VERSION ""

NS_ :

BS_:

BU_: SMART_CORE
VAL_TABLE_ FIRST_TOUCH_COORDINATE_Y_IS 0 "Default Value" ;
VAL_TABLE_ FIRST_TOUCH_COORDINATE_X_IS 0 "Default Value" ;

BO_ 3221225472 VECTOR__INDEPENDENT_SIG_MSG: 0 Vector__XXX
 SG_ VCU_DRIVE_MODE : 0|3@1+ (1,0) [0|7] "" Vector__XXX
 SG_ VCU36_MSG_CNT : 0|4@1+ (1,0) [0|15] "" Vector__XXX
 SG_ FR_SEAT_HEAT_VENT_LEVEL_MBFM : 0|2@1+ (1,0) [0|3] "" Vector__XXX
 SG_ FL_SEAT_HEAT_VENT_LEVEL_MBFM : 0|2@1+ (1,0) [0|3] "" Vector__XXX

BO_ 445 ESC16_10: 7 Vector__XXX
 SG_ STS_ITA : 0|2@1+ (1,0) [0|3] ""  SMART_CORE
 SG_ ITA_ACTIVE : 2|1@1+ (1,0) [0|1] ""  SMART_CORE
 SG_ CCO_WARNING : 11|3@1+ (1,0) [0|7] ""  SMART_CORE
 SG_ CCO_SET_SPD : 8|3@1+ (1,0) [0|7] ""  SMART_CORE
 SG_ CCO_ACTIVE : 5|2@1+ (1,0) [0|3] ""  SMART_CORE

BO_ 1007 VCU15_100: 8 Vector__XXX
 SG_ VCU_TorqueCoasting : 32|16@1+ (0.0625,-2048) [-2045|2045] "Nm"  SMART_CORE
 SG_ VCU_SwitchS2 : 50|1@1+ (1,0) [0|1] ""  SMART_CORE
 SG_ VCU_StCreep : 49|1@1+ (1,0) [0|1] ""  SMART_CORE
 SG_ VCU_StCoasting : 48|1@1+ (1,0) [0|1] ""  SMART_CORE
 SG_ VCU_HVAccPowerConsumption : 16|16@1+ (0.001,0) [0|65] "Kw"  SMART_CORE
 SG_ VCU_EConsPerKm : 0|16@1+ (0.001,0) [0|65.535] "Kwh/km"  SMART_CORE

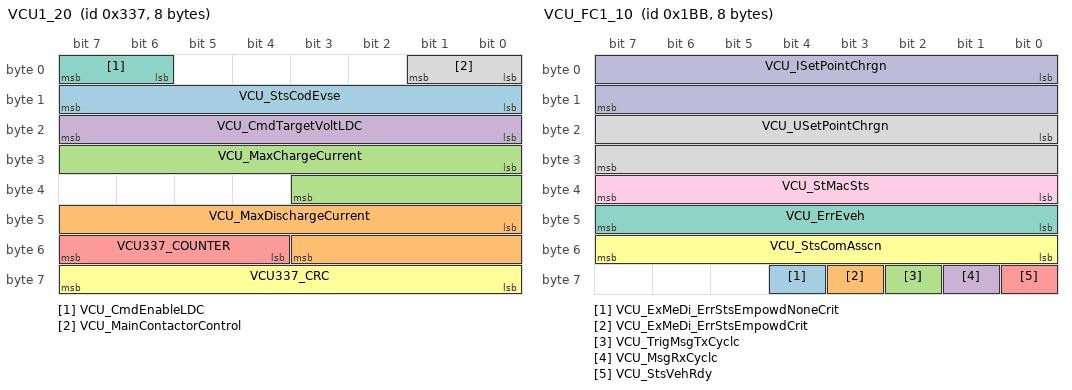
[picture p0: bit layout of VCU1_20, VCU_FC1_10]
BO_ 823 VCU1_20: 8 Vector__XXX
 SG_ VCU_StsCodEvse : 8|8@1+ (1,0) [0|255] ""  SMART_CORE
 SG_ VCU_MaxDischargeCurrent : 40|12@1+ (1,0) [0|4094] "A"  SMART_CORE
 SG_ VCU_MaxChargeCurrent : 24|12@1+ (1,0) [0|4094] "A"  SMART_CORE
 SG_ VCU_CmdTargetVoltLDC : 16|8@1+ (0.1,0) [0|25.5] "V"  SMART_CORE
 SG_ VCU337_COUNTER : 52|4@1+ (1,0) [0|15] "NA"  SMART_CORE
 SG_ VCU337_CRC : 56|8@1+ (1,0) [0|255] "NA"  SMART_CORE
 SG_ VCU_CmdEnableLDC : 6|2@1+ (1,0) [0|3] "NA"  SMART_CORE
 SG_ VCU_MainContactorControl : 0|2@1+ (1,0) [0|3] ""  SMART_CORE

BO_ 443 VCU_FC1_10: 8 Vector__XXX
 SG_ VCU_ExMeDi_ErrStsEmpowdNoneCrit : 60|1@1+ (1,0) [0|1] ""  SMART_CORE
 SG_ VCU_ExMeDi_ErrStsEmpowdCrit : 59|1@1+ (1,0) [0|1] ""  SMART_CORE
 SG_ VCU_TrigMsgTxCyclc : 58|1@1+ (1,0) [0|1] ""  SMART_CORE
 SG_ VCU_MsgRxCyclc : 57|1@1+ (1,0) [0|1] ""  SMART_CORE
 SG_ VCU_StsVehRdy : 56|1@1+ (1,0) [0|1] ""  SMART_CORE
 SG_ VCU_StsComAsscn : 48|8@1+ (1,0) [0|255] ""  SMART_CORE
 SG_ VCU_ErrEveh : 40|8@1+ (1,0) [0|255] ""  SMART_CORE
 SG_ VCU_USetPointChrgn : 16|16@1+ (0.1,0) [0|1500] "V"  SMART_CORE
 SG_ VCU_StMacSts : 32|8@1+ (1,0) [0|255] ""  SMART_CORE
 SG_ VCU_ISetPointChrgn : 0|16@1+ (0.1,0) [0|1000] "A"  SMART_CORE

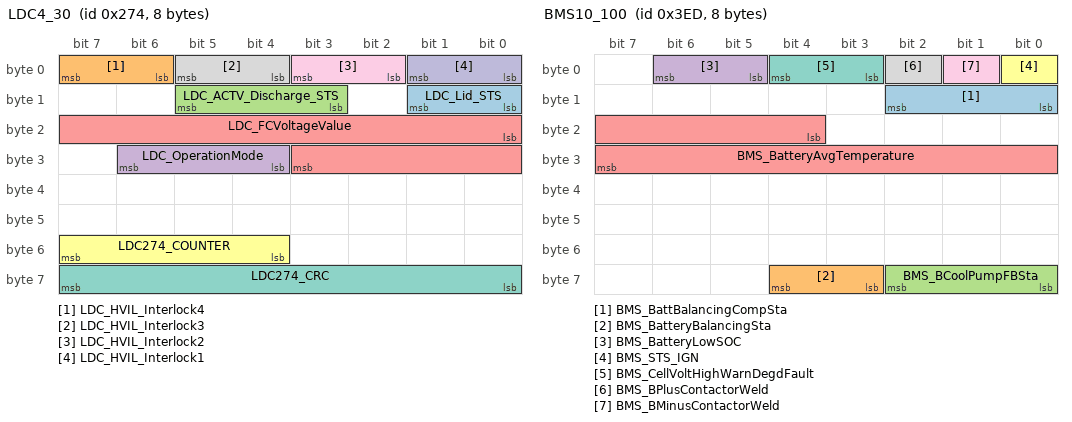
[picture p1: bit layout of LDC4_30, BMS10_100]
BO_ 628 LDC4_30: 8 Vector__XXX
 SG_ LDC_Lid_STS : 8|2@1+ (1,0) [0|3] ""  SMART_CORE
 SG_ LDC_HVIL_Interlock4 : 6|2@1+ (1,0) [0|3] "NA"  SMART_CORE
 SG_ LDC_ACTV_Discharge_STS : 11|3@1+ (1,0) [0|3] ""  SMART_CORE
 SG_ LDC_OperationMode : 28|3@1+ (1,0) [0|7] "NA"  SMART_CORE
 SG_ LDC_FCVoltageValue : 16|12@1+ (0.1,0) [0|500] "V"  SMART_CORE
 SG_ LDC274_COUNTER : 52|4@1+ (1,0) [0|14] "NA"  SMART_CORE
 SG_ LDC274_CRC : 56|8@1+ (1,0) [0|0] "NA"  SMART_CORE
 SG_ LDC_HVIL_Interlock3 : 4|2@1+ (1,0) [0|3] "NA"  SMART_CORE
 SG_ LDC_HVIL_Interlock2 : 2|2@1+ (1,0) [0|3] "NA"  SMART_CORE
 SG_ LDC_HVIL_Interlock1 : 0|2@1+ (1,0) [0|3] "NA"  SMART_CORE

BO_ 991 LDC3_100: 8 Vector__XXX
 SG_ LDC_OPV_Circuit_Error : 22|1@1+ (1,0) [0|1] ""  SMART_CORE
 SG_ LDC_Low_Temp_Shutdown : 23|1@1+ (1,0) [0|1] ""  SMART_CORE
 SG_ LDC_IPV_Circuit_Error : 21|1@1+ (1,0) [0|1] ""  SMART_CORE
 SG_ LDC_INTERNAL_FAIL : 20|1@1+ (1,0) [0|1] ""  SMART_CORE
 SG_ LDC_Input_Over_Current : 19|1@1+ (1,0) [0|1] ""  SMART_CORE
 SG_ LDC_Heat_Sink_Over_Temp_Shutdown : 2|1@1+ (1,0) [0|1] ""  SMART_CORE
 SG_ LDC_HVDC_Side_Relay_Sts : 52|1@1+ (1,0) [0|1] ""  SMART_CORE
 SG_ LDC_CC_CV_STS : 51|1@1+ (1,0) [0|1] ""  SMART_CORE
 SG_ LDC_Burst_Mode_Sts : 50|1@1+ (1,0) [0|1] ""  SMART_CORE
 SG_ LDC_HW_Enable : 49|1@1+ (1,0) [0|1] ""  SMART_CORE
 SG_ LDC_Stage : 46|3@1+ (1,0) [0|7] ""  SMART_CORE
 SG_ LDC_Debounce_Count : 41|3@1+ (1,0) [0|7] ""  SMART_CORE
 SG_ LDC_Vprog_Out_of_Range : 40|1@1+ (1,0) [0|1] ""  SMART_CORE
 SG_ LDC_Watchdog_Failure : 18|1@1+ (1,0) [0|1] ""  SMART_CORE
 SG_ LDC_VCU_Node_Absent : 17|1@1+ (1,0) [0|1] ""  SMART_CORE
 SG_ LDC_Temp_Sensing_Failure : 16|1@1+ (1,0) [0|1] ""  SMART_CORE
 SG_ LDC_IPC_COMM_ERR_OBC : 15|1@1+ (1,0) [0|1] ""  SMART_CORE
 SG_ LDC_EEPROM_Failure : 14|1@1+ (1,0) [0|1] ""  SMART_CORE
 SG_ LDC_Short_Circuit : 13|1@1+ (1,0) [0|1] ""  SMART_CORE
 SG_ LDC_Output_Under_Voltage : 12|1@1+ (1,0) [0|1] ""  SMART_CORE
 SG_ LDC_Output_Over_Voltage : 11|1@1+ (1,0) [0|1] ""  SMART_CORE
 SG_ LDC_Output_Over_Current : 10|1@1+ (1,0) [0|1] ""  SMART_CORE
 SG_ LDC_LPS_Under_Voltage : 9|1@1+ (1,0) [0|1] ""  SMART_CORE
 SG_ LDC_LPS_Over_Voltage : 8|1@1+ (1,0) [0|1] ""  SMART_CORE
 SG_ LDC_Input_Under_Voltage : 7|1@1+ (1,0) [0|1] ""  SMART_CORE
 SG_ LDC_Input_Over_Voltage : 6|1@1+ (1,0) [0|1] ""  SMART_CORE
 SG_ LDC_Heat_Sink_Over_Temp_Wng_2 : 5|1@1+ (1,0) [0|1] ""  SMART_CORE
 SG_ LDC_Heat_Sink_Over_Temp_Wng_1 : 4|1@1+ (1,0) [0|1] ""  SMART_CORE
 SG_ LDC_Heat_Sink_Over_Temp_Wng_0 : 3|1@1+ (1,0) [0|1] ""  SMART_CORE
 SG_ LDC_Amb_Over_Temp_Wng : 1|1@1+ (1,0) [0|1] ""  SMART_CORE
 SG_ LDC_Amb_Over_Temp_Shutdown : 0|1@1+ (1,0) [0|1] ""  SMART_CORE

BO_ 580 LDC2_30: 8 Vector__XXX
 SG_ LDC_OutputVoltageValue : 40|12@1+ (0.01,0) [0|25] "V"  SMART_CORE
 SG_ LDC_OutputCurrent : 16|14@1+ (0.1,0) [0|1000] "A"  SMART_CORE
 SG_ LDC_InputVoltageValue : 0|14@1+ (0.1,0) [0|1000] "V"  SMART_CORE
 SG_ LDC_InputCurrentValue : 32|8@1+ (0.1,0) [0|25] "A"  SMART_CORE

BO_ 989 LDC1_100: 8 Vector__XXX
 SG_ LDC_Primary_Temperature : 32|12@1+ (0.1,-55) [-55|150] "deg C"  SMART_CORE
 SG_ LDC_CoolingRequest : 0|8@1+ (0.5,0) [0|100] "%"  SMART_CORE
 SG_ LDC_MOSFET_Temperature : 48|12@1+ (0.1,-55) [-55|150] "deg C"  SMART_CORE
 SG_ LDC_Secondary_Temperature : 8|12@1+ (0.1,-55) [-55|150] "deg C"  SMART_CORE
 SG_ LDC_ProtectionMode : 28|3@1+ (1,0) [0|7] "NA"  SMART_CORE

BO_ 825 BMS6_100: 8 Vector__XXX
 SG_ BMS_BatteryMinTemperature : 32|12@1+ (0.1,-40) [-40|125] "deg C"  SMART_CORE
 SG_ BMS_BatteryMaxTemperature : 16|12@1+ (0.1,-40) [-40|125] "deg C"  SMART_CORE
 SG_ BMS_Actual_Batt_Heater_Pwr : 8|8@1+ (50,0) [0|8000] "Watts"  SMART_CORE
 SG_ BMS_Req_Batt_Heater_Pwr : 0|8@1+ (50,0) [0|8000] "watts"  SMART_CORE
 SG_ BMS_ChargingStop : 45|1@1+ (1,0) [0|1] ""  SMART_CORE
 SG_ BMS_BCoolingRequest : 30|2@1+ (1,0) [0|3] ""  SMART_CORE

BO_ 352 BMS_IVT_MSG_RESULT_U3: 6 Vector__XXX
 SG_ BMS_IVT_Result_U3 : 0|32@1+ (1,0) [0|45000] "mV"  SMART_CORE

BO_ 345 BMS_IVT_MSG_RESULT_U2: 6 Vector__XXX
 SG_ BMS_IVT_Result_U2 : 0|32@1+ (1,0) [0|45000] "mV"  SMART_CORE

BO_ 344 BMS_IVT_MSG_RESULT_U1: 6 Vector__XXX
 SG_ BMS_IVT_Result_U1 : 0|32@1+ (1,0) [0|45000] "mV"  SMART_CORE

BO_ 979 BMS9_10: 8 Vector__XXX
 SG_ BMS_Discharge_Cycle : 48|16@1+ (1,0) [0|65534] ""  SMART_CORE
 SG_ BMS_Charge_Cycle : 32|16@1+ (1,0) [0|65534] ""  SMART_CORE
 SG_ BMS_ChargePowerAvailable_2 : 16|16@1+ (0.01,0) [0|200] "Kw"  SMART_CORE
 SG_ BMS_ChargePowerAvailable_10 : 0|16@1+ (0.01,0) [0|200] "Kw"  SMART_CORE

BO_ 1005 BMS10_100: 8 Vector__XXX
 SG_ BMS_BattBalancingCompSta : 8|3@1+ (1,0) [0|4] ""  SMART_CORE
 SG_ BMS_BatteryBalancingSta : 59|2@1+ (1,0) [0|1] ""  SMART_CORE
 SG_ BMS_BCoolPumpFBSta : 56|3@1+ (1,0) [0|7] ""  SMART_CORE
 SG_ BMS_BatteryLowSOC : 5|2@1+ (1,0) [0|3] ""  SMART_CORE
 SG_ BMS_BatteryAvgTemperature : 20|12@1+ (0.1,-40) [-40|125] "deg C"  SMART_CORE
 SG_ BMS_STS_IGN : 0|1@1+ (1,0) [0|1] ""  SMART_CORE
 SG_ BMS_CellVoltHighWarnDegdFault : 3|2@1+ (1,0) [0|3] ""  SMART_CORE
 SG_ BMS_BPlusContactorWeld : 2|1@1+ (1,0) [0|1] ""  SMART_CORE
 SG_ BMS_BMinusContactorWeld : 1|1@1+ (1,0) [0|1] ""  SMART_CORE

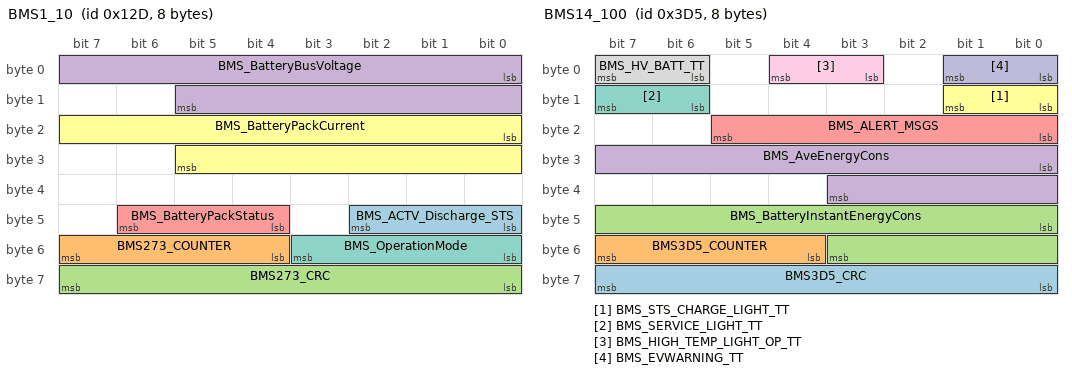
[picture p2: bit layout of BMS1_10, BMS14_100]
BO_ 301 BMS1_10: 8 Vector__XXX
 SG_ BMS_ACTV_Discharge_STS : 40|3@1+ (1,0) [0|4] ""  SMART_CORE
 SG_ BMS273_COUNTER : 52|4@1+ (1,0) [0|14] "NA"  SMART_CORE
 SG_ BMS273_CRC : 56|8@1+ (1,0) [0|0] "NA"  SMART_CORE
 SG_ BMS_BatteryBusVoltage : 0|14@1+ (0.1,0) [0|460] "V"  SMART_CORE
 SG_ BMS_BatteryPackStatus : 44|3@1+ (1,0) [0|7] ""  SMART_CORE
 SG_ BMS_BatteryPackCurrent : 16|14@1+ (0.1,-600) [-600|600] "A"  SMART_CORE
 SG_ BMS_OperationMode : 48|4@1+ (1,0) [0|15] ""  SMART_CORE

BO_ 1003 BMS19_100: 8 Vector__XXX
 SG_ BMS_CellTemp9 m2 : 48|16@1+ (0.1,-50) [-40|125] "degC"  SMART_CORE
 SG_ BMS_CellTemp8 m2 : 32|16@1+ (0.1,-50) [-40|125] "degC"  SMART_CORE
 SG_ BMS_CellTemp7 m2 : 16|16@1+ (0.1,-50) [-40|125] "degC"  SMART_CORE
 SG_ BMS_CellTemp6 m1 : 48|16@1+ (0.1,-50) [-40|125] "degC"  SMART_CORE
 SG_ BMS_CellTemp5 m1 : 32|16@1+ (0.1,-50) [-40|125] "degC"  SMART_CORE
 SG_ BMS_CellTemp4 m1 : 16|16@1+ (0.1,-50) [-40|125] "degC"  SMART_CORE
 SG_ BMS_CellTemp32 m10 : 32|16@1+ (0.1,-50) [-40|125] "degC"  SMART_CORE
 SG_ BMS_CellTemp31 m10 : 16|16@1+ (0.1,-50) [-40|125] "degC"  SMART_CORE
 SG_ BMS_CellTemp30 m9 : 48|16@1+ (0.1,-50) [-40|125] "degC"  SMART_CORE
 SG_ BMS_CellTemp29 m9 : 32|16@1+ (0.1,-50) [-40|125] "degC"  SMART_CORE
 SG_ BMS_CellTemp28 m9 : 16|16@1+ (0.1,-50) [-40|125] "degC"  SMART_CORE
 SG_ BMS_CellTemp27 m8 : 48|16@1+ (0.1,-50) [-40|125] "degC"  SMART_CORE
 SG_ BMS_CellTemp26 m8 : 32|16@1+ (0.1,-50) [-40|125] "degC"  SMART_CORE
 SG_ BMS_CellTemp25 m8 : 16|16@1+ (0.1,-50) [-40|125] "degC"  SMART_CORE
 SG_ BMS_CellTemp24 m7 : 48|16@1+ (0.1,-50) [-40|125] "degC"  SMART_CORE
 SG_ BMS_CellTemp23 m7 : 32|16@1+ (0.1,-50) [-40|125] "degC"  SMART_CORE
 SG_ BMS_CellTemp22 m7 : 16|16@1+ (0.1,-50) [-40|125] "degC"  SMART_CORE
 SG_ BMS_CellTemp21 m6 : 48|16@1+ (0.1,-50) [-40|125] "degC"  SMART_CORE
 SG_ BMS_CellTemp20 m6 : 32|16@1+ (0.1,-50) [-40|125] "degC"  SMART_CORE
 SG_ BMS_CellTemp19 m6 : 16|16@1+ (0.1,-50) [-40|125] "degC"  SMART_CORE
 SG_ BMS_CellTemp18 m5 : 48|16@1+ (0.1,-50) [-40|125] "degC"  SMART_CORE
 SG_ BMS_CellTemp17 m5 : 32|16@1+ (0.1,-50) [-40|125] "degC"  SMART_CORE
 SG_ BMS_CellTemp16 m5 : 16|16@1+ (0.1,-50) [-40|125] "degC"  SMART_CORE
 SG_ BMS_CellTemp15 m4 : 48|16@1+ (0.1,-50) [-40|125] "degC"  SMART_CORE
 SG_ BMS_CellTemp14 m4 : 32|16@1+ (0.1,-50) [-40|125] "degC"  SMART_CORE
 SG_ BMS_CellTemp13 m4 : 16|16@1+ (0.1,-50) [-40|125] "degC"  SMART_CORE
 SG_ BMS_CellTemp12 m3 : 48|16@1+ (0.1,-50) [-40|125] "degC"  SMART_CORE
 SG_ BMS_CellTemp11 m3 : 32|16@1+ (0.1,-50) [-40|125] "degC"  SMART_CORE
 SG_ BMS_CellTemp10 m3 : 16|16@1+ (0.1,-50) [-40|125] "degC"  SMART_CORE
 SG_ BMS_CellTemp3 m0 : 48|16@1+ (0.1,-50) [-40|125] "degC"  SMART_CORE
 SG_ BMS_CellTemp2 m0 : 32|16@1+ (0.1,-50) [-40|125] "degC"  SMART_CORE
 SG_ BMS_CellTemp1 m0 : 16|16@1+ (0.1,-50) [-40|125] "degC"  SMART_CORE
 SG_ BMS_CellTemp_Index M : 0|8@1+ (1,0) [0|255] ""  SMART_CORE

BO_ 981 BMS14_100: 8 Vector__XXX
 SG_ BMS3D5_CRC : 56|8@1+ (1,0) [0|0] "NA"  SMART_CORE
 SG_ BMS3D5_COUNTER : 52|4@1+ (1,0) [0|14] "NA"  SMART_CORE
 SG_ BMS_BatteryInstantEnergyCons : 40|12@1+ (0.1,0) [0|45] "Kwh"  SMART_CORE
 SG_ BMS_AveEnergyCons : 24|12@1+ (0.1,0) [0|45] "Kwh"  SMART_CORE
 SG_ BMS_ALERT_MSGS : 16|6@1+ (1,0) [0|63] ""  SMART_CORE
 SG_ BMS_STS_CHARGE_LIGHT_TT : 8|2@1+ (1,0) [0|3] ""  SMART_CORE
 SG_ BMS_SERVICE_LIGHT_TT : 14|2@1+ (1,0) [0|3] ""  SMART_CORE
 SG_ BMS_HV_BATT_TT : 6|2@1+ (1,0) [0|3] ""  SMART_CORE
 SG_ BMS_HIGH_TEMP_LIGHT_OP_TT : 3|2@1+ (1,0) [0|3] ""  SMART_CORE
 SG_ BMS_EVWARNING_TT : 0|2@1+ (1,0) [0|3] ""  SMART_CORE

BO_ 1949 SBRM_DIAG_RES: 8 Vector__XXX
 SG_ DIAG_SBRM_RES_DATA : 0|64@1+ (1,0) [0|1.8446744074] ""  SMART_CORE

BO_ 1941 SBRM_DIAG_REQ: 8 SMART_CORE
 SG_ DIAG_SBRM_REQ_DATA : 0|64@1+ (1,0) [0|1.8446744074E+019] "" Vector__XXX

BO_ 779 FRM3_TEST_100: 8 Vector__XXX
 SG_ TIME_GAP_FRM : 40|8@1+ (0.1,0) [0|25.5] "sec"  SMART_CORE

BO_ 1852 FDHM_DIAG_RES: 8 Vector__XXX
 SG_ DIAG_FDHM_RES_DATA : 0|64@1+ (1,0) [0|1.8446744074E+019] ""  SMART_CORE

BO_ 1866 APA_DIAG_RES: 8 Vector__XXX
 SG_ DIAG_APA_RES_DATA : 0|64@1+ (1,0) [0|1.8446744074E+019] ""  SMART_CORE

BO_ 1585 ICC1_1000: 8 Vector__XXX
 SG_ TRANSFER_MODE_ICC : 4|2@1+ (1,0) [0|3] ""  SMART_CORE
 SG_ ICC_ALERT_MSG : 8|3@1+ (1,0) [0|7] ""  SMART_CORE

BO_ 1170 MBFM17_200: 8 Vector__XXX
 SG_ IBS_BATT_TEMP_MBFM : 32|16@1+ (0.5,-40) [-40|125] "DegC"  SMART_CORE
 SG_ IBS_BATT_VOLT_MBFM : 16|16@1+ (0.001,0) [4|24] "V"  SMART_CORE
 SG_ IBS_CURRENT_MBFM : 0|16@1+ (1,-1250) [-1250|1250] "Amps"  SMART_CORE

BO_ 1994 ICC_DIAG_RES: 8 Vector__XXX
 SG_ DIAG_ICC_RES_DATA : 0|64@1+ (1,0) [0|1.8446744074E+019] ""  SMART_CORE

BO_ 1169 MBFM16_200: 8 Vector__XXX
 SG_ BATT_RESET_FLG_MBFM : 32|1@1- (1,0) [0|1] ""  SMART_CORE
 SG_ STS_ESS_DEACTIVATION_MBFM : 29|3@1+ (1,0) [0|7] ""  SMART_CORE
 SG_ BATT_CHARGE_LAMP_INDC_MBFM : 27|2@1+ (1,0) [0|3] ""  SMART_CORE
 SG_ ALTERNATOR_MODE_MBFM : 24|3@1+ (1,0) [0|7] ""  SMART_CORE
 SG_ IBS_SOF_MBFM : 16|8@1+ (1,0) [0|100] "%"  SMART_CORE
 SG_ IBS_SOH_MBFM : 8|8@1+ (1,0) [0|100] "%"  SMART_CORE
 SG_ IBS_SOC_MBFM : 0|8@1+ (1,0) [0|100] "%"  SMART_CORE

BO_ 1988 HLCU1_DIAG_REQ: 8 SMART_CORE
 SG_ DIAG_HLCU_REQ_DATA : 0|64@1+ (1,0) [0|1.8446744074E+019] "" Vector__XXX

BO_ 2006 HLCU2_DIAG_REQ: 8 SMART_CORE
 SG_ DIAG_HLCU_REQ_DATA : 0|64@1+ (1,0) [0|1.8446744074E+019] "" Vector__XXX

BO_ 2019 TC_DIAG_REQ: 8 SMART_CORE
 SG_ DIAG_TC_REQ_DATA : 0|64@1+ (1,0) [0|1.8446744074E+019] "" Vector__XXX

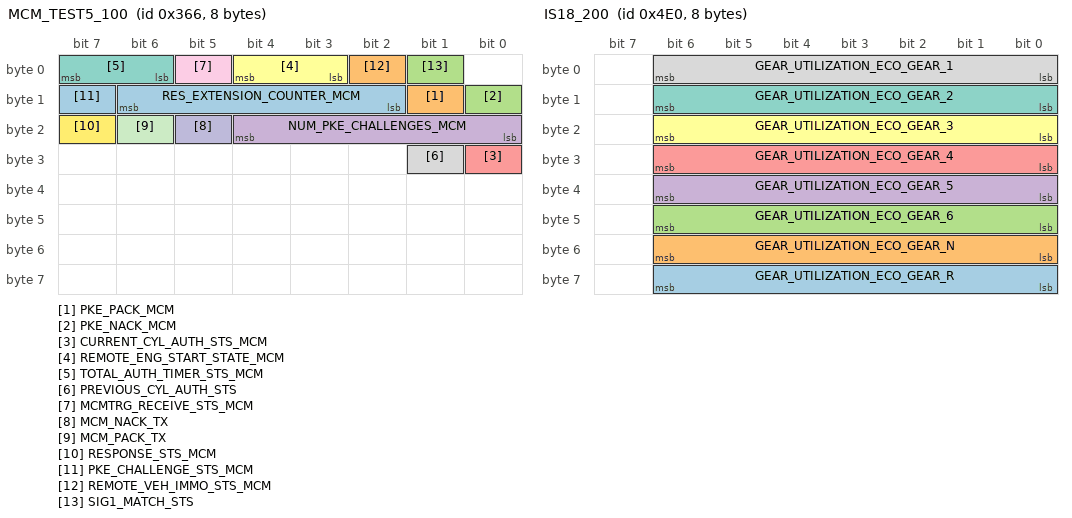
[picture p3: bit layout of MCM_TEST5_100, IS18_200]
BO_ 870 MCM_TEST5_100: 8 SMART_CORE
 SG_ RES_EXTENSION_COUNTER_MCM : 10|5@1+ (1,0) [0|31] "" Vector__XXX
 SG_ PKE_PACK_MCM : 9|1@1+ (1,0) [0|0] "" Vector__XXX
 SG_ PKE_NACK_MCM : 8|1@1+ (1,0) [0|0] "" Vector__XXX
 SG_ NUM_PKE_CHALLENGES_MCM : 16|5@1+ (1,0) [0|31] "" Vector__XXX
 SG_ CURRENT_CYL_AUTH_STS_MCM : 24|1@1+ (1,0) [0|1] "" Vector__XXX
 SG_ REMOTE_ENG_START_STATE_MCM : 3|2@1+ (1,0) [0|3] "" Vector__XXX
 SG_ TOTAL_AUTH_TIMER_STS_MCM : 6|2@1+ (1,0) [0|0] "" Vector__XXX
 SG_ PREVIOUS_CYL_AUTH_STS : 25|1@1+ (1,0) [0|1] "" Vector__XXX
 SG_ MCMTRG_RECEIVE_STS_MCM : 5|1@1+ (1,0) [0|1] "" Vector__XXX
 SG_ MCM_NACK_TX : 21|1@1+ (1,0) [0|1] "" Vector__XXX
 SG_ MCM_PACK_TX : 22|1@1+ (1,0) [0|1] "" Vector__XXX
 SG_ RESPONSE_STS_MCM : 23|1@1+ (1,0) [0|1] "" Vector__XXX
 SG_ PKE_CHALLENGE_STS_MCM : 15|1@1+ (1,0) [0|1] "" Vector__XXX
 SG_ REMOTE_VEH_IMMO_STS_MCM : 2|1@1+ (1,0) [0|1] "" Vector__XXX
 SG_ SIG1_MATCH_STS : 1|1@1+ (1,0) [0|1] "" Vector__XXX

BO_ 1654 MCM4_1000: 8 SMART_CORE
 SG_ UPDATE_REPROG_USER_AUTH : 2|2@1+ (1,0) [0|3] "" Vector__XXX
 SG_ UPDATE_DOWNLOAD_USER_AUTH : 0|2@1+ (1,0) [0|3] "" Vector__XXX
 SG_ MCM4_CRC : 56|8@1+ (1,0) [0|255] "" Vector__XXX
 SG_ MCM4_CNT : 52|4@1+ (1,0) [0|15] "" Vector__XXX

BO_ 1958 SCM_DIAG_REQ: 8 SMART_CORE
 SG_ DIAG_SCM_REQ_DATA : 0|64@1+ (1,0) [0|1.8446744074E+019] "" Vector__XXX

BO_ 1959 FVC_DIAG_REQ: 8 SMART_CORE
 SG_ DIAG_FVC_REQ_DATA : 0|64@1+ (1,0) [0|1.8446744074E+019] "" Vector__XXX

BO_ 1842 FRM_DIAG_REQ: 8 SMART_CORE
 SG_ DIAG_FRM_REQ_DATA : 0|64@1+ (1,0) [0|1.8446744074E+019] "" Vector__XXX

BO_ 1986 ICC_DIAG_REQ: 8 SMART_CORE
 SG_ DIAG_ICC_REQ_DATA : 0|64@1+ (1,0) [0|1.8446744074E+019] "" Vector__XXX

BO_ 1858 APA_DIAG_REQ: 8 SMART_CORE
 SG_ DIAG_APA_REQ_DATA : 0|64@1+ (1,0) [0|1.8446744074E+019] "" Vector__XXX

BO_ 1859 AMP_DIAG_REQ: 8 SMART_CORE
 SG_ DIAG_AMP_REQ_DATA : 0|64@1+ (1,0) [0|1.8446744074E+019] "" Vector__XXX

BO_ 1248 IS18_200: 8 SMART_CORE
 SG_ GEAR_UTILIZATION_ECO_GEAR_R : 56|7@1+ (1,0) [0|100] "perKM" Vector__XXX
 SG_ GEAR_UTILIZATION_ECO_GEAR_N : 48|7@1+ (1,0) [0|100] "perKM" Vector__XXX
 SG_ GEAR_UTILIZATION_ECO_GEAR_6 : 40|7@1+ (1,0) [0|100] "perKM" Vector__XXX
 SG_ GEAR_UTILIZATION_ECO_GEAR_5 : 32|7@1+ (1,0) [0|100] "perKM" Vector__XXX
 SG_ GEAR_UTILIZATION_ECO_GEAR_4 : 24|7@1+ (1,0) [0|100] "perKM" Vector__XXX
 SG_ GEAR_UTILIZATION_ECO_GEAR_3 : 16|7@1+ (1,0) [0|100] "perKM" Vector__XXX
 SG_ GEAR_UTILIZATION_ECO_GEAR_2 : 8|7@1+ (1,0) [0|100] "perKM" Vector__XXX
 SG_ GEAR_UTILIZATION_ECO_GEAR_1 : 0|7@1+ (1,0) [0|100] "perKM" Vector__XXX

BO_ 2017 TCU_DIAG_REQ: 8 SMART_CORE
 SG_ DIAG_TCU_REQ_DATA : 0|64@1+ (1,0) [0|1.8446744074E+019] "" Vector__XXX

BO_ 1955 WLC_DIAG_REQ: 8 SMART_CORE
 SG_ DIAG_WLC_REQ_DATA : 0|64@1+ (1,0) [0|1.84467440737096E+019] "" Vector__XXX

BO_ 1280 IC11_500: 8 SMART_CORE
 SG_ IC11_MSG_CNT : 52|4@1+ (1,0) [0|15] "" Vector__XXX
 SG_ IC11_CRC : 56|8@1+ (1,0) [0|255] "" Vector__XXX
 SG_ IC_DRV_MOD_REQ : 0|3@1+ (1,0) [0|7] "" Vector__XXX
 SG_ MODE_SELECTION_SWT : 19|4@1+ (1,0) [0|15] "" Vector__XXX
 SG_ IC_STEERING_MODE_REQ : 16|3@1+ (1,0) [0|7] "" Vector__XXX

BO_ 154 MCM_WAKEUP: 8 SMART_CORE
 SG_ MCM_WAKEUP_REASON : 0|16@1+ (1,0) [0|65535] "" Vector__XXX

BO_ 955 MCM_SLEEP: 8 SMART_CORE
 SG_ RESERVED_3 : 0|64@1+ (1,0) [0|1.8446744074E+019] "" Vector__XXX

BO_ 957 MCM_ACTIVE: 8 SMART_CORE
 SG_ RESERVED_3 : 0|64@1+ (1,0) [0|1.8446744074E+019] "" Vector__XXX

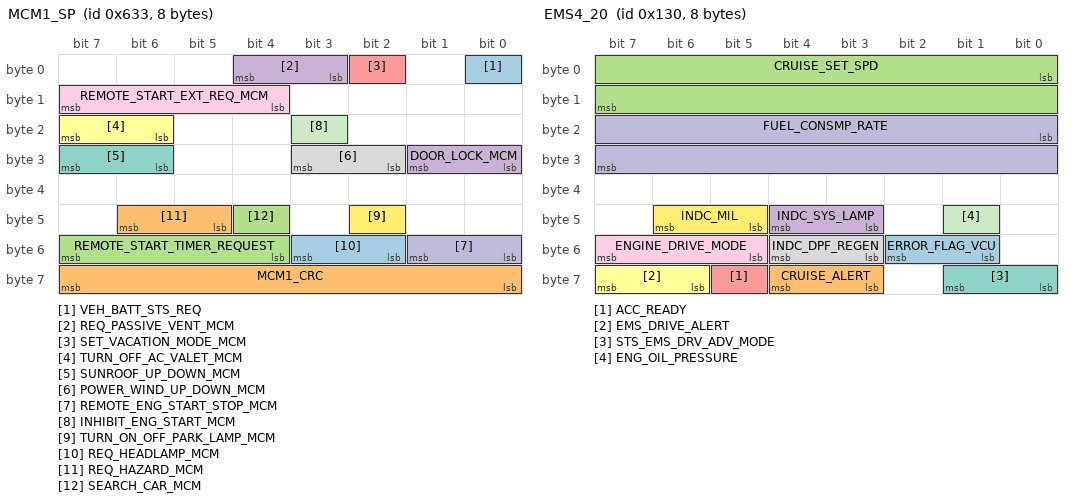
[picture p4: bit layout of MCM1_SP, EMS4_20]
BO_ 1587 MCM1_SP: 8 SMART_CORE
 SG_ VEH_BATT_STS_REQ : 0|1@1+ (1,0) [0|1] "" Vector__XXX
 SG_ MCM1_CRC : 56|8@1+ (1,0) [0|0] "" Vector__XXX
 SG_ REMOTE_START_TIMER_REQUEST : 52|4@1+ (1,0) [0|15] "minutes" Vector__XXX
 SG_ REQ_PASSIVE_VENT_MCM : 3|2@1+ (1,0) [0|3] "" Vector__XXX
 SG_ SET_VACATION_MODE_MCM : 2|1@1+ (1,0) [0|1] "" Vector__XXX
 SG_ TURN_OFF_AC_VALET_MCM : 22|2@1+ (1,0) [0|3] "" Vector__XXX
 SG_ SUNROOF_UP_DOWN_MCM : 30|2@1+ (1,0) [0|3] "" Vector__XXX
 SG_ POWER_WIND_UP_DOWN_MCM : 26|2@1+ (1,0) [0|3] "" Vector__XXX
 SG_ REMOTE_START_EXT_REQ_MCM : 12|4@1+ (1,0) [0|15] "" Vector__XXX
 SG_ REMOTE_ENG_START_STOP_MCM : 48|2@1+ (1,0) [0|3] "" Vector__XXX
 SG_ INHIBIT_ENG_START_MCM : 19|1@1+ (1,0) [0|1] "" Vector__XXX
 SG_ TURN_ON_OFF_PARK_LAMP_MCM : 42|1@1+ (1,0) [0|1] "" Vector__XXX
 SG_ REQ_HEADLAMP_MCM : 50|2@1+ (1,0) [0|3] "" Vector__XXX
 SG_ REQ_HAZARD_MCM : 45|2@1+ (1,0) [0|3] "" Vector__XXX
 SG_ SEARCH_CAR_MCM : 44|1@1+ (1,0) [0|1] "" Vector__XXX
 SG_ DOOR_LOCK_MCM : 24|2@1+ (1,0) [0|3] "" Vector__XXX

BO_ 1856 FATC_DIAG_REQ: 8 SMART_CORE
 SG_ DIAG_FATC_REQ_DATA : 0|64@1+ (1,0) [0|1.8446744074E+019] "" Vector__XXX

BO_ 1144 SBRM1_100: 8 Vector__XXX
 SG_ PSGR_REAR_SEAT_BELT_SBRM : 2|6@1+ (1,0) [0|63] ""  SMART_CORE

BO_ 1963 WLC_DIAG_RES: 8 Vector__XXX
 SG_ DIAG_WLC_RES_DATA : 0|64@1+ (1,0) [0|1.84467440737096E+019] ""  SMART_CORE

BO_ 956 WLC_ACTIVE: 8 Vector__XXX
 SG_ RESERVED_2 : 0|64@1+ (1,0) [0|1.84467440737096E+019] ""  SMART_CORE

BO_ 786 EMS13_200: 8 Vector__XXX
 SG_ IBS_CURRENT : 0|16@1+ (1,-1250) [-1250|1250] "Amps"  SMART_CORE
 SG_ IBS_BATT_TEMP : 32|16@1+ (0.5,-40) [-40|125] "DegC"  SMART_CORE
 SG_ IBS_BATT_VOLT : 16|16@1+ (0.001,0) [4|24] "V"  SMART_CORE

BO_ 784 EMS12_200: 8 Vector__XXX
 SG_ BATT_RESET_FLG : 32|1@1- (1,0) [0|1] ""  SMART_CORE
 SG_ STS_ESS_DEACTIVATION : 29|3@1+ (1,0) [0|7] ""  SMART_CORE
 SG_ IBS_SOC : 0|8@1+ (1,0) [0|100] "%"  SMART_CORE
 SG_ ALTERNATOR_MODE : 24|3@1+ (1,0) [0|7] ""  SMART_CORE
 SG_ IBS_SOF : 16|8@1+ (1,0) [0|100] "%"  SMART_CORE
 SG_ IBS_SOH : 8|8@1+ (1,0) [0|100] "%"  SMART_CORE
 SG_ BATT_CHARGE_LAMP_INDC : 27|2@1+ (1,0) [0|3] ""  SMART_CORE

BO_ 563 EMS29_100: 8 Vector__XXX
 SG_ UREA_LEVEL_PERCENTAGE : 40|8@1+ (1,0) [0|100] "%"  SMART_CORE
 SG_ INCORRECT_DEF : 27|3@1+ (1,0) [0|4] ""  SMART_CORE
 SG_ DIST_DEF_EMPTY : 8|16@1+ (1,0) [0|2400] "km"  SMART_CORE
 SG_ DEF_LEVEL : 32|3@1+ (1,0) [0|4] ""  SMART_CORE
 SG_ DEF_DOSING_MALFUNC : 24|3@1+ (1,0) [0|4] ""  SMART_CORE
 SG_ INDC_REGEN : 30|2@1+ (1,0) [0|3] ""  SMART_CORE
 SG_ STS_DEF : 0|8@1+ (1,0) [0|255] ""  SMART_CORE

BO_ 295 EMS21_10: 8 Vector__XXX
 SG_ ACC_PED_ACTUAL : 32|8@1+ (0.4,0) [0|100] "%"  SMART_CORE
 SG_ ENG_LOSSES : 40|11@1+ (1,-1024) [-1024|1021] "NM"  SMART_CORE
 SG_ EMS21_MSG_CNT : 52|4@1+ (1,0) [0|15] ""  SMART_CORE
 SG_ EMS21_CRC : 56|8@1+ (1,0) [0|255] ""  SMART_CORE
 SG_ BRK_PEDAL1 : 27|2@1+ (1,0) [0|3] ""  SMART_CORE

BO_ 375 AMT6_20: 8 Vector__XXX
 SG_ TGS_LEVER_AMT : 16|4@1+ (1,0) [0|15] ""  SMART_CORE
 SG_ AMT_BUZZER : 34|1@1+ (1,0) [0|1] ""  SMART_CORE
 SG_ AMT_MIL : 22|2@1+ (1,0) [0|3] ""  SMART_CORE
 SG_ ALERT_AMT : 29|3@1+ (1,0) [0|7] ""  SMART_CORE

BO_ 294 EMS8_10: 8 Vector__XXX
 SG_ HYBRID_LAMP_INDC : 11|2@1+ (1,0) [0|2] ""  SMART_CORE
 SG_ MAX_ALL_TRQ : 0|11@1+ (1,-1024) [-1024|1022] "Nm"  SMART_CORE
 SG_ GEAR_UP_FLG : 13|1@1+ (1,0) [0|1] ""  SMART_CORE
 SG_ GEAR_DOWN_FLG : 14|1@1+ (1,0) [0|1] ""  SMART_CORE
 SG_ MIN_ALL_TRQ : 16|11@1+ (1,-1024) [-1024|1022] "Nm"  SMART_CORE
 SG_ TARGET_GEAR_GSI : 27|4@1+ (1,0) [0|15] ""  SMART_CORE

BO_ 304 EMS4_20: 8 Vector__XXX
 SG_ ERROR_FLAG_VCU : 49|2@1+ (1,0) [0|3] ""  SMART_CORE
 SG_ CRUISE_ALERT : 59|2@1+ (1,0) [0|3] ""  SMART_CORE
 SG_ CRUISE_SET_SPD : 0|16@1+ (0.015625,0) [0|300] "kmph"  SMART_CORE
 SG_ INDC_SYS_LAMP : 43|2@1+ (1,0) [0|3] ""  SMART_CORE
 SG_ ACC_READY : 61|1@1+ (1,0) [0|1] ""  SMART_CORE
 SG_ EMS_DRIVE_ALERT : 62|2@1+ (1,0) [0|3] ""  SMART_CORE
 SG_ STS_EMS_DRV_ADV_MODE : 56|2@1+ (1,0) [0|3] ""  SMART_CORE
 SG_ INDC_DPF_REGEN : 51|2@1+ (1,0) [0|3] ""  SMART_CORE
 SG_ ENGINE_DRIVE_MODE : 53|3@1+ (1,0) [0|7] ""  SMART_CORE
 SG_ FUEL_CONSMP_RATE : 16|16@1+ (1,0) [0|65534] "ul/20ms"  SMART_CORE
 SG_ ENG_OIL_PRESSURE : 41|1@1+ (1,0) [0|1] ""  SMART_CORE
 SG_ INDC_MIL : 45|2@1+ (1,0) [0|3] ""  SMART_CORE

BO_ 1638 IS16_1000: 8 SMART_CORE
 SG_ ASD_TORQUE : 40|7@1+ (1,0) [0|100] "%" Vector__XXX
 SG_ ASD_POWER : 32|7@1+ (1,0) [0|100] "%" Vector__XXX
 SG_ INDC_ROLL_IS : 24|7@1+ (1,-62) [-62|65] "Deg" Vector__XXX
 SG_ INDC_PITCH_IS : 17|7@1+ (1,-62) [-62|65] "Deg" Vector__XXX
 SG_ ALTIMETER : 0|13@1+ (1,0) [0|8192] "m" Vector__XXX
 SG_ COMPASS_DIRECTION : 13|4@1+ (1,0) [0|15] "" Vector__XXX

BO_ 1079 IS13_500: 8 SMART_CORE
 SG_ ESS_DURATION : 8|12@1+ (0.1,0) [0|409.5] "MIN" Vector__XXX
 SG_ IDLING_DURATION : 0|8@1+ (1,0) [0|254] "min" Vector__XXX

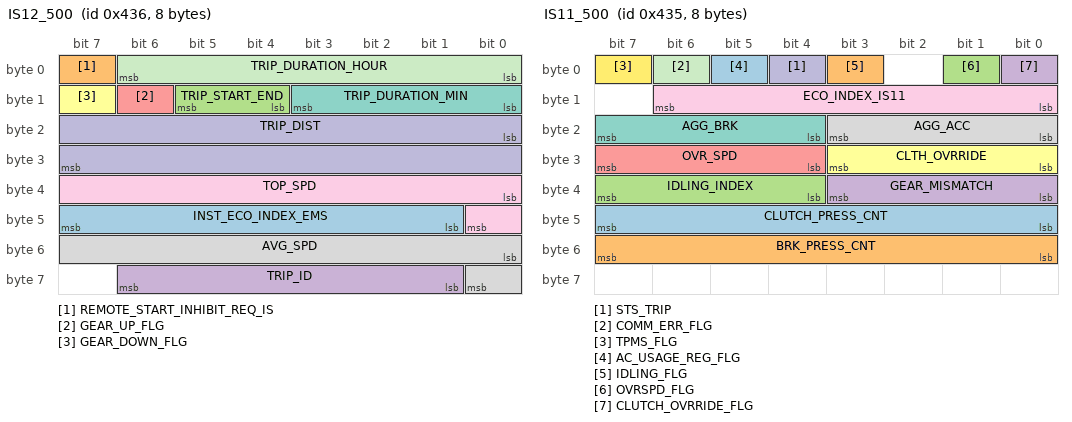
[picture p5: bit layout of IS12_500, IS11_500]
BO_ 1078 IS12_500: 8 SMART_CORE
 SG_ INST_ECO_INDEX_EMS : 41|7@1+ (1,0) [0|100] "" Vector__XXX
 SG_ REMOTE_START_INHIBIT_REQ_IS : 7|1@1+ (1,0) [0|1] "" Vector__XXX
 SG_ TRIP_START_END : 12|2@1+ (1,0) [0|3] "" Vector__XXX
 SG_ TRIP_ID : 57|6@1+ (1,0) [0|63] "" Vector__XXX
 SG_ GEAR_UP_FLG : 14|1@1+ (1,0) [0|1] "" Vector__XXX
 SG_ GEAR_DOWN_FLG : 15|1@1+ (1,0) [0|1] "" Vector__XXX
 SG_ TRIP_DURATION_MIN : 8|4@1+ (1,0) [0|14] "min" Vector__XXX
 SG_ AVG_SPD : 48|9@1+ (1,0) [0|300] "KMPH" Vector__XXX
 SG_ TOP_SPD : 32|9@1+ (1,0) [0|300] "kmph" Vector__XXX
 SG_ TRIP_DIST : 16|16@1+ (0.1,0) [0|6553.4] "km" Vector__XXX
 SG_ TRIP_DURATION_HOUR : 0|7@1+ (1,0) [0|126] "Hours" Vector__XXX

BO_ 1406 IS14_200: 8 SMART_CORE
 SG_ FUEL_ECONOMY_ECO : 26|5@1+ (1,0) [0|0] "" Vector__XXX
 SG_ TRIP_TAGGING_ECO : 56|3@1+ (1,0) [0|0] "" Vector__XXX
 SG_ AGG_BRK_COUNT_ECO : 48|7@1+ (1,0) [0|100] "perKM" Vector__XXX
 SG_ AGG_ACC_COUNT_ECO : 32|7@1+ (1,0) [0|100] "perKM" Vector__XXX
 SG_ GEAR_UTILIZATION_ECO : 40|7@1+ (1,0) [0|100] "perKM" Vector__XXX
 SG_ AUDIO_SOURCE : 19|4@1+ (1,0) [0|15] "" Vector__XXX

BO_ 1077 IS11_500: 8 SMART_CORE
 SG_ CLUTCH_PRESS_CNT : 40|8@1+ (1,0) [0|253] "" Vector__XXX
 SG_ BRK_PRESS_CNT : 48|8@1+ (1,0) [0|253] "" Vector__XXX
 SG_ IDLING_INDEX : 36|4@1+ (1,0) [0|15] "" Vector__XXX
 SG_ GEAR_MISMATCH : 32|4@1+ (1,0) [0|15] "" Vector__XXX
 SG_ OVR_SPD : 28|4@1+ (1,0) [0|15] "" Vector__XXX
 SG_ CLTH_OVRRIDE : 24|4@1+ (1,0) [0|15] "" Vector__XXX
 SG_ AGG_BRK : 20|4@1+ (1,0) [0|15] "" Vector__XXX
 SG_ AGG_ACC : 16|4@1+ (1,0) [0|15] "" Vector__XXX
 SG_ ECO_INDEX_IS11 : 8|7@1+ (1,0) [0|127] "" Vector__XXX
 SG_ STS_TRIP : 4|1@1+ (1,0) [0|1] "" Vector__XXX
 SG_ COMM_ERR_FLG : 6|1@1+ (1,0) [0|1] "" Vector__XXX
 SG_ TPMS_FLG : 7|1@1+ (1,0) [0|1] "" Vector__XXX
 SG_ AC_USAGE_REG_FLG : 5|1@1+ (1,0) [0|1] "" Vector__XXX
 SG_ IDLING_FLG : 3|1@1+ (1,0) [0|1] "" Vector__XXX
 SG_ OVRSPD_FLG : 1|1@1+ (1,0) [0|1] "" Vector__XXX
 SG_ CLUTCH_OVRRIDE_FLG : 0|1@1+ (1,0) [0|1] "" Vector__XXX

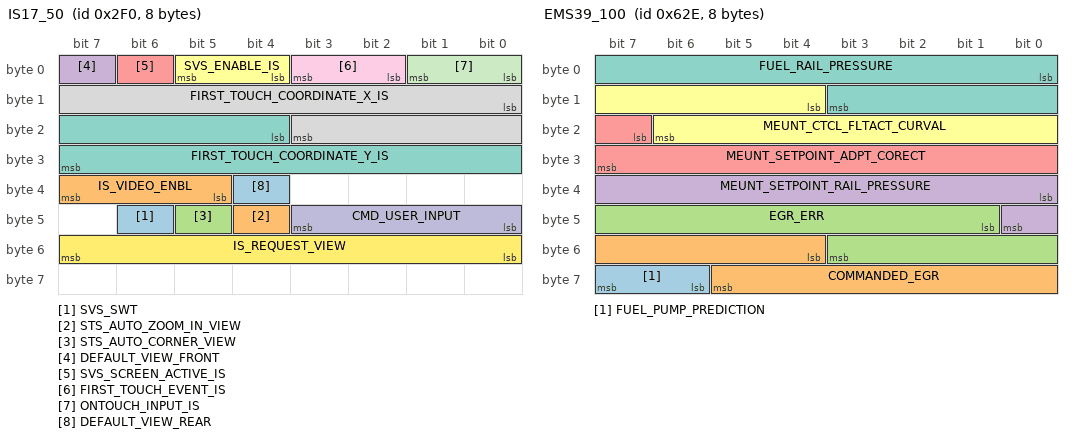
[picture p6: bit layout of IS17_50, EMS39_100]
BO_ 752 IS17_50: 8 SMART_CORE
 SG_ SVS_SWT : 46|1@1+ (1,0) [0|1] "" Vector__XXX
 SG_ STS_AUTO_ZOOM_IN_VIEW : 44|1@1+ (1,0) [0|1] "" Vector__XXX
 SG_ STS_AUTO_CORNER_VIEW : 45|1@1+ (1,0) [0|1] "" Vector__XXX
 SG_ DEFAULT_VIEW_FRONT : 7|1@1+ (1,0) [0|0] "" Vector__XXX
 SG_ SVS_SCREEN_ACTIVE_IS : 6|1@1+ (1,0) [0|1] "" Vector__XXX
 SG_ SVS_ENABLE_IS : 4|2@1+ (1,0) [0|0] "" Vector__XXX
 SG_ FIRST_TOUCH_COORDINATE_Y_IS : 20|12@1+ (0.025,0) [0|100] "%" Vector__XXX
 SG_ FIRST_TOUCH_COORDINATE_X_IS : 8|12@1+ (0.025,0) [0|100] "%" Vector__XXX
 SG_ FIRST_TOUCH_EVENT_IS : 2|2@1+ (1,0) [0|3] "" Vector__XXX
 SG_ CMD_USER_INPUT : 40|4@1+ (1,0) [0|15] "" Vector__XXX
 SG_ ONTOUCH_INPUT_IS : 0|2@1+ (1,0) [0|3] "" Vector__XXX
 SG_ IS_REQUEST_VIEW : 48|8@1+ (1,0) [0|255] "" Vector__XXX
 SG_ DEFAULT_VIEW_REAR : 36|1@1+ (1,0) [0|0] "" Vector__XXX
 SG_ IS_VIDEO_ENBL : 37|3@1+ (1,0) [0|7] "" Vector__XXX

BO_ 1584 EMS42_100: 8 Vector__XXX
 SG_ NOX_UPSTR_MDL : 0|9@1+ (4,0) [0|2000] ""  SMART_CORE

BO_ 1595 EMS44_100: 8 Vector__XXX
 SG_ KNOCK_SIGNALS_0 : 0|8@1+ (1,0) [0|255] ""  SMART_CORE
 SG_ KNOCK_SIGNALS_1 : 8|8@1+ (1,0) [0|255] ""  SMART_CORE
 SG_ KNOCK_SIGNALS_2 : 16|8@1+ (1,0) [0|255] ""  SMART_CORE
 SG_ KNOCK_SIGNALS_3 : 24|8@1+ (1,0) [0|255] ""  SMART_CORE
 SG_ MASS_AIR_FLOW : 32|8@1+ (4,0) [0|1020] ""  SMART_CORE
 SG_ MISFIRE_DETECT_THRESHOLD : 40|8@1+ (64,-12000) [-12000|4000] ""  SMART_CORE
 SG_ MISFIRE_SUM_A : 48|8@1+ (1,0) [0|255] ""  SMART_CORE
 SG_ MISFIRE_SUM_B : 56|8@1+ (1,0) [0|255] ""  SMART_CORE

BO_ 1596 EMS45_100: 8 Vector__XXX
 SG_ MISFIRE_CTR_A_0 : 0|8@1+ (1,0) [0|255] ""  SMART_CORE
 SG_ MISFIRE_CTR_A_1 : 8|8@1+ (1,0) [0|255] ""  SMART_CORE
 SG_ MISFIRE_CTR_A_2 : 16|8@1+ (1,0) [0|255] ""  SMART_CORE
 SG_ MISFIRE_CTR_A_3 : 24|8@1+ (1,0) [0|255] ""  SMART_CORE
 SG_ MISFIRE_CTR_B_0 : 32|8@1+ (1,0) [0|255] ""  SMART_CORE
 SG_ MISFIRE_CTR_B_1 : 40|8@1+ (1,0) [0|255] ""  SMART_CORE
 SG_ MISFIRE_CTR_B_2 : 48|8@1+ (1,0) [0|255] ""  SMART_CORE
 SG_ MISFIRE_CTR_B_3 : 56|8@1+ (1,0) [0|255] ""  SMART_CORE

BO_ 1428 ESC15_1000: 8 Vector__XXX
 SG_ BRAKE_PREDICTION_STS : 0|2@1+ (1,0) [0|3] ""  SMART_CORE

BO_ 661 TC_NSM: 8 Vector__XXX
 SG_ RESERVED_TC : 0|64@1+ (1,0) [0|0] ""  SMART_CORE

BO_ 922 SVS1_10: 8 Vector__XXX
 SG_ SVS_VIEW_REQUEST_IC : 10|1@1+ (1,0) [0|1] ""  SMART_CORE
 SG_ SVS_VIEW_REQUEST_IS : 9|1@1+ (1,0) [0|1] ""  SMART_CORE
 SG_ SVS_INFO : 8|1@1+ (1,0) [0|1] ""  SMART_CORE
 SG_ SVS_GUIDED_VOICE_REQ : 0|4@1+ (1,0) [0|15] ""  SMART_CORE

BO_ 1867 AMP_DIAG_RES: 8 Vector__XXX
 SG_ DIAG_AMP_RES_DATA : 0|64@1+ (1,0) [0|1.8446744074E+019] ""  SMART_CORE

BO_ 1582 EMS39_100: 8 Vector__XXX
 SG_ FUEL_PUMP_PREDICTION : 62|2@1+ (1,0) [0|0] ""  SMART_CORE
 SG_ COMMANDED_EGR : 52|10@1+ (0.1,-30) [-30|50] ""  SMART_CORE
 SG_ EGR_ERR : 41|11@1- (0.1,-60) [-60|60] ""  SMART_CORE
 SG_ MEUNT_SETPOINT_RAIL_PRESSURE : 32|9@1+ (10,-2000) [-2000|2000] ""  SMART_CORE
 SG_ MEUNT_SETPOINT_ADPT_CORECT : 23|9@1+ (10,-2000) [-2000|2000] ""  SMART_CORE
 SG_ MEUNT_CTCL_FLTACT_CURVAL : 12|11@1+ (1,-100) [-100|1000] ""  SMART_CORE
 SG_ FUEL_RAIL_PRESSURE : 0|12@1+ (1000,-100000) [-100000|2000000] ""  SMART_CORE

BO_ 1965 SVS_DIAG_RES: 8 Vector__XXX
 SG_ DIAG_SVS_RES_DATA : 0|64@1+ (1,0) [0|1.8446744074E+019] ""  SMART_CORE

BO_ 1967 FVC_DIAG_RES: 8 Vector__XXX
 SG_ DIAG_FVC_RES_DATA : 0|64@1+ (1,0) [0|1.8446744074] ""  SMART_CORE

BO_ 2014 HLCU2_DIAG_RES: 8 Vector__XXX
 SG_ DIAG_HLCU_RES_DATA : 0|64@1+ (1,0) [0|1.8446744074E+019] ""  SMART_CORE

BO_ 1996 HLCU1_DIAG_RES: 8 Vector__XXX
 SG_ DIAG_HLCU_RES_DATA : 0|64@1+ (1,0) [0|1.8446744074E+019] ""  SMART_CORE

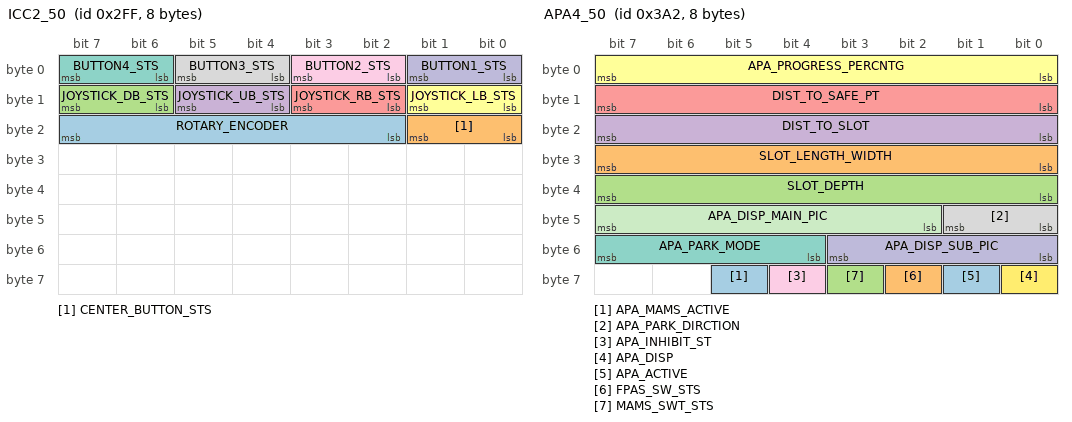
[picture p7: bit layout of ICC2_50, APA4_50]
BO_ 767 ICC2_50: 8 Vector__XXX
 SG_ ROTARY_ENCODER : 18|6@1+ (1,0) [0|64] ""  SMART_CORE
 SG_ CENTER_BUTTON_STS : 16|2@1+ (1,0) [0|3] ""  SMART_CORE
 SG_ JOYSTICK_DB_STS : 14|2@1+ (1,0) [0|3] ""  SMART_CORE
 SG_ JOYSTICK_UB_STS : 12|2@1+ (1,0) [0|3] ""  SMART_CORE
 SG_ JOYSTICK_RB_STS : 10|2@1+ (1,0) [0|3] ""  SMART_CORE
 SG_ JOYSTICK_LB_STS : 8|2@1+ (1,0) [0|3] ""  SMART_CORE
 SG_ BUTTON4_STS : 6|2@1+ (1,0) [0|3] ""  SMART_CORE
 SG_ BUTTON3_STS : 4|2@1+ (1,0) [0|3] ""  SMART_CORE
 SG_ BUTTON2_STS : 2|2@1+ (1,0) [0|3] ""  SMART_CORE
 SG_ BUTTON1_STS : 0|2@1+ (1,0) [0|3] ""  SMART_CORE

BO_ 917 FVC1_100: 8 Vector__XXX
 SG_ FVC_OPERATION_STATE : 4|3@1+ (1,0) [0|5] ""  SMART_CORE
 SG_ FVC_BUTTON_GROUP : 0|4@1+ (1,0) [0|9] ""  SMART_CORE

BO_ 2027 TC_DIAG_RES: 8 Vector__XXX
 SG_ DIAG_TC_RES_DATA : 0|64@1+ (1,0) [0|1.8446744074E+019] ""  SMART_CORE

BO_ 1966 SCM_DIAG_RES: 8 Vector__XXX
 SG_ DIAG_SCM_RES_DATA : 0|64@1+ (1,0) [0|1.8446744074] ""  SMART_CORE

BO_ 1850 FRM_DIAG_RES: 8 Vector__XXX
 SG_ DIAG_FRM_RES_DATA : 0|64@1+ (1,0) [0|1.8446744074E+019] ""  SMART_CORE

BO_ 666 FRM_NSM: 8 Vector__XXX
 SG_ RESERVED_FRM : 0|64@1+ (1,0) [0|0] ""  SMART_CORE

BO_ 930 APA4_50: 8 Vector__XXX
 SG_ APA_MAMS_ACTIVE : 61|1@1+ (1,0) [0|1] ""  SMART_CORE
 SG_ SLOT_LENGTH_WIDTH : 24|8@1+ (5,0) [0|800] "cm"  SMART_CORE
 SG_ SLOT_DEPTH : 32|8@1+ (2,0) [0|500] "cm"  SMART_CORE
 SG_ DIST_TO_SLOT : 16|8@1+ (5,0) [0|1000] "cm"  SMART_CORE
 SG_ DIST_TO_SAFE_PT : 8|8@1+ (5,0) [0|1000] "cm"  SMART_CORE
 SG_ APA_PROGRESS_PERCNTG : 0|8@1+ (1,0) [0|100] "%"  SMART_CORE
 SG_ APA_PARK_MODE : 52|4@1+ (1,0) [0|15] ""  SMART_CORE
 SG_ APA_PARK_DIRCTION : 40|2@1+ (1,0) [0|3] ""  SMART_CORE
 SG_ APA_INHIBIT_ST : 60|1@1+ (1,0) [0|1] ""  SMART_CORE
 SG_ APA_DISP_SUB_PIC : 48|4@1+ (1,0) [0|15] ""  SMART_CORE
 SG_ APA_DISP_MAIN_PIC : 42|6@1+ (1,0) [0|63] ""  SMART_CORE
 SG_ APA_DISP : 56|1@1+ (1,0) [0|1] ""  SMART_CORE
 SG_ APA_ACTIVE : 57|1@1+ (1,0) [0|1] ""  SMART_CORE
 SG_ FPAS_SW_STS : 58|1@1+ (1,0) [0|1] ""  SMART_CORE
 SG_ MAMS_SWT_STS : 59|1@1+ (1,0) [0|1] ""  SMART_CORE

BO_ 929 APA3_50: 8 Vector__XXX
 SG_ FLS_SEGMENT : 0|4@1+ (1,0) [0|15] ""  SMART_CORE
 SG_ LEFT_MIN_DIST : 40|8@1+ (2,0) [0|500] "cm"  SMART_CORE
 SG_ RRMS_SEGMENT : 24|4@1+ (1,0) [0|15] ""  SMART_CORE
 SG_ APA_SWITCH_FAULT : 59|3@1+ (1,0) [0|7] ""  SMART_CORE
 SG_ FRMS_SEGMENT : 8|4@1+ (1,0) [0|15] ""  SMART_CORE
 SG_ RIGHT_MIN_DIST : 48|8@1+ (2,0) [0|500] "cm"  SMART_CORE
 SG_ RRS_SEG_WARN : 39|1@1+ (1,0) [0|1] ""  SMART_CORE
 SG_ RRMS_SEG_WARN : 38|1@1+ (1,0) [0|1] ""  SMART_CORE
 SG_ RLMS_SEG_WARN : 37|1@1+ (1,0) [0|1] ""  SMART_CORE
 SG_ RLS_SEG_WARN : 36|1@1+ (1,0) [0|1] ""  SMART_CORE
 SG_ FRS_SEG_WARN : 35|1@1+ (1,0) [0|1] ""  SMART_CORE
 SG_ FLMS_SEG_WARN : 33|1@1+ (1,0) [0|1] ""  SMART_CORE
 SG_ RRS_SEGMENT : 28|4@1+ (1,0) [0|15] ""  SMART_CORE
 SG_ RLMS_SEGMENT : 20|4@1+ (1,0) [0|15] ""  SMART_CORE
 SG_ FLS_SEG_WARN : 32|1@1+ (1,0) [0|1] ""  SMART_CORE
 SG_ FRS_SEGMENT : 12|4@1+ (1,0) [0|15] ""  SMART_CORE
 SG_ APA_LED_FAULT : 56|3@1+ (1,0) [0|6] ""  SMART_CORE
 SG_ FRMS_SEG_WARN : 34|1@1+ (1,0) [0|1] ""  SMART_CORE
 SG_ RLS_SEGMENT : 16|4@1+ (1,0) [0|15] ""  SMART_CORE
 SG_ FLMS_SEGMENT : 4|4@1+ (1,0) [0|15] ""  SMART_CORE

BO_ 1653 GW1_1000: 8 Vector__XXX
 SG_ PRECNT_COMPLETION : 32|8@1+ (1,0) [0|100] "%"  SMART_CORE
 SG_ STS_CODE_FOTA : 0|8@1+ (1,0) [0|255] ""  SMART_CORE
 SG_ REQ_REPROG_FOTA : 25|1@1+ (1,0) [0|1] ""  SMART_CORE
 SG_ READY_UPDATE_DOWNLOAD_FOTA : 24|1@1+ (1,0) [0|1] ""  SMART_CORE
 SG_ METADATA_ID_FOTA : 8|8@1+ (1,0) [0|255] ""  SMART_CORE
 SG_ LAST_EXECUTED_STEP_FOTA : 16|8@1+ (1,0) [0|255] ""  SMART_CORE

BO_ 272 TC1_20: 8 Vector__XXX
 SG_ TC1_MSG_CNT : 0|4@1+ (1,0) [0|15] ""  SMART_CORE
 SG_ TC1_CRC : 56|8@1+ (1,0) [0|255] ""  SMART_CORE
 SG_ CUR_CARD_SHAFT_TRQ : 8|11@1+ (1,-1024) [-1024|1022] "Nm"  SMART_CORE
 SG_ TRANSFER_MODE_TC : 35|2@1+ (1,0) [0|3] ""  SMART_CORE
 SG_ INDC_TC_MALF : 39|1@1+ (1,0) [0|1] ""  SMART_CORE
 SG_ INDC_TC_ALERT : 4|3@1+ (1,0) [0|7] ""  SMART_CORE

BO_ 950 HLCU1_ACTIVE: 8 Vector__XXX
 SG_ RESERVED_2 : 0|64@1+ (1,0) [0|1.84467440737096E+019] ""  SMART_CORE

BO_ 962 ICC_SLEEP: 8 Vector__XXX
 SG_ RESERVED_2 : 0|64@1+ (1,0) [0|1.84467440737096E+019] ""  SMART_CORE

BO_ 158 ICC_WAKEUP: 8 Vector__XXX
 SG_ ICC_WAKEUP_REASON : 0|16@1+ (1,0) [0|65535] ""  SMART_CORE

BO_ 949 ICC_ACTIVE: 8 Vector__XXX
 SG_ RESERVED_2 : 0|64@1+ (1,0) [0|1.84467440737096E+019] ""  SMART_CORE

BO_ 2031 ICUA_DIAG_RES: 8 Vector__XXX
 SG_ DIAG_ICUA_RES_DATA : 0|64@1+ (1,0) [0|1.84467440737096E+019] ""  SMART_CORE

BO_ 1594 EMS43_100: 8 Vector__XXX
 SG_ FAN_SPEED : 40|8@1+ (0.5,0) [0|100] ""  SMART_CORE
 SG_ AC_PRESSURE : 0|8@1+ (16,0) [0|3100] ""  SMART_CORE
 SG_ MISFIRE_INHIBIT_STATE : 48|1@1+ (1,0) [0|1] ""  SMART_CORE
 SG_ ENG_ROUGHNESS_3 : 32|8@1+ (64,-12000) [-12000|4000] ""  SMART_CORE
 SG_ ENG_ROUGHNESS_2 : 24|8@1+ (64,-12000) [-12000|4000] ""  SMART_CORE
 SG_ ENG_ROUGHNESS_1 : 16|8@1+ (64,-12000) [-12000|4000] ""  SMART_CORE
 SG_ ENG_ROUGHNESS_0 : 8|8@1+ (64,-12000) [-12000|4000] ""  SMART_CORE
 SG_ ROUGH_ROAD_COND : 49|1@1+ (1,0) [0|1] ""  SMART_CORE

BO_ 1583 EMS41_100: 8 Vector__XXX
 SG_ SCR_STORE_NH3 : 16|8@1+ (0.05,0) [0|12] ""  SMART_CORE
 SG_ FAN_MODE : 40|8@1+ (0.5,0) [0|100] ""  SMART_CORE
 SG_ EXHAUST_MASS_FLOW : 24|8@1+ (4,-100) [-100|800] ""  SMART_CORE
 SG_ ENG_OPERATION_MODE : 57|4@1+ (1,0) [0|15] ""  SMART_CORE
 SG_ DEF_DOSING_AMT : 32|8@1+ (2,0) [0|300] ""  SMART_CORE
 SG_ NOX_DWNSTR_SCR : 48|9@1+ (2,0) [0|1000] ""  SMART_CORE
 SG_ SCR_MEAN_TEMP : 8|8@1+ (4,-100) [-100|800] ""  SMART_CORE
 SG_ SOOT_DELTA_PRESSURE : 0|8@1+ (0.25,0) [0|60] ""  SMART_CORE

BO_ 2025 TCU_DIAG_RES: 8 Vector__XXX
 SG_ DIAG_TCU_RES_DATA : 0|64@1+ (1,0) [0|1.8446744074E+019] ""  SMART_CORE

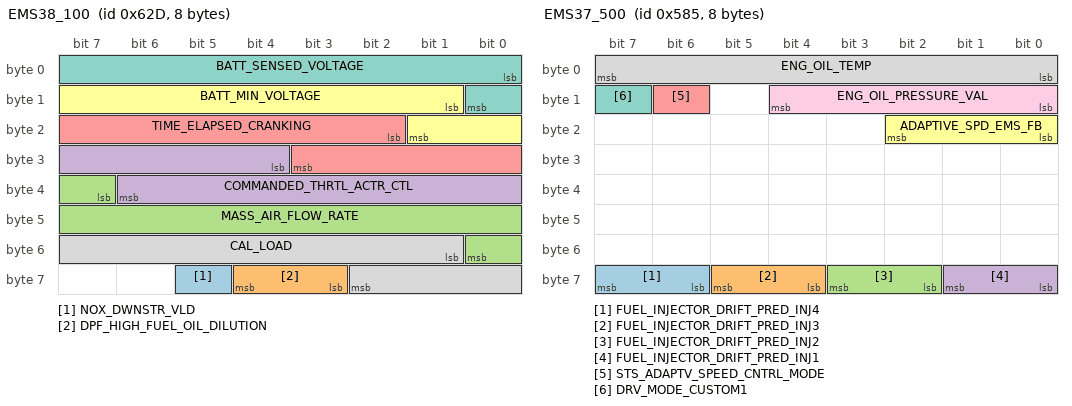
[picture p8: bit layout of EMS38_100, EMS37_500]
BO_ 1581 EMS38_100: 8 Vector__XXX
 SG_ NOX_DWNSTR_VLD : 61|1@1+ (1,0) [0|1] ""  SMART_CORE
 SG_ DPF_HIGH_FUEL_OIL_DILUTION : 59|2@1+ (1,0) [0|3] ""  SMART_CORE
 SG_ MASS_AIR_FLOW_RATE : 39|10@1+ (0.1,0) [0|100] ""  SMART_CORE
 SG_ COMMANDED_THRTL_ACTR_CTL : 28|11@1- (0.1,-50) [-50|100] ""  SMART_CORE
 SG_ TIME_ELAPSED_CRANKING : 18|10@1+ (10,0) [0|8000] "ms"  SMART_CORE
 SG_ BATT_MIN_VOLTAGE : 9|9@1+ (20,6000) [6000|16000] "mV"  SMART_CORE
 SG_ BATT_SENSED_VOLTAGE : 0|9@1+ (20,6000) [6000|16000] "mV"  SMART_CORE
 SG_ CAL_LOAD : 49|10@1+ (0.1,0) [0|100] "%"  SMART_CORE

BO_ 1413 EMS37_500: 8 Vector__XXX
 SG_ FUEL_INJECTOR_DRIFT_PRED_INJ4 : 62|2@1+ (1,0) [0|0] ""  SMART_CORE
 SG_ FUEL_INJECTOR_DRIFT_PRED_INJ3 : 60|2@1+ (1,0) [0|0] ""  SMART_CORE
 SG_ FUEL_INJECTOR_DRIFT_PRED_INJ2 : 58|2@1+ (1,0) [0|0] ""  SMART_CORE
 SG_ FUEL_INJECTOR_DRIFT_PRED_INJ1 : 56|2@1+ (1,0) [0|0] ""  SMART_CORE
 SG_ STS_ADAPTV_SPEED_CNTRL_MODE : 14|1@1+ (1,0) [0|1] ""  SMART_CORE
 SG_ ADAPTIVE_SPD_EMS_FB : 16|3@1+ (1,0) [0|7] ""  SMART_CORE
 SG_ DRV_MODE_CUSTOM1 : 15|1@1+ (1,0) [0|1] ""  SMART_CORE
 SG_ ENG_OIL_TEMP : 0|8@1+ (1,-40) [-40|214] "deg C."  SMART_CORE
 SG_ ENG_OIL_PRESSURE_VAL : 8|5@1+ (1,0) [0|30] "Bar"  SMART_CORE

BO_ 259 EMS30_SP: 8 Vector__XXX
 SG_ IMMOVAL3 : 0|64@1+ (1,0) [0|1.8446744074] ""  SMART_CORE

BO_ 1864 FATC_DIAG_RES: 8 Vector__XXX
 SG_ DIAG_FATC_RES_DATA : 0|64@1+ (1,0) [0|1.8446744074E+019] ""  SMART_CORE

BO_ 1786 IC10_1000_TEST: 8 SMART_CORE
 SG_ RAWPITCH : 16|16@1- (0.01,0) [0|0] "" Vector__XXX
 SG_ RAWROLL : 0|16@1- (0.01,0) [0|0] "" Vector__XXX

BO_ 1787 IC11_1000_TEST: 8 SMART_CORE
 SG_ PITCHCOMP : 16|16@1- (0.01,0) [0|0] "" Vector__XXX
 SG_ ROLLCOMP : 0|16@1- (0.01,0) [0|0] "" Vector__XXX

BO_ 1784 IC8_1000_TEST: 6 SMART_CORE
 SG_ ROLLDEBOUNCE : 40|8@1+ (1,0) [0|0] "" Vector__XXX
 SG_ PITCHDEBOUNCE : 32|8@1+ (1,0) [0|0] "" Vector__XXX
 SG_ ROLLRATE : 16|16@1- (1,0) [0|0] "" Vector__XXX
 SG_ ACCEL : 0|16@1- (1,0) [0|0] "" Vector__XXX

BO_ 1785 IC9_1000_TEST: 8 SMART_CORE
 SG_ PITCH : 32|16@1- (0.01,0) [0|0] "" Vector__XXX
 SG_ ROLL : 0|16@1- (0.01,0) [0|0] "" Vector__XXX

BO_ 2023 ICUA_DIAG_REQ: 8 SMART_CORE
 SG_ DIAG_ICUA_REQ_DATA : 0|64@1+ (1,0) [0|1.84467440737096E+019] "" Vector__XXX

BO_ 1844 FDHM_DIAG_REQ: 8 SMART_CORE
 SG_ DIAG_FDHM_REQ_DATA : 0|64@1+ (1,0) [0|1.8446744074E+019] "" Vector__XXX

BO_ 1957 SVS_DIAG_REQ: 8 SMART_CORE
 SG_ DIAG_SVS_REQ_DATA : 0|64@1+ (1,0) [0|1.8446744074E+019] "" Vector__XXX

BO_ 581 OBC4_30: 8 Vector__XXX
 SG_ OBC_DCOutputVoltage : 48|14@1+ (0.1,0) [0|500] "V"  SMART_CORE
 SG_ OBC_DCOutputCurrent : 32|12@1+ (0.01,0) [0|30] "A"  SMART_CORE
 SG_ OBC_ACInputVoltageRMS : 16|12@1+ (0.1,0) [0|300] "Vrms"  SMART_CORE
 SG_ OBC_ACInputCurrentRMS : 0|14@1+ (0.01,0) [0|50] "Arms"  SMART_CORE

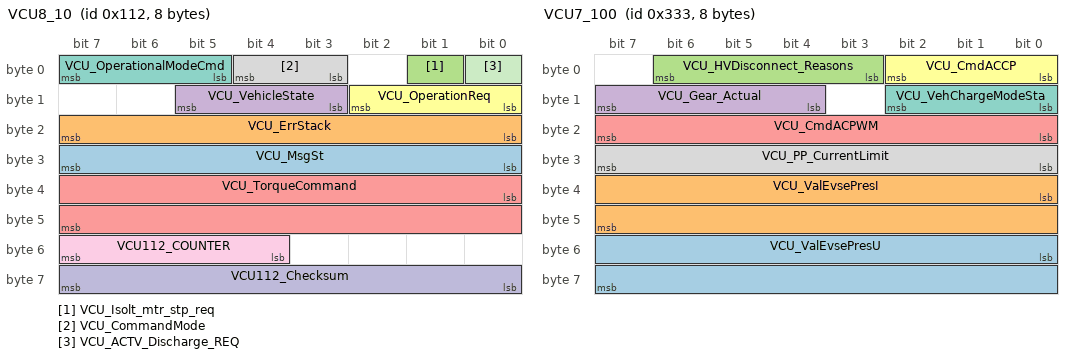
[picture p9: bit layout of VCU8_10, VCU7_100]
BO_ 274 VCU8_10: 8 Vector__XXX
 SG_ VCU_MsgSt : 24|8@1+ (1,0) [0|255] ""  SMART_CORE
 SG_ VCU_ErrStack : 16|8@1+ (1,0) [0|255] ""  SMART_CORE
 SG_ VCU_Isolt_mtr_stp_req : 1|1@1+ (1,0) [0|1] ""  SMART_CORE
 SG_ VCU_VehicleState : 11|3@1+ (1,0) [0|7] ""  SMART_CORE
 SG_ VCU_TorqueCommand : 32|16@1+ (0.0625,-2048) [-2045|2045] "Nm"  SMART_CORE
 SG_ VCU_OperationReq : 8|3@1+ (1,0) [0|7] "NA"  SMART_CORE
 SG_ VCU_OperationalModeCmd : 5|3@1+ (1,0) [0|7] "NA"  SMART_CORE
 SG_ VCU_CommandMode : 3|2@1+ (1,0) [0|3] "NA"  SMART_CORE
 SG_ VCU112_COUNTER : 52|4@1+ (1,0) [0|15] ""  SMART_CORE
 SG_ VCU112_Checksum : 56|8@1+ (1,0) [0|255] ""  SMART_CORE
 SG_ VCU_ACTV_Discharge_REQ : 0|1@1+ (1,0) [0|1] ""  SMART_CORE

BO_ 819 VCU7_100: 8 Vector__XXX
 SG_ VCU_ValEvsePresU : 48|16@1+ (0.1,0) [0|1500] "V"  SMART_CORE
 SG_ VCU_ValEvsePresI : 32|16@1+ (0.1,0) [0|1000] "A"  SMART_CORE
 SG_ VCU_HVDisconnect_Reasons : 3|4@1- (1,0) [0|16] ""  SMART_CORE
 SG_ VCU_Gear_Actual : 12|4@1+ (1,0) [0|15] ""  SMART_CORE
 SG_ VCU_CmdACPWM : 16|8@1+ (1,0) [0|100] "%"  SMART_CORE
 SG_ VCU_CmdACCP : 0|3@1+ (1,0) [0|7] "NA"  SMART_CORE
 SG_ VCU_VehChargeModeSta : 8|3@1+ (1,0) [0|7] ""  SMART_CORE
 SG_ VCU_PP_CurrentLimit : 24|8@1+ (1,0) [0|80] "A"  SMART_CORE

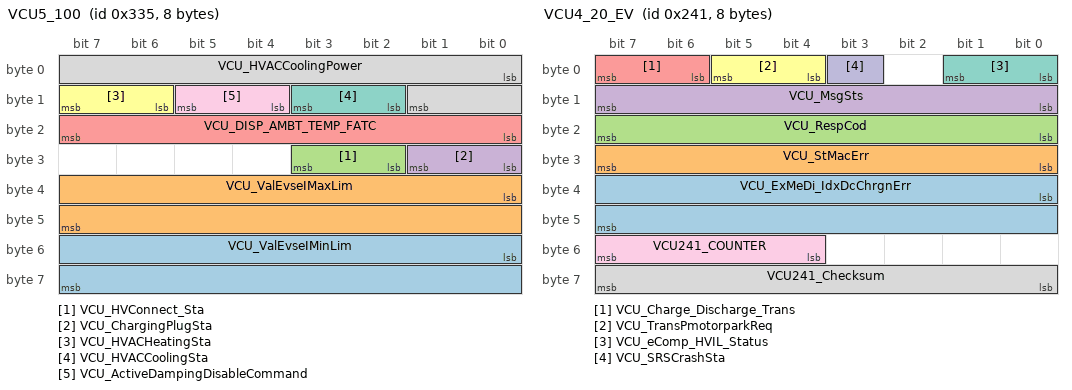
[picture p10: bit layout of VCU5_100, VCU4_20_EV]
BO_ 821 VCU5_100: 8 Vector__XXX
 SG_ VCU_ValEvseIMinLim : 48|16@1+ (0.1,0) [0|1000] "A"  SMART_CORE
 SG_ VCU_ValEvseIMaxLim : 32|16@1+ (0.1,0) [0|1000] "A"  SMART_CORE
 SG_ VCU_HVConnect_Sta : 26|2@1+ (1,0) [0|2] ""  SMART_CORE
 SG_ VCU_ChargingPlugSta : 24|2@1+ (1,0) [0|3] ""  SMART_CORE
 SG_ VCU_DISP_AMBT_TEMP_FATC : 16|8@1+ (1,-40) [-40|215] "deg C."  SMART_CORE
 SG_ VCU_HVACHeatingSta : 14|2@1+ (1,0) [0|3] ""  SMART_CORE
 SG_ VCU_HVACCoolingSta : 10|2@1+ (1,0) [0|3] ""  SMART_CORE
 SG_ VCU_HVACCoolingPower : 0|10@1+ (10,0) [0|8000] "W"  SMART_CORE
 SG_ VCU_ActiveDampingDisableCommand : 12|2@1+ (1,0) [0|3] ""  SMART_CORE

BO_ 577 VCU4_20_EV: 8 Vector__XXX
 SG_ VCU_ExMeDi_IdxDcChrgnErr : 32|16@1+ (1,0) [0|65535] ""  SMART_CORE
 SG_ VCU_StMacErr : 24|8@1+ (1,0) [0|255] ""  SMART_CORE
 SG_ VCU_RespCod : 16|8@1+ (1,0) [0|255] ""  SMART_CORE
 SG_ VCU_MsgSts : 8|8@1+ (1,0) [0|255] ""  SMART_CORE
 SG_ VCU_Charge_Discharge_Trans : 6|2@1+ (1,0) [0|3] ""  SMART_CORE
 SG_ VCU_TransPmotorparkReq : 4|2@1+ (1,0) [0|3] "NA"  SMART_CORE
 SG_ VCU_eComp_HVIL_Status : 0|2@1+ (1,0) [0|3] ""  SMART_CORE
 SG_ VCU241_Checksum : 56|8@1+ (1,0) [0|255] ""  SMART_CORE
 SG_ VCU241_COUNTER : 52|4@1+ (1,0) [0|15] ""  SMART_CORE
 SG_ VCU_SRSCrashSta : 3|1@1+ (1,0) [0|1] ""  SMART_CORE

BO_ 822 VCU3_100: 8 Vector__XXX
 SG_ VCU336_CRC : 56|8@1+ (1,0) [0|255] "NA"  SMART_CORE
 SG_ VCU336_COUNTER : 52|4@1+ (1,0) [0|15] "NA"  SMART_CORE
 SG_ VCU_AUX_BATTERY_VOLT : 16|8@1+ (0.1,0) [0|16] "NA"  SMART_CORE
 SG_ VCU_Vehicle_Speed : 32|16@1+ (0.01,0) [0|300] "kmph"  SMART_CORE
 SG_ VCU_STS_IGN : 2|3@1+ (1,0) [0|7] ""  SMART_CORE
 SG_ VCU_EPTCoolantTemp : 24|8@1+ (1,-40) [-40|215] "deg C"  SMART_CORE
 SG_ VCU_EPTCoolantFlow : 8|8@1+ (0.5,0) [0|100] "%"  SMART_CORE
 SG_ VCU_EVReady : 0|2@1+ (1,0) [0|3] "NA"  SMART_CORE

BO_ 437 VCU18_10: 8 Vector__XXX
 SG_ VCU_BMS_ASW_SleepRequest : 28|4@1+ (1,0) [0|7] "NA"  SMART_CORE
 SG_ VCU_SmObc_State : 48|16@1+ (1,0) [0|65535] ""  SMART_CORE
 SG_ VCU_Wakeup_Reason_internal : 24|4@1+ (1,0) [0|15] ""  SMART_CORE
 SG_ VCU_NoSM_State : 32|16@1+ (1,0) [0|65535] ""  SMART_CORE
 SG_ VCU_EVCSI_State : 16|8@1+ (1,0) [0|255] ""  SMART_CORE
 SG_ VCU_CharPD_RawVal : 8|8@1+ (0.1,0) [0|20] "V"  SMART_CORE
 SG_ VCU_CharCP_RawVal : 0|8@1+ (0.1,0) [0|20] "V"  SMART_CORE

BO_ 601 VCU14_20: 8 Vector__XXX
 SG_ VCU_StsIslnEvse : 56|8@1+ (1,0) [0|255] ""  SMART_CORE
 SG_ VCU_ValEvseUMinLim : 0|16@1+ (0.1,0) [0|1500] "V"  SMART_CORE
 SG_ VCU_LV_Battery_Voltage : 48|8@1+ (0.1,0) [0|25] "V"  SMART_CORE
 SG_ VCU_brake2_voltage : 40|8@1+ (0.1,0) [0|25] "V"  SMART_CORE
 SG_ VCU_brake1_voltage : 32|8@1+ (0.1,0) [0|25] "V"  SMART_CORE
 SG_ VCU_Accep2_voltage : 24|8@1+ (0.1,0) [0|25] "V"  SMART_CORE
 SG_ VCU_Accep1_voltage : 16|8@1+ (0.1,0) [0|25] "V"  SMART_CORE

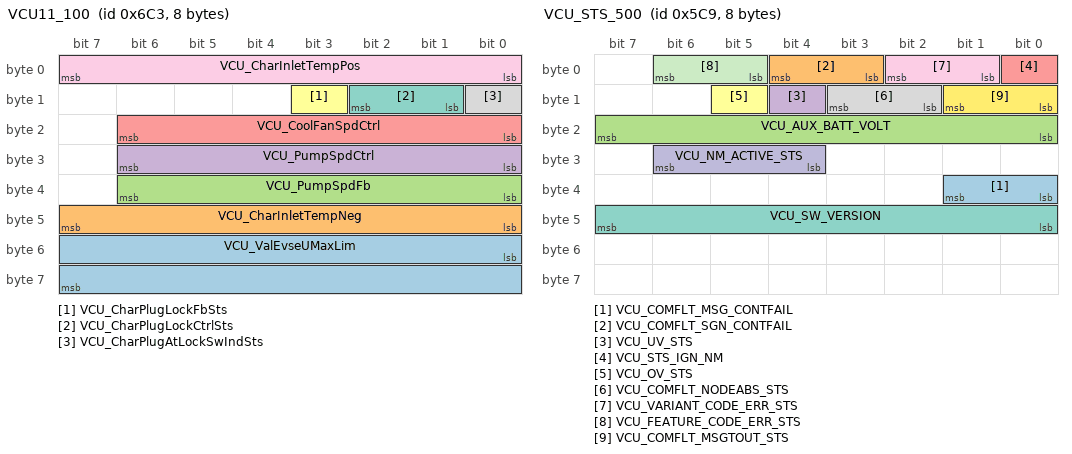
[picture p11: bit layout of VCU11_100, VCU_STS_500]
BO_ 1731 VCU11_100: 8 Vector__XXX
 SG_ VCU_ValEvseUMaxLim : 48|16@1+ (0.1,0) [0|1500] "V"  SMART_CORE
 SG_ VCU_CharInletTempNeg : 40|8@1+ (1,-40) [-40|215] "deg"  SMART_CORE
 SG_ VCU_PumpSpdFb : 32|7@1+ (1,0) [0|100] "%"  SMART_CORE
 SG_ VCU_PumpSpdCtrl : 24|7@1+ (1,0) [0|100] "%"  SMART_CORE
 SG_ VCU_CoolFanSpdCtrl : 16|7@1+ (1,0) [0|100] "%"  SMART_CORE
 SG_ VCU_CharPlugLockFbSts : 11|1@1+ (1,0) [0|1] ""  SMART_CORE
 SG_ VCU_CharPlugLockCtrlSts : 9|2@1+ (1,0) [0|2] ""  SMART_CORE
 SG_ VCU_CharPlugAtLockSwIndSts : 8|1@1+ (1,0) [0|1] ""  SMART_CORE
 SG_ VCU_CharInletTempPos : 0|8@1+ (1,-40) [-40|215] "deg"  SMART_CORE

BO_ 1481 VCU_STS_500: 8 Vector__XXX
 SG_ VCU_COMFLT_MSG_CONTFAIL : 32|2@1+ (1,0) [0|3] ""  SMART_CORE
 SG_ VCU_COMFLT_SGN_CONTFAIL : 3|2@1+ (1,0) [0|3] ""  SMART_CORE
 SG_ VCU_AUX_BATT_VOLT : 16|8@1+ (0.1,0) [0|16] ""  SMART_CORE
 SG_ VCU_UV_STS : 12|1@1+ (1,0) [0|1] ""  SMART_CORE
 SG_ VCU_STS_IGN_NM : 0|1@1+ (1,0) [0|1] ""  SMART_CORE
 SG_ VCU_OV_STS : 13|1@1+ (1,0) [0|1] ""  SMART_CORE
 SG_ VCU_SW_VERSION : 40|8@1+ (1,0) [0|255] ""  SMART_CORE
 SG_ VCU_COMFLT_NODEABS_STS : 10|2@1+ (1,0) [0|3] ""  SMART_CORE
 SG_ VCU_VARIANT_CODE_ERR_STS : 1|2@1+ (1,0) [0|3] ""  SMART_CORE
 SG_ VCU_NM_ACTIVE_STS : 28|3@1+ (1,0) [0|7] ""  SMART_CORE
 SG_ VCU_FEATURE_CODE_ERR_STS : 5|2@1+ (1,0) [0|3] ""  SMART_CORE
 SG_ VCU_COMFLT_MSGTOUT_STS : 8|2@1+ (1,0) [0|3] ""  SMART_CORE

BO_ 988 OBC6_100: 8 Vector__XXX
 SG_ OBC_VIN_MISMATCH_FAULT : 63|1@1+ (1,0) [0|1] ""  SMART_CORE
 SG_ OBC_ECU_RESET_FAULT : 62|1@1+ (1,0) [0|1] ""  SMART_CORE
 SG_ OBC_Low_Temp_Shutdown : 47|1@1+ (1,0) [0|1] ""  SMART_CORE
 SG_ OBC_HVDC_HW_OV : 35|1@1+ (1,0) [0|1] ""  SMART_CORE
 SG_ OBC_CPVol_Out_of_Range : 46|1@1+ (1,0) [0|1] ""  SMART_CORE
 SG_ OBC_CPDuty_Out_of_Range : 37|1@1+ (1,0) [0|1] ""  SMART_CORE
 SG_ OBC_HVDC_HW_OC : 36|1@1+ (1,0) [0|1] ""  SMART_CORE
 SG_ OBC_PRECHARGE_FAULT_CNT : 59|3@1+ (1,0) [0|7] ""  SMART_CORE
 SG_ OBC_PFC_BUS_FAULT_CNT : 56|3@1+ (1,0) [0|7] ""  SMART_CORE
 SG_ OBC_PFC_VOLT_CNTRL_IP : 48|8@1+ (1,-30) [-30|30] ""  SMART_CORE
 SG_ OBC_LIne_OC_SW : 16|1@1+ (1,0) [0|1] ""  SMART_CORE
 SG_ OBC_LLC_CONTROL_INPUT : 40|6@1+ (1,20) [-20|20] ""  SMART_CORE
 SG_ OBC_PLL_TIMELOCK_STS : 34|1@1+ (1,0) [0|1] ""  SMART_CORE
 SG_ OBC_CC_CV_STS : 33|1@1+ (1,0) [0|1] ""  SMART_CORE
 SG_ OBC_BURST_MODE_STS : 32|1@1+ (1,0) [0|1] ""  SMART_CORE
 SG_ OBC_STATE : 28|4@1+ (1,0) [0|1] ""  SMART_CORE
 SG_ OBC_LLC_OC_HW_FLAG : 18|1@1+ (1,0) [0|1] ""  SMART_CORE
 SG_ OBC_PFC_OC_HW_Flag : 17|1@1+ (1,0) [0|1] ""  SMART_CORE
 SG_ OBC_Inductr_current_L2_OC : 39|1@1+ (1,0) [0|1] ""  SMART_CORE
 SG_ OBC_Inductr_current_L1_OC : 38|1@1+ (1,0) [0|1] ""  SMART_CORE
 SG_ OBC_VPROG_OUT_OF_RANGE : 27|1@1+ (1,0) [0|1] ""  SMART_CORE
 SG_ OBC_TEMP_SENSOR_FAIL : 26|1@1+ (1,0) [0|1] ""  SMART_CORE
 SG_ OBC_OVER_TEMP : 25|1@1+ (1,0) [0|1] ""  SMART_CORE
 SG_ OBC_INTERNAL_FAIL : 24|1@1+ (1,0) [0|1] ""  SMART_CORE
 SG_ OBC_HIGH_TEMP : 23|1@1+ (1,0) [0|1] ""  SMART_CORE
 SG_ OBC_IPROG_OUT_OF_RANGE : 22|1@1+ (1,0) [0|1] ""  SMART_CORE
 SG_ OBC_EMI_IP_UV : 21|1@1+ (1,0) [0|1] ""  SMART_CORE
 SG_ OBC_EMI_IP_OV : 20|1@1+ (1,0) [0|1] ""  SMART_CORE
 SG_ OBC_EEPROM_FAIL : 19|1@1+ (1,0) [0|1] ""  SMART_CORE
 SG_ OBC_CAN_BUS_OFF : 15|1@1+ (1,0) [0|1] ""  SMART_CORE
 SG_ OBC_TEMP_DERATE : 14|1@1+ (1,0) [0|1] ""  SMART_CORE
 SG_ OBC_PRE_CHARGE_FAULT : 13|1@1+ (1,0) [0|1] ""  SMART_CORE
 SG_ OBC_PFV_OV : 12|1@1+ (1,0) [0|1] ""  SMART_CORE
 SG_ OBC_PFC_UV : 11|1@1+ (1,0) [0|1] ""  SMART_CORE
 SG_ OBC_PFC_OVER_TEMP : 10|1@1+ (1,0) [0|1] ""  SMART_CORE
 SG_ OBC_OP_UV : 9|1@1+ (1,0) [0|1] ""  SMART_CORE
 SG_ OBC_OP_OV : 8|1@1+ (1,0) [0|1] ""  SMART_CORE
 SG_ OBC_OP_OC : 7|1@1+ (1,0) [0|1] ""  SMART_CORE
 SG_ OBC_LV_UNDER_VOLT : 6|1@1+ (1,0) [0|1] ""  SMART_CORE
 SG_ OBC_LV_OVER_VOLT : 5|1@1+ (1,0) [0|1] ""  SMART_CORE
 SG_ OBC_LLC_OVER_TEMP : 4|1@1+ (1,0) [0|1] ""  SMART_CORE
 SG_ OBC_IP_UNDER_VOLT : 3|1@1+ (1,0) [0|1] ""  SMART_CORE
 SG_ OBC_IP_OVER_VOLT : 2|1@1+ (1,0) [0|1] ""  SMART_CORE
 SG_ OBC_IP_OVER_CURR : 1|1@1+ (1,0) [0|1] ""  SMART_CORE
 SG_ OBC_IP_DERATE : 0|1@1+ (1,0) [0|1] ""  SMART_CORE

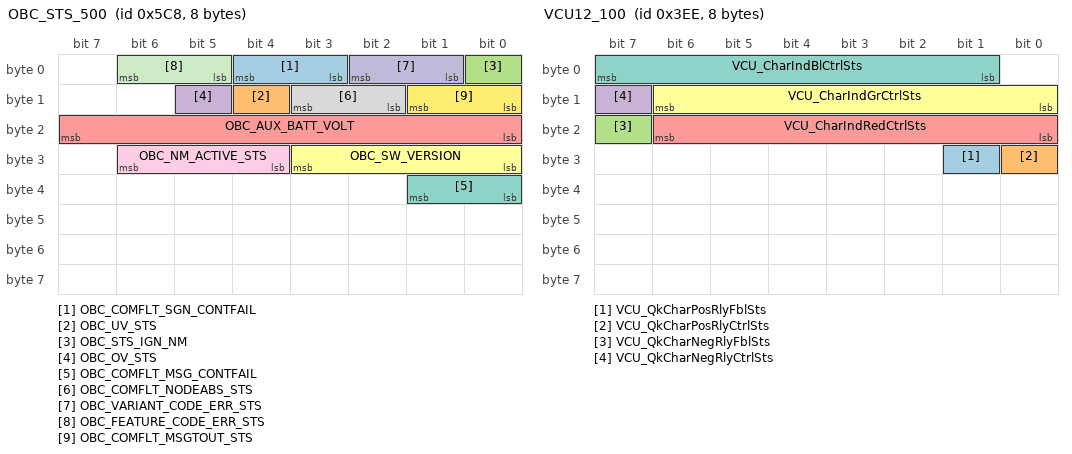
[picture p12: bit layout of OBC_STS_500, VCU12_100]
BO_ 1480 OBC_STS_500: 8 Vector__XXX
 SG_ OBC_COMFLT_SGN_CONTFAIL : 3|2@1+ (1,0) [0|3] ""  SMART_CORE
 SG_ OBC_UV_STS : 12|1@1+ (1,0) [0|1] ""  SMART_CORE
 SG_ OBC_STS_IGN_NM : 0|1@1+ (1,0) [0|1] ""  SMART_CORE
 SG_ OBC_OV_STS : 13|1@1+ (1,0) [0|1] ""  SMART_CORE
 SG_ OBC_AUX_BATT_VOLT : 16|8@1+ (0.1,0) [0|16] ""  SMART_CORE
 SG_ OBC_SW_VERSION : 24|4@1+ (1,0) [0|15] ""  SMART_CORE
 SG_ OBC_COMFLT_MSG_CONTFAIL : 32|2@1+ (1,0) [0|3] ""  SMART_CORE
 SG_ OBC_COMFLT_NODEABS_STS : 10|2@1+ (1,0) [0|3] ""  SMART_CORE
 SG_ OBC_NM_ACTIVE_STS : 28|3@1+ (1,0) [0|7] ""  SMART_CORE
 SG_ OBC_VARIANT_CODE_ERR_STS : 1|2@1+ (1,0) [0|3] ""  SMART_CORE
 SG_ OBC_FEATURE_CODE_ERR_STS : 5|2@1+ (1,0) [0|3] ""  SMART_CORE
 SG_ OBC_COMFLT_MSGTOUT_STS : 8|2@1+ (1,0) [0|3] ""  SMART_CORE

BO_ 983 MCU5_100: 8 Vector__XXX
 SG_ MCU_TPI : 8|8@1+ (0.01,0) [0|2] ""  SMART_CORE
 SG_ MCU_MotorCoolingFlowReq : 32|8@1+ (0.5,0) [0|100] "%"  SMART_CORE
 SG_ MCU_Motor_Temp_Indicator : 24|8@1+ (1,-50) [-50|200] "deg C"  SMART_CORE
 SG_ MCU_Inverter_Temp_Indicator : 16|8@1+ (1,-50) [-50|200] "deg C"  SMART_CORE
 SG_ MCU_Inverter_CoolingFlowReq : 0|8@1+ (0.5,0) [0|100] "%"  SMART_CORE

BO_ 280 MCU2_10: 8 Vector__XXX
 SG_ MCU118_COUNTER : 52|4@1+ (1,0) [0|15] ""  SMART_CORE
 SG_ MCU118_Checksum : 56|8@1+ (1,0) [0|255] ""  SMART_CORE
 SG_ MCU_MotorSpeed : 16|16@1+ (1,-32767) [-32760|32760] "RPM"  SMART_CORE
 SG_ MCU_MotorTorqueEstimated : 0|16@1+ (0.0625,-2048) [-2045|2045] "Nm"  SMART_CORE

BO_ 1016 BMS_CLT_HTR3_200: 8 Vector__XXX
 SG_ BMS_HTR_CLT_SoftwareVersion_Num : 56|8@1+ (1,0) [0|255] ""  SMART_CORE
 SG_ BMS_HTR_CLT_Fault_PCBTempSen : 28|1@1+ (1,0) [0|1] ""  SMART_CORE
 SG_ BMS_HTR_CLT_Fault_PCBTempOver : 14|1@1+ (1,0) [0|1] ""  SMART_CORE
 SG_ BMS_HTR_CLT_Fault_OutletTempSen : 27|1@1+ (1,0) [0|1] ""  SMART_CORE
 SG_ BMS_HTR_CLT_Fault_OutletTempOver : 13|1@1+ (1,0) [0|1] ""  SMART_CORE
 SG_ BMS_HTR_CLT_Fault_LVSen : 24|1@1+ (1,0) [0|1] ""  SMART_CORE
 SG_ BMS_HTR_CLT_Fault_LostCtrlMsg : 15|1@1+ (1,0) [0|1] ""  SMART_CORE
 SG_ BMS_HTR_CLT_Fault_IGBTShort : 30|1@1+ (1,0) [0|1] ""  SMART_CORE
 SG_ BMS_HTR_CLT_Fault_IGBTOpen : 29|1@1+ (1,0) [0|1] ""  SMART_CORE
 SG_ BMS_HTR_CLT_Fault_IGBTDriverIC : 31|1@1+ (1,0) [0|1] ""  SMART_CORE
 SG_ BMS_HTR_CLT_Fault_HVSen : 25|1@1+ (1,0) [0|1] ""  SMART_CORE
 SG_ BMS_HTR_CLT_Fault_HVOver : 11|1@1+ (1,0) [0|1] ""  SMART_CORE
 SG_ BMS_HTR_CLT_Fault_HVCurSen : 26|1@1+ (1,0) [0|1] ""  SMART_CORE
 SG_ BMS_HTR_CLT_LIN_Com_Err_Flag : 1|1@1+ (1,0) [0|1] ""  SMART_CORE
 SG_ BMS_HTR_CLT_Fault_LVUnder : 8|1@1+ (1,0) [0|1] ""  SMART_CORE
 SG_ BMS_HTR_CLT_Fault_LVOver : 9|1@1+ (1,0) [0|1] ""  SMART_CORE
 SG_ BMS_HTR_CLT_Fault_HVUnder : 10|1@1+ (1,0) [0|1] ""  SMART_CORE
 SG_ BMS_HTR_CLT_Fault_HVOverCur : 12|1@1+ (1,0) [0|1] ""  SMART_CORE
 SG_ BMS_HTR_CLT_Fault_Flag : 0|1@1+ (1,0) [0|1] ""  SMART_CORE

BO_ 1918 MGM_FOTA_DIAG_RES: 8 Vector__XXX
 SG_ DIAG_MGM_FOTA_RES_DATA : 0|64@1+ (1,0) [0|1.8446744074E+019] ""  SMART_CORE

BO_ 1910 MGM_FOTA_DIAG_REQ: 8 SMART_CORE
 SG_ DIAG_MGM_FOTA_REQ_DATA : 0|64@1+ (1,0) [0|1.8446744074E+019] "" Vector__XXX

BO_ 1015 BMS_CLT_HTR2_200: 8 Vector__XXX
 SG_ BMS_HTR_CLT_Status_Flag : 1|2@1+ (1,1) [0|2] ""  SMART_CORE
 SG_ BMS_HTR_CLT_Ready_Flag : 0|1@1+ (1,0) [0|1] ""  SMART_CORE
 SG_ BMS_HTR_CLT_OutletTemp_DegC : 32|8@1+ (1,0) [0|255] ""  SMART_CORE
 SG_ BMS_HTR_CLT_HVInput_V : 8|8@1+ (1,0) [0|255] ""  SMART_CORE
 SG_ BMS_HTR_CLT_CnsPwr_W : 24|8@1+ (1,0) [0|255] ""  SMART_CORE
 SG_ BMS_HTR_CLT_CnsDuty_Per : 40|8@1+ (1,0) [0|255] ""  SMART_CORE
 SG_ BMS_HTR_CLT_CnsCur_A : 16|8@1+ (1,0) [0|255] ""  SMART_CORE

BO_ 1014 BMS_CLT_HTR1_200: 8 Vector__XXX
 SG_ BMS_HTR_CltTemp_DegC : 16|8@1+ (1,0) [0|255] ""  SMART_CORE
 SG_ BMS_HTR_CltPerf_Perc : 8|8@1- (1,0) [0|255] ""  SMART_CORE
 SG_ BMS_HTR_CltAllowance_Flag : 0|1@1+ (1,0) [0|1] ""  SMART_CORE

BO_ 993 VCU_ACTIVE_EV: 8 Vector__XXX
 SG_ VCU_ACTIVE_RESERVED_EV : 0|64@1+ (1,0) [0|0] "NA"  SMART_CORE

BO_ 824 VCU2_100: 8 Vector__XXX
 SG_ VCU338_COUNTER : 52|4@1+ (1,0) [0|15] "NA"  SMART_CORE
 SG_ VCU_CmdACChargeTargetVolt : 16|14@1+ (0.1,0) [0|500] "V"  SMART_CORE
 SG_ VCU338_CRC : 56|8@1+ (1,0) [0|255] "NA"  SMART_CORE
 SG_ VCU_CmdEnableOBC : 40|2@1+ (1,0) [0|3] "NA"  SMART_CORE
 SG_ VCU_CmdACChargeTargetCurrent : 0|12@1+ (0.01,0) [0|35] "A"  SMART_CORE
 SG_ VCU_ACChargingReady : 32|2@1+ (1,0) [0|3] ""  SMART_CORE

BO_ 1736 VCU16_1000: 8 Vector__XXX
 SG_ VCU_EConsDistSample4 : 48|16@1+ (0.001,0) [0|65.535] "Kwh"  SMART_CORE
 SG_ VCU_EConsDistSample3 : 32|16@1+ (0.001,0) [0|65.535] "Kwh"  SMART_CORE
 SG_ VCU_EConsDistSample2 : 16|16@1+ (0.001,0) [0|65.535] "Kwh"  SMART_CORE
 SG_ VCU_EConsDistSample1 : 0|16@1+ (0.001,0) [0|65.535] "Kwh"  SMART_CORE

BO_ 1012 VCU13_100: 8 Vector__XXX
 SG_ VCU_DcChargingSequence : 36|4@1+ (1,0) [0|15] ""  SMART_CORE
 SG_ VCU_SBWS_BuFb_RawVal : 24|7@1+ (1,0) [0|100] "%"  SMART_CORE
 SG_ VCU_SBWS_Bu_RawVal : 17|7@1+ (1,0) [0|100] "%"  SMART_CORE
 SG_ VCU_PumpRlyCtrlSts : 16|1@1+ (1,0) [0|1] ""  SMART_CORE
 SG_ VCU_MAX_CPU_Load : 0|8@1+ (1,0) [0|200] ""  SMART_CORE
 SG_ VCU_AVG_CPU_Load : 8|8@1+ (1,0) [0|200] ""  SMART_CORE

BO_ 1006 VCU12_100: 8 Vector__XXX
 SG_ VCU_QkCharPosRlyFblSts : 25|1@1+ (1,0) [0|1] ""  SMART_CORE
 SG_ VCU_QkCharPosRlyCtrlSts : 24|1@1+ (1,0) [0|1] ""  SMART_CORE
 SG_ VCU_QkCharNegRlyFblSts : 23|1@1+ (1,0) [0|1] ""  SMART_CORE
 SG_ VCU_QkCharNegRlyCtrlSts : 15|1@1+ (1,0) [0|1] ""  SMART_CORE
 SG_ VCU_CharIndRedCtrlSts : 16|7@1+ (1,0) [0|100] "%"  SMART_CORE
 SG_ VCU_CharIndGrCtrlSts : 8|7@1+ (1,0) [0|100] "%"  SMART_CORE
 SG_ VCU_CharIndBlCtrlSts : 1|7@1+ (1,0) [0|100] "%"  SMART_CORE

BO_ 984 OBC3_100: 8 Vector__XXX
 SG_ OBC_Line_Frequency : 48|10@1+ (1,0) [40|65] ""  SMART_CORE
 SG_ OBC_PFC_Voltage : 32|14@1+ (0.1,0) [0|500] ""  SMART_CORE
 SG_ OBC_DCVoltageCapable : 16|14@1+ (0.1,0) [0|500] "V"  SMART_CORE
 SG_ OBC_DCCurrentCapable : 0|12@1+ (0.01,0) [0|30] "A"  SMART_CORE

BO_ 1064 OBC2_100: 8 Vector__XXX
 SG_ OBC_Inductor_current_L2_RMS : 40|14@1+ (0.01,0) [0|20] ""  SMART_CORE
 SG_ OBC_Inductor_current_L1_RMS : 16|14@1+ (0.01,0) [0|20] ""  SMART_CORE
 SG_ OBC_PowerDeratingSta : 32|3@1+ (1,0) [0|7] "NA"  SMART_CORE
 SG_ OBC_OperatingMode : 8|3@1+ (1,0) [0|7] "NA"  SMART_CORE
 SG_ OBC_ACDetectSta : 0|1@1+ (1,0) [0|1] "NA"  SMART_CORE

BO_ 986 OBC1_100: 8 Vector__XXX
 SG_ OBC_SecondarySide_Temperature : 52|12@1+ (0.1,-55) [-55|150] ""  SMART_CORE
 SG_ OBC_Transformer_Temperature : 32|12@1+ (0.1,-55) [-55|150] "deg C"  SMART_CORE
 SG_ OBC_CoolingRequest : 44|8@1+ (0.5,0) [0|100] "%"  SMART_CORE
 SG_ OBC_PrimarySide_Temperature : 16|12@1+ (0.1,-55) [-55|150] "deg C"  SMART_CORE
 SG_ OBC_LV_PwrSupply : 0|12@1+ (0.01,0) [0|25] ""  SMART_CORE

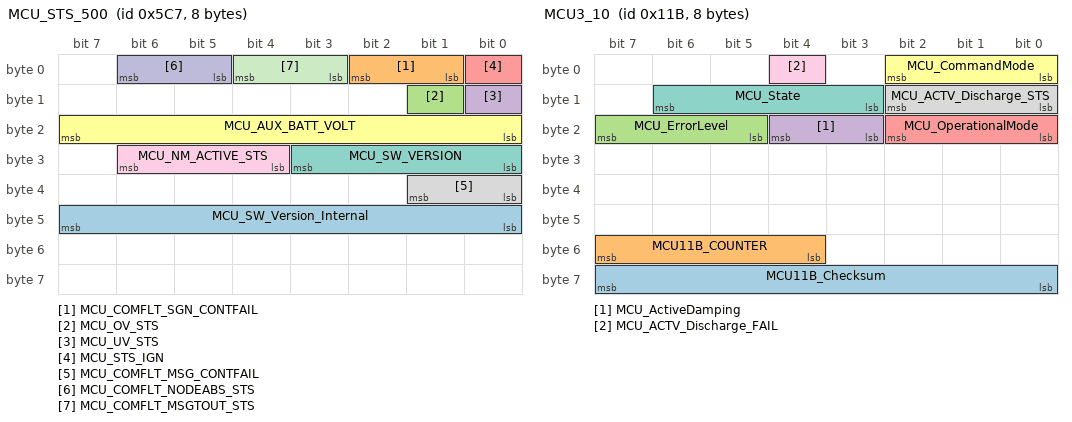
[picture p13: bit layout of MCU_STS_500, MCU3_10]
BO_ 1479 MCU_STS_500: 8 Vector__XXX
 SG_ MCU_SW_Version_Internal : 40|8@1+ (1,0) [0|255] ""  SMART_CORE
 SG_ MCU_COMFLT_SGN_CONTFAIL : 1|2@1+ (1,0) [0|3] ""  SMART_CORE
 SG_ MCU_OV_STS : 9|1@1+ (1,0) [0|1] ""  SMART_CORE
 SG_ MCU_UV_STS : 8|1@1+ (1,0) [0|1] ""  SMART_CORE
 SG_ MCU_STS_IGN : 0|1@1+ (1,0) [0|1] ""  SMART_CORE
 SG_ MCU_AUX_BATT_VOLT : 16|8@1+ (0.1,0) [0|16] ""  SMART_CORE
 SG_ MCU_SW_VERSION : 24|4@1+ (1,0) [0|15] ""  SMART_CORE
 SG_ MCU_COMFLT_MSG_CONTFAIL : 32|2@1+ (1,0) [0|3] ""  SMART_CORE
 SG_ MCU_NM_ACTIVE_STS : 28|3@1+ (1,0) [0|7] ""  SMART_CORE
 SG_ MCU_COMFLT_NODEABS_STS : 5|2@1+ (1,0) [0|3] ""  SMART_CORE
 SG_ MCU_COMFLT_MSGTOUT_STS : 3|2@1+ (1,0) [0|3] ""  SMART_CORE

BO_ 283 MCU3_10: 8 Vector__XXX
 SG_ MCU11B_Checksum : 56|8@1+ (1,0) [0|255] ""  SMART_CORE
 SG_ MCU11B_COUNTER : 52|4@1+ (1,0) [0|15] ""  SMART_CORE
 SG_ MCU_ErrorLevel : 21|3@1+ (1,0) [0|7] "NA"  SMART_CORE
 SG_ MCU_ActiveDamping : 19|2@1+ (1,0) [0|3] "NA"  SMART_CORE
 SG_ MCU_OperationalMode : 16|3@1+ (1,0) [0|7] "NA"  SMART_CORE
 SG_ MCU_CommandMode : 0|3@1+ (1,0) [0|7] "NA"  SMART_CORE
 SG_ MCU_State : 11|4@1+ (1,0) [0|15] ""  SMART_CORE
 SG_ MCU_ACTV_Discharge_STS : 8|3@1+ (1,0) [0|3] ""  SMART_CORE
 SG_ MCU_ACTV_Discharge_FAIL : 4|1@1+ (1,0) [0|1] ""  SMART_CORE

BO_ 982 MCU1_100: 8 Vector__XXX
 SG_ MCU_HighPowerCurrent : 48|14@1+ (0.25,-2046) [-2046|2048] "A"  SMART_CORE
 SG_ MCU_HighPowerVoltage : 32|11@1+ (1,0) [0|2046] "V"  SMART_CORE
 SG_ MCU_TractionTorqueAvail_quasi : 16|15@1+ (0.0625,0) [0|2045] "Nm"  SMART_CORE
 SG_ MCU_RegenTorqueAvail_quasi : 0|15@1+ (0.0625,0) [0|2045] "Nm"  SMART_CORE

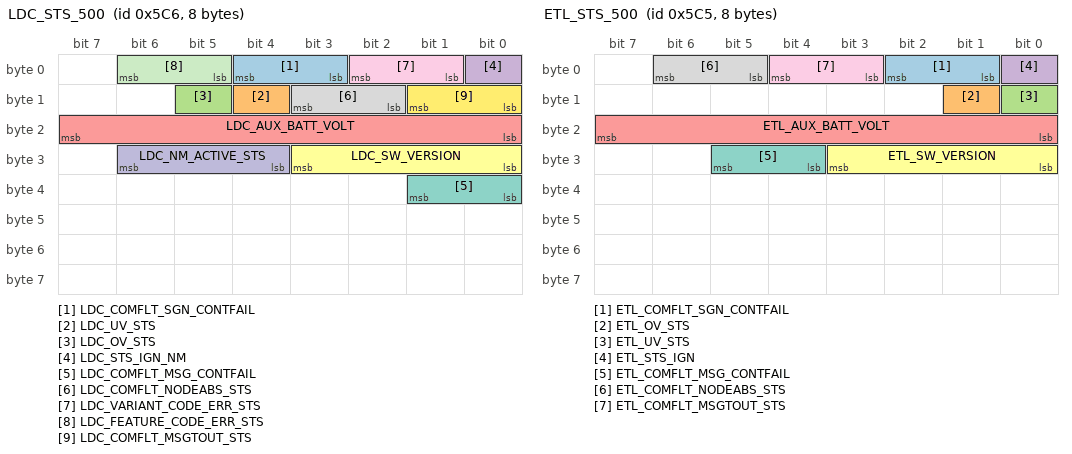
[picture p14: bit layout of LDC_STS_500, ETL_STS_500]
BO_ 1478 LDC_STS_500: 8 Vector__XXX
 SG_ LDC_COMFLT_SGN_CONTFAIL : 3|2@1+ (1,0) [0|3] ""  SMART_CORE
 SG_ LDC_UV_STS : 12|1@1+ (1,0) [0|1] ""  SMART_CORE
 SG_ LDC_OV_STS : 13|1@1+ (1,0) [0|1] ""  SMART_CORE
 SG_ LDC_STS_IGN_NM : 0|1@1+ (1,0) [0|1] ""  SMART_CORE
 SG_ LDC_AUX_BATT_VOLT : 16|8@1+ (0.1,0) [0|16] ""  SMART_CORE
 SG_ LDC_SW_VERSION : 24|4@1+ (1,0) [0|15] ""  SMART_CORE
 SG_ LDC_COMFLT_MSG_CONTFAIL : 32|2@1+ (1,0) [0|3] ""  SMART_CORE
 SG_ LDC_COMFLT_NODEABS_STS : 10|2@1+ (1,0) [0|3] ""  SMART_CORE
 SG_ LDC_VARIANT_CODE_ERR_STS : 1|2@1+ (1,0) [0|3] ""  SMART_CORE
 SG_ LDC_NM_ACTIVE_STS : 28|3@1+ (1,0) [0|7] ""  SMART_CORE
 SG_ LDC_FEATURE_CODE_ERR_STS : 5|2@1+ (1,0) [0|3] ""  SMART_CORE
 SG_ LDC_COMFLT_MSGTOUT_STS : 8|2@1+ (1,0) [0|3] ""  SMART_CORE

BO_ 1477 ETL_STS_500: 8 Vector__XXX
 SG_ ETL_COMFLT_SGN_CONTFAIL : 1|2@1+ (1,0) [0|3] ""  SMART_CORE
 SG_ ETL_OV_STS : 9|1@1+ (1,0) [0|1] ""  SMART_CORE
 SG_ ETL_UV_STS : 8|1@1+ (1,0) [0|1] ""  SMART_CORE
 SG_ ETL_STS_IGN : 0|1@1+ (1,0) [0|1] ""  SMART_CORE
 SG_ ETL_AUX_BATT_VOLT : 16|8@1+ (0.1,0) [0|16] ""  SMART_CORE
 SG_ ETL_SW_VERSION : 24|4@1+ (1,0) [0|15] ""  SMART_CORE
 SG_ ETL_COMFLT_MSG_CONTFAIL : 28|2@1+ (1,0) [0|3] ""  SMART_CORE
 SG_ ETL_COMFLT_NODEABS_STS : 5|2@1+ (1,0) [0|3] ""  SMART_CORE
 SG_ ETL_COMFLT_MSGTOUT_STS : 3|2@1+ (1,0) [0|3] ""  SMART_CORE

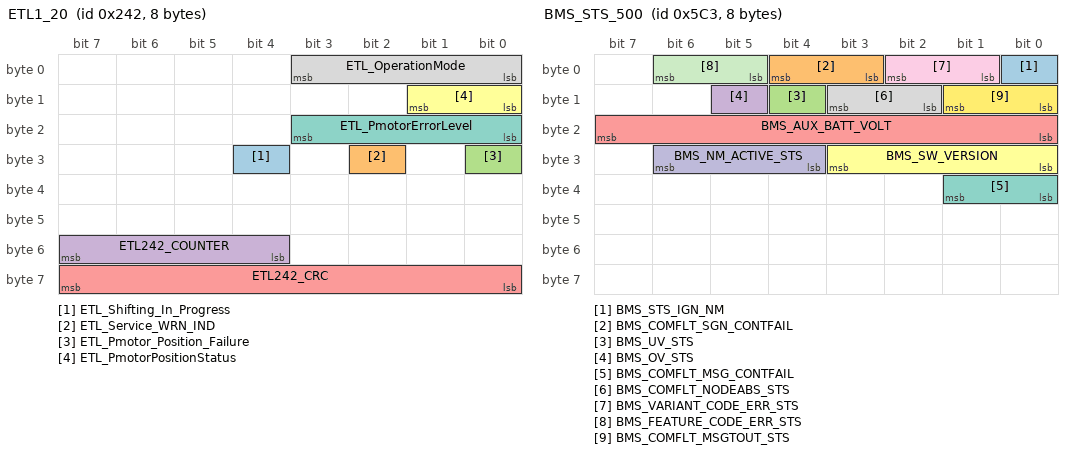
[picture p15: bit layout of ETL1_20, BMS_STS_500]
BO_ 578 ETL1_20: 8 Vector__XXX
 SG_ ETL_Shifting_In_Progress : 28|1@1+ (1,0) [0|1] ""  SMART_CORE
 SG_ ETL_Service_WRN_IND : 26|1@1+ (1,0) [0|1] ""  SMART_CORE
 SG_ ETL_Pmotor_Position_Failure : 24|1@1+ (1,0) [0|1] ""  SMART_CORE
 SG_ ETL242_COUNTER : 52|4@1+ (1,0) [0|14] "NA"  SMART_CORE
 SG_ ETL242_CRC : 56|8@1+ (1,0) [0|255] "NA"  SMART_CORE
 SG_ ETL_PmotorPositionStatus : 8|2@1+ (1,0) [0|3] "NA"  SMART_CORE
 SG_ ETL_PmotorErrorLevel : 16|4@1+ (1,0) [0|15] "NA"  SMART_CORE
 SG_ ETL_OperationMode : 0|4@1+ (1,0) [0|15] "NA"  SMART_CORE

BO_ 1475 BMS_STS_500: 8 Vector__XXX
 SG_ BMS_STS_IGN_NM : 0|1@1+ (1,0) [0|1] ""  SMART_CORE
 SG_ BMS_COMFLT_SGN_CONTFAIL : 3|2@1+ (1,0) [0|3] ""  SMART_CORE
 SG_ BMS_UV_STS : 12|1@1+ (1,0) [0|1] ""  SMART_CORE
 SG_ BMS_OV_STS : 13|1@1+ (1,0) [0|1] ""  SMART_CORE
 SG_ BMS_AUX_BATT_VOLT : 16|8@1+ (0.1,0) [0|16] ""  SMART_CORE
 SG_ BMS_SW_VERSION : 24|4@1+ (1,0) [0|15] ""  SMART_CORE
 SG_ BMS_COMFLT_MSG_CONTFAIL : 32|2@1+ (1,0) [0|3] ""  SMART_CORE
 SG_ BMS_COMFLT_NODEABS_STS : 10|2@1+ (1,0) [0|3] ""  SMART_CORE
 SG_ BMS_VARIANT_CODE_ERR_STS : 1|2@1+ (1,0) [0|3] ""  SMART_CORE
 SG_ BMS_NM_ACTIVE_STS : 28|3@1+ (1,0) [0|7] ""  SMART_CORE
 SG_ BMS_FEATURE_CODE_ERR_STS : 5|2@1+ (1,0) [0|3] ""  SMART_CORE
 SG_ BMS_COMFLT_MSGTOUT_STS : 8|2@1+ (1,0) [0|3] ""  SMART_CORE

BO_ 1002 BMS17_100: 8 Vector__XXX
 SG_ BMS_Regen_AH : 32|16@1+ (0.01,0) [0|300] "AH"  SMART_CORE
 SG_ BMS_KiloWattHour : 16|16@1+ (0.01,0) [0|50] "KWH"  SMART_CORE
 SG_ BMS_AmpereHour : 0|16@1+ (0.01,0) [0|300] "Ah"  SMART_CORE

BO_ 980 BMS7_100: 8 Vector__XXX
 SG_ BMS_Batt_Overcurrent_Sta : 48|2@1+ (1,0) [0|3] "NA"  SMART_CORE
 SG_ BMS_DischargePowerAvailable_2 : 16|16@1+ (0.01,0) [0|200] "Kw"  SMART_CORE
 SG_ BMS_DischargePowerAvailable_10 : 0|16@1+ (0.01,0) [0|200] "Kw"  SMART_CORE
 SG_ BMS_BatteryPackSOE : 32|12@1+ (0.01,0) [0|45] "Kwh"  SMART_CORE

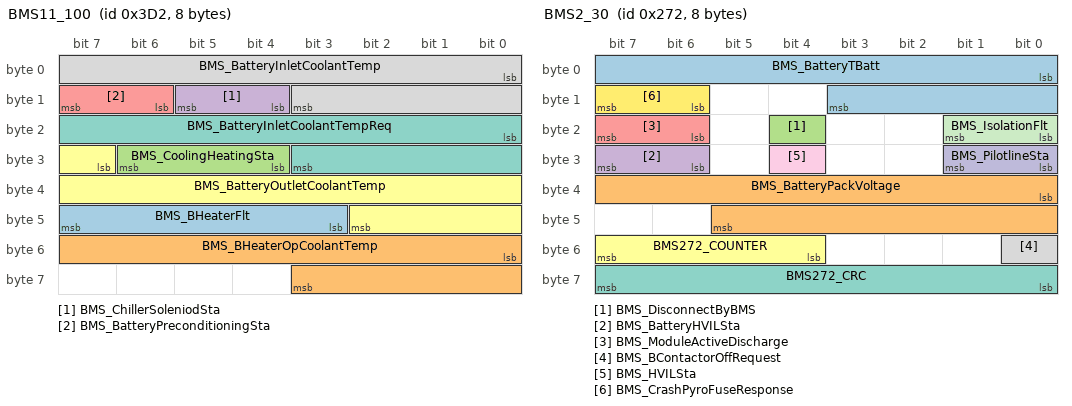
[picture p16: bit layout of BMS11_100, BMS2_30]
BO_ 978 BMS11_100: 8 Vector__XXX
 SG_ BMS_BHeaterFlt : 43|5@1+ (1,0) [0|32] ""  SMART_CORE
 SG_ BMS_BHeaterOpCoolantTemp : 48|12@1+ (0.1,-40) [-40|200] "deg C"  SMART_CORE
 SG_ BMS_CoolingHeatingSta : 28|3@1+ (1,0) [0|7] ""  SMART_CORE
 SG_ BMS_ChillerSoleniodSta : 12|2@1+ (1,0) [0|3] ""  SMART_CORE
 SG_ BMS_BatteryPreconditioningSta : 14|2@1+ (1,0) [0|3] ""  SMART_CORE
 SG_ BMS_BatteryOutletCoolantTemp : 31|12@1+ (0.1,-40) [-40|125] "deg C"  SMART_CORE
 SG_ BMS_BatteryInletCoolantTempReq : 16|12@1+ (0.1,-40) [-40|125] "deg C"  SMART_CORE
 SG_ BMS_BatteryInletCoolantTemp : 0|12@1+ (0.1,-40) [-40|125] "deg C"  SMART_CORE

BO_ 626 BMS2_30: 8 Vector__XXX
 SG_ BMS_BatteryTBatt : 0|12@1+ (0.1,-40) [-40|125] "deg C"  SMART_CORE
 SG_ BMS_BatteryPackVoltage : 32|14@1+ (0.1,0) [0|460] "V"  SMART_CORE
 SG_ BMS_DisconnectByBMS : 20|1@1+ (1,0) [0|1] ""  SMART_CORE
 SG_ BMS_BatteryHVILSta : 30|2@1+ (1,0) [0|3] "NA"  SMART_CORE
 SG_ BMS_ModuleActiveDischarge : 22|2@1+ (1,0) [0|3] ""  SMART_CORE
 SG_ BMS272_COUNTER : 52|4@1+ (1,0) [0|0] "NA"  SMART_CORE
 SG_ BMS272_CRC : 56|8@1+ (1,0) [0|0] "NA"  SMART_CORE
 SG_ BMS_BContactorOffRequest : 48|1@1+ (1,0) [0|1] "NA"  SMART_CORE
 SG_ BMS_HVILSta : 28|1@1+ (1,0) [0|1] "NA"  SMART_CORE
 SG_ BMS_PilotlineSta : 24|2@1+ (1,0) [0|3] "NA"  SMART_CORE
 SG_ BMS_IsolationFlt : 16|2@1+ (1,0) [0|3] "NA"  SMART_CORE
 SG_ BMS_CrashPyroFuseResponse : 14|2@1+ (1,0) [0|3] ""  SMART_CORE

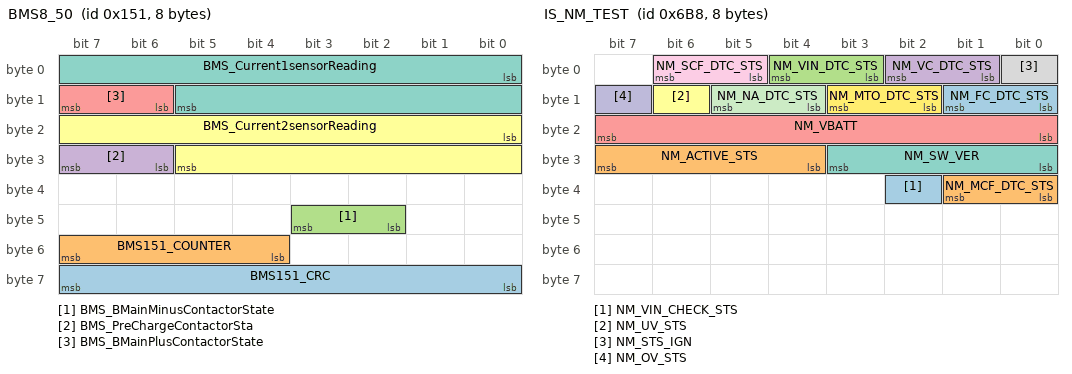
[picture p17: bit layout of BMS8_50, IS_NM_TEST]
BO_ 337 BMS8_50: 8 Vector__XXX
 SG_ BMS151_CRC : 56|8@1+ (1,0) [0|0] "NA"  SMART_CORE
 SG_ BMS151_COUNTER : 52|4@1+ (1,0) [0|0] "NA"  SMART_CORE
 SG_ BMS_BMainMinusContactorState : 42|2@1+ (1,0) [0|3] "NA"  SMART_CORE
 SG_ BMS_PreChargeContactorSta : 30|2@1+ (1,0) [0|3] ""  SMART_CORE
 SG_ BMS_BMainPlusContactorState : 14|2@1+ (1,0) [0|3] "NA"  SMART_CORE
 SG_ BMS_Current2sensorReading : 16|14@1+ (0.1,-600) [-600|600] "A"  SMART_CORE
 SG_ BMS_Current1sensorReading : 0|14@1+ (0.1,-600) [-600|600] "A"  SMART_CORE

BO_ 1720 IS_NM_TEST: 8 SMART_CORE
 SG_ NM_VIN_CHECK_STS : 34|1@1+ (1,0) [0|1] "" Vector__XXX
 SG_ NM_MCF_DTC_STS : 32|2@1+ (1,0) [0|3] "" Vector__XXX
 SG_ NM_VIN_DTC_STS : 3|2@1+ (1,0) [0|3] "" Vector__XXX
 SG_ NM_VC_DTC_STS : 1|2@1+ (1,0) [0|3] "" Vector__XXX
 SG_ NM_VBATT : 16|8@1+ (0.1,0) [0|25] "Volt" Vector__XXX
 SG_ NM_UV_STS : 14|1@1+ (1,0) [0|1] "" Vector__XXX
 SG_ NM_SW_VER : 24|4@1+ (1,0) [0|15] "" Vector__XXX
 SG_ NM_STS_IGN : 0|1@1+ (1,0) [0|1] "" Vector__XXX
 SG_ NM_SCF_DTC_STS : 5|2@1+ (1,0) [0|3] "" Vector__XXX
 SG_ NM_OV_STS : 15|1@1+ (1,0) [0|1] "" Vector__XXX
 SG_ NM_NA_DTC_STS : 12|2@1+ (1,0) [0|3] "" Vector__XXX
 SG_ NM_MTO_DTC_STS : 10|2@1+ (1,0) [0|3] "" Vector__XXX
 SG_ NM_FC_DTC_STS : 8|2@1+ (1,0) [0|3] "" Vector__XXX
 SG_ NM_ACTIVE_STS : 28|4@1+ (1,0) [0|15] "" Vector__XXX

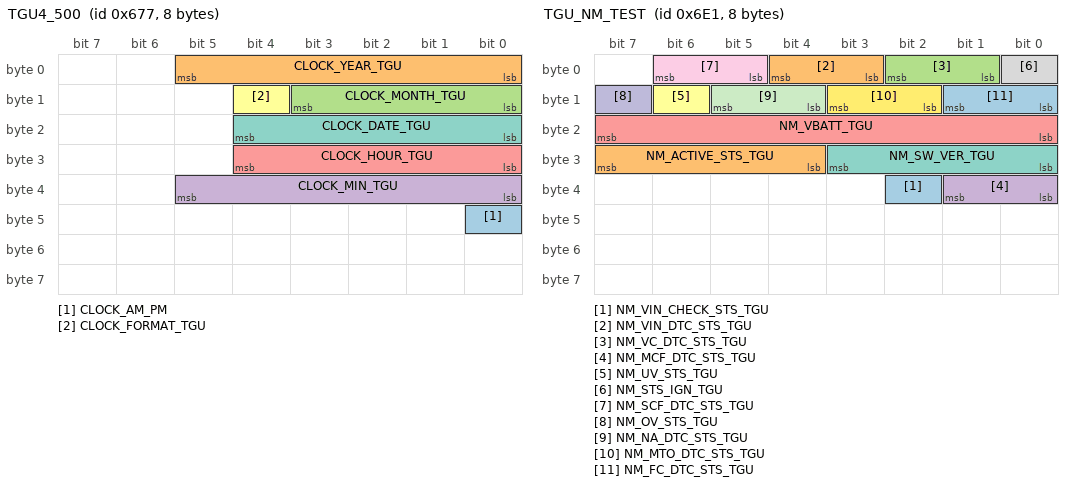
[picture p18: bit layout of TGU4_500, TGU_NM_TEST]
BO_ 1655 TGU4_500: 8 SMART_CORE
 SG_ CLOCK_AM_PM : 40|1@1+ (1,0) [0|1] "" Vector__XXX
 SG_ CLOCK_YEAR_TGU : 0|6@1+ (1,2000) [2016|2063] "" Vector__XXX
 SG_ CLOCK_MONTH_TGU : 8|4@1+ (1,0) [0|12] "" Vector__XXX
 SG_ CLOCK_MIN_TGU : 32|6@1+ (1,0) [0|59] "Minute" Vector__XXX
 SG_ CLOCK_HOUR_TGU : 24|5@1+ (1,0) [0|23] "Hour" Vector__XXX
 SG_ CLOCK_FORMAT_TGU : 12|1@1+ (1,0) [0|1] "" Vector__XXX
 SG_ CLOCK_DATE_TGU : 16|5@1+ (1,0) [0|31] "" Vector__XXX

BO_ 339 TGU2_100: 8 SMART_CORE
 SG_ TGU_CHARGINGENDTIME_FORMAT m1 : 3|1@1+ (1,0) [-1|0] "" Vector__XXX
 SG_ TGU_CHARGINGSTARTTIME_FORMAT m0 : 4|1@1+ (1,0) [0|1] "" Vector__XXX
 SG_ TGU_CHRG_STRT_TIME_HOURS m0 : 5|5@1+ (1,0) [0|24] "" Vector__XXX
 SG_ TGU_ENERGYCONS m0 : 48|8@1+ (1,0) [0|255] "" Vector__XXX
 SG_ TGU_EV_CHRG_PARAM_INDEX M : 0|2@1+ (1,0) [0|3] "" Vector__XXX
 SG_ TGU_CHARGINGSTARTTIME_DATE m0 : 16|16@1+ (1,0) [0|31] "" Vector__XXX
 SG_ TGU_CHRG_START_TIME_MIN m0 : 10|6@1+ (1,0) [0|59] "" Vector__XXX
 SG_ TGU_CHARGINGSTARTTIME_MONTH m0 : 32|8@1+ (1,0) [0|12] "" Vector__XXX
 SG_ TGU_CHARGINGSTARTTIME_YEAR m0 : 40|6@1+ (1,2000) [2016|2063] "" Vector__XXX
 SG_ TGU_CHARGINGENDTIME_DATE m1 : 16|16@1+ (1,0) [0|31] "" Vector__XXX
 SG_ TGU_CHARGINGENDTIME_HOURS m1 : 5|5@1+ (1,0) [0|23] "" Vector__XXX
 SG_ TGU_CHARGINGENDTIME_MIN m1 : 10|6@1+ (1,0) [0|59] "" Vector__XXX
 SG_ TGU_CHARGINGENDTIME_MONTH m1 : 32|8@1+ (1,0) [0|12] "" Vector__XXX
 SG_ TGU_CHRGING_DURATION_MIN m1 : 56|6@1+ (1,0) [0|59] "" Vector__XXX
 SG_ TGU_CHARGINGENDTIME_YEAR m1 : 40|6@1+ (1,2000) [2016|2063] "" Vector__XXX
 SG_ TGU_CHRGING_DURATION_HOURS m1 : 48|5@1+ (1,0) [0|24] "" Vector__XXX

BO_ 338 TGU1_100: 8 SMART_CORE
 SG_ TGU_TRIPSTARTTIME_FORMAT m3 : 4|1@1+ (1,0) [0|1] "" Vector__XXX
 SG_ TGU_TRIPENDTIME_FORMAT m4 : 4|1@1+ (1,0) [0|1] "" Vector__XXX
 SG_ TGU_TRIPSTARTTIME_YEAR m3 : 40|6@1+ (1,2000) [2016|2063] "" Vector__XXX
 SG_ TGU_TRIPSTARTTIME_MIN m3 : 10|6@1+ (1,0) [0|59] "" Vector__XXX
 SG_ TGU_TRIP_START_TIME_HOURS m3 : 5|5@1+ (1,0) [0|24] "" Vector__XXX
 SG_ TGU_TRIPENDTIME_YEAR m4 : 40|6@1+ (1,2000) [2016|2063] "" Vector__XXX
 SG_ TGU_TRIPENDTIME_MONTH m4 : 32|8@1+ (1,0) [0|12] "" Vector__XXX
 SG_ TGU_TRIPENDTIME_MIN m4 : 10|6@1+ (1,0) [0|59] "" Vector__XXX
 SG_ TGU_TRIPENDTIME_DATE m4 : 16|16@1+ (1,0) [0|31] "" Vector__XXX
 SG_ TGU_TRIPEFFICIENCY m1 : 6|2@1+ (1,0) [0|3] "" Vector__XXX
 SG_ TGU_TRIPAVGVEHICLESPEED m1 : 24|8@1+ (1,0) [0|255] "" Vector__XXX
 SG_ TGU_TRIP_TOP_SPEED m1 : 32|8@1+ (1,0) [0|254] "" Vector__XXX
 SG_ TGU_TRIP_START_TIME_MONTH m3 : 32|8@1+ (1,0) [0|12] "" Vector__XXX
 SG_ TGU_TRIP_START_TIME_DATE m3 : 16|16@1+ (1,0) [0|31] "" Vector__XXX
 SG_ TGU_TRIP_END_TIME_HOURS m4 : 5|5@1+ (1,0) [0|24] "" Vector__XXX
 SG_ TGU_TRIP_DURATION_MIN m4 : 51|6@1- (1,0) [0|59] "" Vector__XXX
 SG_ TGU_TRIP_DURATION_HOURS m4 : 46|5@1+ (1,0) [0|24] "" Vector__XXX
 SG_ TGU_TRIP_DISTANCE m1 : 8|16@1+ (1,0) [0|650] "" Vector__XXX
 SG_ TGU_TREES_SAVED m0 : 40|16@1+ (1,0) [0|9999] "" Vector__XXX
 SG_ TGU_CO2 m2 : 8|32@1+ (1,0) [0|999999] "" Vector__XXX
 SG_ TGU_EV_KILOMETERS m0 : 8|32@1+ (1,0) [0|999999] "" Vector__XXX
 SG_ TGU_FRESHDATAFLAG m0 : 4|1@1+ (1,0) [0|1] "" Vector__XXX
 SG_ TGU_EV_PARAM_INDEX M : 0|3@1+ (1,0) [-4|3] "" Vector__XXX

BO_ 1761 TGU_NM_TEST: 8 SMART_CORE
 SG_ NM_VIN_CHECK_STS_TGU : 34|1@1+ (1,0) [0|1] "" Vector__XXX
 SG_ NM_VIN_DTC_STS_TGU : 3|2@1+ (1,0) [0|3] "" Vector__XXX
 SG_ NM_VC_DTC_STS_TGU : 1|2@1+ (1,0) [0|3] "" Vector__XXX
 SG_ NM_MCF_DTC_STS_TGU : 32|2@1+ (1,0) [0|3] "" Vector__XXX
 SG_ NM_VBATT_TGU : 16|8@1+ (0.1,0) [0|25] "Volt" Vector__XXX
 SG_ NM_UV_STS_TGU : 14|1@1+ (1,0) [0|1] "" Vector__XXX
 SG_ NM_SW_VER_TGU : 24|4@1+ (1,0) [0|15] "" Vector__XXX
 SG_ NM_STS_IGN_TGU : 0|1@1+ (1,0) [0|1] "" Vector__XXX
 SG_ NM_SCF_DTC_STS_TGU : 5|2@1+ (1,0) [0|3] "" Vector__XXX
 SG_ NM_OV_STS_TGU : 15|1@1+ (1,0) [0|1] "" Vector__XXX
 SG_ NM_NA_DTC_STS_TGU : 12|2@1+ (1,0) [0|3] "" Vector__XXX
 SG_ NM_MTO_DTC_STS_TGU : 10|2@1+ (1,0) [0|3] "" Vector__XXX
 SG_ NM_FC_DTC_STS_TGU : 8|2@1+ (1,0) [0|3] "" Vector__XXX
 SG_ NM_ACTIVE_STS_TGU : 28|4@1+ (1,0) [0|15] "" Vector__XXX

BO_ 999 BMS5_100: 8 Vector__XXX
 SG_ BMS_BatteryMaxCellVoltage : 16|14@1+ (1,0) [0|5000] "mV"  SMART_CORE
 SG_ BMS_BatteryMinCellVoltage : 32|14@1+ (1,0) [0|5000] "mV"  SMART_CORE
 SG_ BMS_BatteryDisconnectSta : 60|4@1+ (1,0) [0|15] ""  SMART_CORE
 SG_ BMS_BatteryConnectSta : 52|4@1+ (1,0) [0|15] "NA"  SMART_CORE
 SG_ BMS_BatteryAvgCellVoltage : 0|14@1+ (1,0) [0|5000] "mV"  SMART_CORE

BO_ 1000 BMS4_100: 8 Vector__XXX
 SG_ BMS_BatteryPackSOH : 32|10@1+ (0.1,0) [0|100] "%"  SMART_CORE
 SG_ BMS_BatteryPackRSOC : 16|10@1+ (0.1,0) [0|100] "%"  SMART_CORE
 SG_ BMS_BatteryPackASOC : 0|10@1+ (0.1,0) [0|100] "%"  SMART_CORE

BO_ 2005 TGU_DIAG_REQ: 8 Vector__XXX
 SG_ DIAG_TGU_REQ_DATA : 0|64@1+ (1,0) [0|1.8446744074E+019] ""  SMART_CORE

BO_ 2013 TGU_DIAG_RES: 8 SMART_CORE
 SG_ DIAG_TGU_RES_DATA : 0|64@1+ (1,0) [0|1.8446744074E+019] "" Vector__XXX

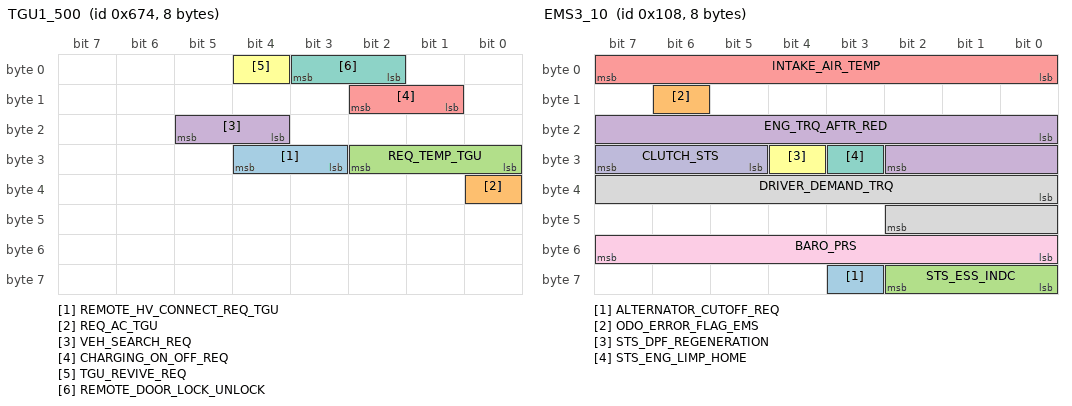
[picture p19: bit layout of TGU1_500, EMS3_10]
BO_ 1652 TGU1_500: 8 SMART_CORE
 SG_ REMOTE_HV_CONNECT_REQ_TGU : 27|2@1+ (1,0) [0|3] "" Vector__XXX
 SG_ REQ_AC_TGU : 32|1@1+ (1,0) [0|1] "" Vector__XXX
 SG_ REQ_TEMP_TGU : 24|3@1+ (1,0) [0|7] "" Vector__XXX
 SG_ VEH_SEARCH_REQ : 20|2@1+ (1,0) [0|3] "" Vector__XXX
 SG_ CHARGING_ON_OFF_REQ : 9|2@1+ (1,0) [0|3] "" Vector__XXX
 SG_ TGU_REVIVE_REQ : 4|1@1+ (1,0) [0|1] "" Vector__XXX
 SG_ REMOTE_DOOR_LOCK_UNLOCK : 2|2@1+ (1,0) [0|3] "" Vector__XXX

BO_ 374 AMT5_20: 8 Vector__XXX
 SG_ ENGINE_STOP_AMT : 14|1@1+ (1,0) [0|1] ""  SMART_CORE
 SG_ TGS_MODE_AMT : 10|2@1+ (1,0) [0|3] ""  SMART_CORE
 SG_ TCU_SHIFT_MODE : 8|2@1+ (1,0) [0|3] ""  SMART_CORE
 SG_ GEAR_ACTUAL_AMT : 0|4@1+ (1,0) [0|15] ""  SMART_CORE

BO_ 264 EMS3_10: 8 Vector__XXX
 SG_ ALTERNATOR_CUTOFF_REQ : 59|1@1+ (1,0) [0|1] ""  SMART_CORE
 SG_ ODO_ERROR_FLAG_EMS : 14|1@1+ (1,0) [0|1] ""  SMART_CORE
 SG_ STS_ESS_INDC : 56|3@1+ (1,0) [0|7] ""  SMART_CORE
 SG_ ENG_TRQ_AFTR_RED : 16|11@1+ (1,-1024) [-1024|1022] "Nm"  SMART_CORE
 SG_ INTAKE_AIR_TEMP : 0|8@1+ (1,-40) [-40|214] "DegC"  SMART_CORE
 SG_ STS_DPF_REGENERATION : 28|1@1+ (1,0) [0|1] ""  SMART_CORE
 SG_ STS_ENG_LIMP_HOME : 27|1@1+ (1,0) [0|1] ""  SMART_CORE
 SG_ DRIVER_DEMAND_TRQ : 32|11@1+ (1,-1024) [-1024|1022] "Nm"  SMART_CORE
 SG_ BARO_PRS : 48|8@1+ (1,0) [0|254] "Kpa"  SMART_CORE
 SG_ CLUTCH_STS : 29|3@1+ (1,0) [0|7] ""  SMART_CORE

BO_ 1919 MGM_DIAG_RES: 8 Vector__XXX
 SG_ DIAG_MGM_RES_DATA : 0|64@1+ (1,0) [0|1.8446744074E+019] ""  SMART_CORE

BO_ 1911 MGM_DIAG_REQ: 8 SMART_CORE
 SG_ DIAG_MGM_REQ_DATA : 0|64@1+ (1,0) [0|1.8446744074E+019] ""  SMART_CORE

BO_ 1980 LDC_DIAG_RES: 8 Vector__XXX
 SG_ DIAG_LDC_RES_DATA : 0|64@1+ (1,0) [0|1.8446744074E+019] "NA"  SMART_CORE

BO_ 2008 MCU_DIAG_RES: 8 Vector__XXX
 SG_ DIAG_MCU_RES_DATA : 0|64@1+ (1,0) [0|0] ""  SMART_CORE

BO_ 579 VCU_EVCAN_WAKEUP: 8 Vector__XXX
 SG_ VCU_EVCAN_WAKEUPREASONRESERVED2 : 24|40@1+ (1,0) [0|5] "NA"  SMART_CORE
 SG_ VCU_EVCAN_WAKEUPREASONRESERVED1 : 0|8@1+ (1,0) [0|5] "NA"  SMART_CORE
 SG_ VCU_EVCAN_WAKEUPREASON : 8|16@1+ (1,0) [0|5] "NA"  SMART_CORE

CM_ BO_ 3221225472 "This is a message for not used signals, created by Vector CANdb++ DBC OLE DB Provider.";
CM_ SG_ 3221225472 FR_SEAT_HEAT_VENT_LEVEL_MBFM "Seat heat/vent level control from MBFM to SCM";
CM_ SG_ 3221225472 FL_SEAT_HEAT_VENT_LEVEL_MBFM "Seat heat/vent level control from MBFM to SCM";
CM_ SG_ 445 ITA_ACTIVE "INTELLIGENT TURN ASSIST";
CM_ SG_ 445 CCO_WARNING "cRAWL cONTROL oPERATION";
CM_ SG_ 445 CCO_SET_SPD "cRAWL cONTROL oPERATION";
CM_ SG_ 445 CCO_ACTIVE "cRAWL cONTROL oPERATION";
CM_ SG_ 1007 VCU_TorqueCoasting "Coast regen torque information";
CM_ SG_ 1007 VCU_SwitchS2 "S2 Switch status";
CM_ SG_ 1007 VCU_StCreep "Creep Activation flag status";
CM_ SG_ 1007 VCU_StCoasting "Coasting activation flag status";
CM_ SG_ 1007 VCU_HVAccPowerConsumption "Power consumption by HV accessories(mcu,ldc ,hvac,battery heater)";
CM_ SG_ 1007 VCU_EConsPerKm "Total energy consumption per km";
CM_ BO_ 823 "VCU Critical Signals 01";
CM_ SG_ 823 VCU_StsCodEvse "EVSE Status Code";
CM_ SG_ 823 VCU_MaxDischargeCurrent "Maximum DC current allowed for discharging the high power battery.
";
CM_ SG_ 823 VCU_MaxChargeCurrent "Maximum DC current allowed for charging the high power battery.";
CM_ SG_ 823 VCU_CmdTargetVoltLDC "Low Votage(12V) Output LDC Target voltage";
CM_ SG_ 823 VCU337_COUNTER "Message Counter";
CM_ SG_ 823 VCU337_CRC "CRC, CHECKSUM ERROR as per SAEJ1850";
CM_ SG_ 823 VCU_CmdEnableLDC "VCU sends Enable command to LDC";
CM_ SG_ 823 VCU_MainContactorControl "Main Contactor Control Request";
CM_ SG_ 443 VCU_ExMeDi_ErrStsEmpowdNoneCrit "Emergency PowerDown None Critical Error Status";
CM_ SG_ 443 VCU_ExMeDi_ErrStsEmpowdCrit "Emergency PowerDown Critical Error Status";
CM_ SG_ 443 VCU_TrigMsgTxCyclc "Trigger Message Cyclic Transmit";
CM_ SG_ 443 VCU_MsgRxCyclc "Cyclic Message received";
CM_ SG_ 443 VCU_StsVehRdy "Status of EV ready to charge";
CM_ SG_ 443 VCU_StsComAsscn "SLAC_Association step indication";
CM_ SG_ 443 VCU_ErrEveh "EV Error Indicator";
CM_ SG_ 443 VCU_USetPointChrgn "EV Target Voltage Value";
CM_ SG_ 443 VCU_StMacSts "State Machine Status";
CM_ SG_ 443 VCU_ISetPointChrgn "EV Target Current Value";
CM_ SG_ 628 LDC_HVIL_Interlock4 "LDC HVIL interlock status for AC input connector";
CM_ SG_ 628 LDC_ACTV_Discharge_STS "HV Active Discharging Status";
CM_ SG_ 628 LDC_OperationMode "LDC Operation modes
";
CM_ SG_ 628 LDC_FCVoltageValue "LDC Fast Charge voltage
";
CM_ SG_ 628 LDC274_COUNTER "Message Counter";
CM_ SG_ 628 LDC274_CRC "CRC, CHECKSUM ERROR as per SAEJ1850";
CM_ SG_ 628 LDC_HVIL_Interlock3 "LDC HVIL interlock status for Battery Heater, Cabin Heater & Compressor";
CM_ SG_ 628 LDC_HVIL_Interlock2 "LDC HVIL interlock status for MCU, Battery connectors";
CM_ SG_ 628 LDC_HVIL_Interlock1 "LDC HVIL interlock status for FC connector";
CM_ SG_ 991 LDC_OPV_Circuit_Error "LDC_output voltage_Circuit_Error";
CM_ SG_ 991 LDC_Low_Temp_Shutdown "LDC_Low_Temp_Shutdown";
CM_ SG_ 991 LDC_IPV_Circuit_Error "LDC_input voltage_Circuit_Error";
CM_ SG_ 991 LDC_INTERNAL_FAIL "LDC_INTERNAL_FAIL";
CM_ SG_ 991 LDC_Input_Over_Current "LDC_Input_Over_Current";
CM_ SG_ 991 LDC_Heat_Sink_Over_Temp_Shutdown "Heat Sink Over Temp Shutdown";
CM_ SG_ 991 LDC_Vprog_Out_of_Range "Vprog out of range
";
CM_ SG_ 991 LDC_Watchdog_Failure "Watchdog Failure";
CM_ SG_ 991 LDC_VCU_Node_Absent "Node Absent";
CM_ SG_ 991 LDC_Temp_Sensing_Failure "LDC Temperature Sensing Failure";
CM_ SG_ 991 LDC_IPC_COMM_ERR_OBC "IPC Communication Error OBC";
CM_ SG_ 991 LDC_EEPROM_Failure "EEPROM Failure";
CM_ SG_ 991 LDC_Short_Circuit "Short Circuit";
CM_ SG_ 991 LDC_Output_Under_Voltage "Output Under Voltage";
CM_ SG_ 991 LDC_Output_Over_Voltage "Output Over Voltage";
CM_ SG_ 991 LDC_Output_Over_Current "Output Over Current";
CM_ SG_ 991 LDC_LPS_Under_Voltage "LPS Under Voltage";
CM_ SG_ 991 LDC_LPS_Over_Voltage "LPS Over Voltage";
CM_ SG_ 991 LDC_Input_Under_Voltage "Input Voltage Under Voltage";
CM_ SG_ 991 LDC_Input_Over_Voltage "Input Over Voltage";
CM_ SG_ 991 LDC_Heat_Sink_Over_Temp_Wng_2 "Heat Sink Over Temp Warning 2";
CM_ SG_ 991 LDC_Heat_Sink_Over_Temp_Wng_1 "Heat Sink Over Temp Warning 1";
CM_ SG_ 991 LDC_Heat_Sink_Over_Temp_Wng_0 "Heat Sink Over Temp Warning 0";
CM_ SG_ 991 LDC_Amb_Over_Temp_Wng "Ambient over temp Warning";
CM_ SG_ 991 LDC_Amb_Over_Temp_Shutdown "Ambient over temp Shutdown";
CM_ BO_ 580 "LDC Normal Signals 02";
CM_ SG_ 580 LDC_OutputVoltageValue "LDC output voltage";
CM_ SG_ 580 LDC_OutputCurrent "LDC output current
";
CM_ SG_ 580 LDC_InputVoltageValue "LDC input voltage
";
CM_ SG_ 580 LDC_InputCurrentValue "LDC input current";
CM_ BO_ 989 "LDC Normal Signals 01";
CM_ SG_ 989 LDC_Primary_Temperature "LDC temperature- Primary DC-DC Temperature";
CM_ SG_ 989 LDC_CoolingRequest "LDC_Cooling Request signal";
CM_ SG_ 989 LDC_MOSFET_Temperature "LDC temperature- MOSFET DC-DC Temperature";
CM_ SG_ 989 LDC_Secondary_Temperature "LDC temperature -Secondary DC-DC  temperature";
CM_ SG_ 989 LDC_ProtectionMode "LDC Protection Mode ";
CM_ BO_ 825 "BMS Normal Signals 04";
CM_ SG_ 825 BMS_BatteryMinTemperature "Battery Min temperature";
CM_ SG_ 825 BMS_BatteryMaxTemperature "Battery Max temperature";
CM_ SG_ 825 BMS_Actual_Batt_Heater_Pwr "Actual power consumed by Battery heater ";
CM_ SG_ 825 BMS_Req_Batt_Heater_Pwr "Battery Heater Power requested by BMS";
CM_ SG_ 825 BMS_ChargingStop "BMS request Charging stop";
CM_ SG_ 825 BMS_BCoolingRequest "setting the cooling request to On or OFF completely";
CM_ BO_ 979 "BMS Normal Signals 07";
CM_ SG_ 979 BMS_Discharge_Cycle "Charge Cycle Calculation";
CM_ SG_ 979 BMS_Charge_Cycle "Charge Cycle Calculation";
CM_ SG_ 979 BMS_ChargePowerAvailable_2 "Battery available charge power in the next 2s(SOP)";
CM_ SG_ 979 BMS_ChargePowerAvailable_10 "Battery available charge power in the next 10s(SOP)";
CM_ BO_ 1005 "BMS Normal Signals 08";
CM_ SG_ 1005 BMS_BattBalancingCompSta "Indicates whether Balancing is Completed or not completed";
CM_ SG_ 1005 BMS_BatteryBalancingSta "Indicates whether Balancing is active or not";
CM_ SG_ 1005 BMS_BCoolPumpFBSta "Battery coolant pump feedback  (Like Dry run ..etc)";
CM_ SG_ 1005 BMS_BatteryLowSOC "HV Battery Low battery SOC warning message";
CM_ SG_ 1005 BMS_BatteryAvgTemperature "Battery Average Termperature";
CM_ SG_ 1005 BMS_STS_IGN "BMS IGN KL 15 detect information";
CM_ SG_ 1005 BMS_CellVoltHighWarnDegdFault "HV Battery cell high voltage warning / fault information";
CM_ SG_ 1005 BMS_BPlusContactorWeld "HV Battery Postive contactor weld status";
CM_ SG_ 1005 BMS_BMinusContactorWeld "HV Battery Negative contactor weld status";
CM_ BO_ 301 "BMS Critical Signals 01";
CM_ SG_ 301 BMS_ACTV_Discharge_STS "HV Active Discharging Status";
CM_ SG_ 301 BMS273_COUNTER "Message Counter";
CM_ SG_ 301 BMS273_CRC "CRC, CHECKSUM ERROR as per SAEJ1850";
CM_ SG_ 301 BMS_BatteryBusVoltage "HV Battery Bus voltage (After contactor)";
CM_ SG_ 301 BMS_BatteryPackStatus "Battery Pack Status";
CM_ SG_ 301 BMS_BatteryPackCurrent "Battery Pack Current ";
CM_ SG_ 301 BMS_OperationMode "BMS Operation Modes
(BMS Internal Status)";
CM_ SG_ 1003 BMS_CellTemp9 "Battery Cell temperature 9";
CM_ SG_ 1003 BMS_CellTemp8 "Battery Cell temperature 8";
CM_ SG_ 1003 BMS_CellTemp7 "Battery Cell temperature 7";
CM_ SG_ 1003 BMS_CellTemp6 "Battery Cell temperature 6";
CM_ SG_ 1003 BMS_CellTemp5 "Battery Cell temperature 5";
CM_ SG_ 1003 BMS_CellTemp4 "Battery Cell temperature 4";
CM_ SG_ 1003 BMS_CellTemp32 "Battery Cell temperature 32";
CM_ SG_ 1003 BMS_CellTemp31 "Battery Cell temperature 31";
CM_ SG_ 1003 BMS_CellTemp30 "Battery Cell temperature 30";
CM_ SG_ 1003 BMS_CellTemp29 "Battery Cell temperature 29";
CM_ SG_ 1003 BMS_CellTemp28 "Battery Cell temperature 28";
CM_ SG_ 1003 BMS_CellTemp27 "Battery Cell temperature 27";
CM_ SG_ 1003 BMS_CellTemp26 "Battery Cell temperature 26";
CM_ SG_ 1003 BMS_CellTemp25 "Battery Cell temperature 25";
CM_ SG_ 1003 BMS_CellTemp24 "Battery Cell temperature 24";
CM_ SG_ 1003 BMS_CellTemp23 "Battery Cell temperature 23";
CM_ SG_ 1003 BMS_CellTemp22 "Battery Cell temperature 22";
CM_ SG_ 1003 BMS_CellTemp21 "Battery Cell temperature 21";
CM_ SG_ 1003 BMS_CellTemp20 "Battery Cell temperature 20";
CM_ SG_ 1003 BMS_CellTemp19 "Battery Cell temperature 19";
CM_ SG_ 1003 BMS_CellTemp18 "Battery Cell temperature 18";
CM_ SG_ 1003 BMS_CellTemp17 "Battery Cell temperature 17";
CM_ SG_ 1003 BMS_CellTemp16 "Battery Cell temperature 16";
CM_ SG_ 1003 BMS_CellTemp15 "Battery Cell temperature 15";
CM_ SG_ 1003 BMS_CellTemp14 "Battery Cell temperature 14";
CM_ SG_ 1003 BMS_CellTemp13 "Battery Cell temperature 13";
CM_ SG_ 1003 BMS_CellTemp12 "Battery Cell temperature 12";
CM_ SG_ 1003 BMS_CellTemp11 "Battery Cell temperature 11";
CM_ SG_ 1003 BMS_CellTemp10 "Battery Cell temperature 10";
CM_ SG_ 1003 BMS_CellTemp3 "Battery Cell temperature 3";
CM_ SG_ 1003 BMS_CellTemp2 "Battery Cell temperature 2";
CM_ SG_ 1003 BMS_CellTemp1 "Battery Cell temperature 1";
CM_ SG_ 1003 BMS_CellTemp_Index "BMS Cell Temp Index signal";
CM_ BO_ 981 "BMS Normal Signals 12";
CM_ SG_ 981 BMS3D5_CRC "CRC, CHECKSUM ERROR as per SAEJ1850";
CM_ SG_ 981 BMS3D5_COUNTER "Message Counter";
CM_ SG_ 981 BMS_BatteryInstantEnergyCons "Battery Instant Energy consumption";
CM_ SG_ 981 BMS_AveEnergyCons "BMS Average Energy consumption - Indication purpose";
CM_ SG_ 981 BMS_ALERT_MSGS "BMS Alert Message Values";
CM_ SG_ 981 BMS_STS_CHARGE_LIGHT_TT "Charge Light Status";
CM_ SG_ 981 BMS_SERVICE_LIGHT_TT "BMS SERVICE LIGHT TEL TALE";
CM_ SG_ 981 BMS_HV_BATT_TT "BMS HV Battery Failure TellTale";
CM_ SG_ 981 BMS_HIGH_TEMP_LIGHT_OP_TT "BMS HIGH TEMPERATURE LIGHT OUTPUT TEL TALE";
CM_ SG_ 981 BMS_EVWARNING_TT "BMS EV WARNING TELL TALE";
CM_ SG_ 1585 ICC_ALERT_MSG "Alert message from ICC to cluster";
CM_ SG_ 2019 DIAG_TC_REQ_DATA "TPMS Diagnostics Request";
CM_ BO_ 870 "MCM to PKE Authentication message";
CM_ SG_ 870 PKE_CHALLENGE_STS_MCM "PKE Challenge Recieve status";
CM_ SG_ 1280 IC11_MSG_CNT "EMS21 message counter";
CM_ SG_ 1280 IC11_CRC "EMS21 message checksum";
CM_ SG_ 1280 IC_STEERING_MODE_REQ "EPS sterring mode request from Cluster";
CM_ SG_ 154 MCM_WAKEUP_REASON "Reason for wake-up.";
CM_ SG_ 1587 MCM1_CRC "CRC implementation for the Message";
CM_ SG_ 1587 REQ_HEADLAMP_MCM "Turn ON/OFF headlamp request from MCM.";
CM_ BO_ 1144 "MBFM1_100";
CM_ SG_ 1144 PSGR_REAR_SEAT_BELT_SBRM "BIT 0:- Rear Left Passenger
BIT 1:- Rear Middle Passenger
BIT 2:- Rear Right Passenger
BIT 3:- Rear 3rd RowLeft Passenger
BIT 4:- Rear 3rd Row Middle Passenger
BIT 5:- Rear 3rd Row Right Passenger

0x0:-Not Buckled/DV
0x1:-Buckled";
CM_ SG_ 563 DIST_DEF_EMPTY "Distance till the DEF level is empty.";
CM_ SG_ 563 INDC_REGEN "0x00= telltale OFF/No manual regenaration needed/regen completed/Default value
0x01=telltale ON/Manual regenaration needed/regen not completed(requested by IC)
0x02=telltale blink/Manual regenaration in progress/regen request accepted(requested by IC)";
CM_ SG_ 563 STS_DEF "Urea status

Bit 0: Incorrect DEF
Bit 1: DEF level low
Bit2: DEF dosing malfunction

0 - Error inactive       1 - Error active";
CM_ SG_ 295 ACC_PED_ACTUAL "raw value of acc pedal.";
CM_ SG_ 295 ENG_LOSSES "Engine losses";
CM_ SG_ 295 EMS21_MSG_CNT "EMS21 message counter";
CM_ SG_ 295 EMS21_CRC "EMS21 message checksum";
CM_ SG_ 295 BRK_PEDAL1 "Break Pedal Signal";
CM_ SG_ 375 TGS_LEVER_AMT "Transmission Gear Select lever position.
";
CM_ SG_ 304 ACC_READY "Adaptive Cruise Control (ACC) function available status";
CM_ SG_ 304 EMS_DRIVE_ALERT "EMS DRIVE MODE:-DRIVE mode status indication to IC in case of failure.";
CM_ SG_ 304 STS_EMS_DRV_ADV_MODE "Feedback indication to ESC for Terrain or Adventure response mode.";
CM_ SG_ 1638 ASD_TORQUE "Adventure statistics torque display in percentage";
CM_ SG_ 1638 ASD_POWER "Adventure statistics power display in percentage";
CM_ SG_ 1079 IDLING_DURATION "Unwanted Idling duration";
CM_ SG_ 1078 AVG_SPD "Average Speed";
CM_ SG_ 1078 TOP_SPD "Top Speed";
CM_ SG_ 1078 TRIP_DIST "Trip Distance";
CM_ SG_ 1078 TRIP_DURATION_HOUR "Trip Duration";
CM_ SG_ 1077 IDLING_INDEX "Unwanted Idling Index";
CM_ SG_ 1077 GEAR_MISMATCH "Gear RPM Mismatch Index";
CM_ SG_ 1077 OVR_SPD "Overspeed Index indication to infotainment";
CM_ SG_ 1077 CLTH_OVRRIDE "Clutch Override Index indication to infotainment";
CM_ SG_ 1077 AGG_BRK "Aggressive Braking Index indication to infotainment";
CM_ SG_ 1077 AGG_ACC "Aggressive Acceleration Index to infotainment";
CM_ SG_ 1077 STS_TRIP "Trip Status to infotaiment";
CM_ SG_ 1077 COMM_ERR_FLG "Communication Error Flag indication to infotainment";
CM_ SG_ 1077 TPMS_FLG "TPMS Indication Request to Infotainment";
CM_ SG_ 1077 AC_USAGE_REG_FLG "AC Usage Indication Request to infotainment
";
CM_ SG_ 1077 IDLING_FLG "Idling Indication Request to infotainment
";
CM_ SG_ 1077 OVRSPD_FLG "Overspeed Indication Request to infotainment";
CM_ SG_ 1077 CLUTCH_OVRRIDE_FLG "Clutch Override Indication Request to Infotainment";
CM_ SG_ 752 SVS_SWT "Only for projects where SVS Switch is hardwired to SMARTCORE / IS ";
CM_ SG_ 752 STS_AUTO_ZOOM_IN_VIEW "AUTO ZOOM IN VIEW
- If this feature is enabled in IS then only camera will switch to auto zoom  
";
CM_ SG_ 752 STS_AUTO_CORNER_VIEW "AUTO CORNER VIEW
- If this feature is enabled in IS then only auto cornered view is available, depending on status of cornering lamp";
CM_ SG_ 752 DEFAULT_VIEW_FRONT "Default view for Front View Camera";
CM_ SG_ 752 DEFAULT_VIEW_REAR "Default view for Rear View Camera";
CM_ SG_ 1584 NOX_UPSTR_MDL "NOx upstream SCR modelled";
CM_ SG_ 1595 KNOCK_SIGNALS_0 "Knock signals
";
CM_ SG_ 1595 KNOCK_SIGNALS_1 "Knock signals
";
CM_ SG_ 1595 KNOCK_SIGNALS_2 "Knock signals
";
CM_ SG_ 1595 KNOCK_SIGNALS_3 "Knock signals
";
CM_ SG_ 1595 MASS_AIR_FLOW "Air mass flow ";
CM_ SG_ 1595 MISFIRE_DETECT_THRESHOLD "Threshold for misfire detection";
CM_ SG_ 1595 MISFIRE_SUM_A "Sum of misfire counters a 
";
CM_ SG_ 1595 MISFIRE_SUM_B "Sum of misfire counters B
 
";
CM_ SG_ 1596 MISFIRE_CTR_A_0 "Misfire counter a per cylinder ";
CM_ SG_ 1596 MISFIRE_CTR_A_1 "Misfire counter a per cylinder ";
CM_ SG_ 1596 MISFIRE_CTR_A_2 "Misfire counter a per cylinder ";
CM_ SG_ 1596 MISFIRE_CTR_A_3 "Misfire counter a per cylinder ";
CM_ SG_ 1596 MISFIRE_CTR_B_0 "Misfire counter B per cylinder ";
CM_ SG_ 1596 MISFIRE_CTR_B_1 "Misfire counter B per cylinder ";
CM_ SG_ 1596 MISFIRE_CTR_B_2 "Misfire counter B per cylinder ";
CM_ SG_ 1596 MISFIRE_CTR_B_3 "Misfire counter B per cylinder ";
CM_ SG_ 1428 BRAKE_PREDICTION_STS "Prognosis - Brake System Prediction";
CM_ SG_ 1582 COMMANDED_EGR "Commanded EGR";
CM_ SG_ 1582 EGR_ERR "EGR_Error";
CM_ SG_ 1582 MEUNT_SETPOINT_RAIL_PRESSURE "Setpoint value (volume flow) of rail pressure";
CM_ SG_ 1582 MEUNT_SETPOINT_ADPT_CORECT "Adaptive correction of metering unit set point value";
CM_ SG_ 1582 MEUNT_CTCL_FLTACT_CURVAL "Metering unit current control filtered actual current value";
CM_ SG_ 1582 FUEL_RAIL_PRESSURE "Fuel Rail pressure";
CM_ BO_ 1967 "Diagnostics response message from FVC";
CM_ SG_ 767 JOYSTICK_DB_STS "JOYSTICK DOWNWARD MOVEMENT";
CM_ SG_ 767 JOYSTICK_UB_STS "JOYSTICK UPWARD MOVEMENT";
CM_ SG_ 767 JOYSTICK_RB_STS "JOYSTICK RIGHT MOVEMENT";
CM_ SG_ 767 JOYSTICK_LB_STS "JOYSTICK LEFT MOVEMENT";
CM_ BO_ 1966 "Diagnostics response message from SCM";
CM_ SG_ 930 SLOT_LENGTH_WIDTH "Slot Length for parallel parking or Slot width for perpendicular parking.";
CM_ SG_ 930 SLOT_DEPTH "Slot Depth .";
CM_ SG_ 930 DIST_TO_SLOT "Distance to Slot  .";
CM_ SG_ 930 DIST_TO_SAFE_PT "Distance to Safe Point .";
CM_ SG_ 930 APA_PROGRESS_PERCNTG "The progress bar display percentage in  a single moving step .";
CM_ SG_ 930 APA_PARK_MODE "Parking mode selected .";
CM_ SG_ 930 APA_PARK_DIRCTION "Parking direction .";
CM_ SG_ 930 APA_DISP_SUB_PIC "Display HMI Sub picture .";
CM_ SG_ 930 APA_DISP_MAIN_PIC "Display HMI main picture .";
CM_ SG_ 930 APA_DISP "HMI Active request";
CM_ SG_ 930 APA_ACTIVE "APA Work Status.";
CM_ SG_ 930 FPAS_SW_STS " PAS Work Status ";
CM_ SG_ 930 MAMS_SWT_STS " CMBS Work Status .";
CM_ SG_ 929 FLS_SEGMENT "Front Left Side display segment .";
CM_ SG_ 929 LEFT_MIN_DIST "Minimum obstacle distance detected by FPAS sensors .";
CM_ SG_ 929 RRMS_SEGMENT "Rear Right Middle Side Sensor Display Segment .";
CM_ SG_ 929 APA_SWITCH_FAULT " APA system Switch  fault information .

bit0: APA
bit1: PAS
bit2:CMBS

0x0 - OK / Default
0x1 - Not OK";
CM_ SG_ 929 FRMS_SEGMENT "Front Right Middle Side Sensor Display Segment.";
CM_ SG_ 929 RIGHT_MIN_DIST "Minimum obstacle distance detected by FPAS sensors .";
CM_ SG_ 929 RRS_SEG_WARN "Rear Right Side Sensor Warning status.";
CM_ SG_ 929 RRMS_SEG_WARN "Rear Right Middle Side Sensor Warning status.";
CM_ SG_ 929 RLMS_SEG_WARN "Rear Left Middle Side Sensor Warning status.";
CM_ SG_ 929 RLS_SEG_WARN "Rear Left Side Sensor Warning status.";
CM_ SG_ 929 FRS_SEG_WARN "Front Right Side Sensor Warning status.";
CM_ SG_ 929 FLMS_SEG_WARN "Front Left Middle Side Sensor Warning status.";
CM_ SG_ 929 RRS_SEGMENT "Rear Right Side Sensor Display Segment .";
CM_ SG_ 929 RLMS_SEGMENT "Rear Left Middle Side Sensor Display Segment.";
CM_ SG_ 929 FLS_SEG_WARN "Front Left Side Sensor Warning status.";
CM_ SG_ 929 FRS_SEGMENT "Front Right Side Sensor Display Segment .";
CM_ SG_ 929 APA_LED_FAULT " APA system LED  fault information .

bit0: APA
bit1: PAS
bit2:CMBS

0x0 - OK / Default
0x1 - Not OK";
CM_ SG_ 929 FRMS_SEG_WARN "Front Right Middle Side Sensor Warning status.";
CM_ SG_ 929 RLS_SEGMENT "Rear Left Side Sensor Display Segment.";
CM_ SG_ 929 FLMS_SEGMENT "Front Left Middle Side Sensor Display Segment .";
CM_ SG_ 1653 METADATA_ID_FOTA "Default -0
";
CM_ SG_ 1653 LAST_EXECUTED_STEP_FOTA "0 default
";
CM_ SG_ 272 CUR_CARD_SHAFT_TRQ "4WD current cardan shaft torque";
CM_ SG_ 272 TRANSFER_MODE_TC "4WD mode";
CM_ SG_ 272 INDC_TC_MALF "Indicates malfunctin of TC to IC";
CM_ SG_ 272 INDC_TC_ALERT "1.2WD to 4WH.The alert to IC - reduce veh spd below 80 kmph.
2.2WD to 4WL or 4WH to 4WL.The alert to IC- MT vehicle(Stop&Shift transmission into N)
3.2WD to 4WL or 4WH to 4WL.The alert to IC - AT vehicle(Stop&Shift transmission intoP or N).
";
CM_ SG_ 158 ICC_WAKEUP_REASON "Reason for wake-up.

0X0 - Any Button Press ( Button 1,2,3,4 & Centre button)
0X1 - Any Joystick Button Press( Joystick DB,LB,RB & UB)";
CM_ SG_ 1594 FAN_SPEED "Fan speed";
CM_ SG_ 1594 AC_PRESSURE "AIr conditioning pressure";
CM_ SG_ 1594 MISFIRE_INHIBIT_STATE "Inhibition state for misfire detection ";
CM_ SG_ 1594 ENG_ROUGHNESS_3 "Engine roughness";
CM_ SG_ 1594 ENG_ROUGHNESS_2 "Engine roughness";
CM_ SG_ 1594 ENG_ROUGHNESS_1 "Engine roughness";
CM_ SG_ 1594 ENG_ROUGHNESS_0 "Engine roughness";
CM_ SG_ 1594 ROUGH_ROAD_COND "State of rough road condition";
CM_ SG_ 1583 SCR_STORE_NH3 "Level of NH3 stored in the SCR catalyst";
CM_ SG_ 1583 FAN_MODE "fan mode";
CM_ SG_ 1583 EXHAUST_MASS_FLOW "Exhaust mass flow 2 ";
CM_ SG_ 1583 ENG_OPERATION_MODE "Engine operation Mode State";
CM_ SG_ 1583 DEF_DOSING_AMT "DEF dosing amount";
CM_ SG_ 1583 NOX_DWNSTR_SCR "NOx downstream SCR";
CM_ SG_ 1583 SCR_MEAN_TEMP "SCR mean temperature";
CM_ SG_ 1583 SOOT_DELTA_PRESSURE "Soot Load Delta pressure model";
CM_ SG_ 1581 MASS_AIR_FLOW_RATE "Air flow rate from mass air flow sensor";
CM_ SG_ 1581 COMMANDED_THRTL_ACTR_CTL "Commanded throttle actuator control";
CM_ SG_ 1581 CAL_LOAD " ratio of driver demand torque to the engine effective torque available at crank shaft";
CM_ SG_ 1413 ENG_OIL_TEMP "Engine Oil Temperature";
CM_ SG_ 1413 ENG_OIL_PRESSURE_VAL "Engine Oil Pressure";
CM_ BO_ 581 "OBC Normal Signals 03";
CM_ SG_ 581 OBC_DCOutputVoltage "Output Voltage
";
CM_ SG_ 581 OBC_DCOutputCurrent "Output Current
";
CM_ SG_ 581 OBC_ACInputVoltageRMS "AC Input Source Voltage (rms)";
CM_ SG_ 581 OBC_ACInputCurrentRMS "AC Input Source Current (rms)";
CM_ SG_ 274 VCU_MsgSt "Message State";
CM_ SG_ 274 VCU_ErrStack "Stack Error";
CM_ SG_ 274 VCU_Isolt_mtr_stp_req "Insulation Monitoring Stop request -- 
During DC Charging EVSE will activate the Isolation monitoring
-> If both EVSE and BMS start monitoring simultaneously, Isolation resistance value will not be proper.";
CM_ SG_ 274 VCU_VehicleState "Vehicle State";
CM_ SG_ 274 VCU_TorqueCommand "TorqueCommand ? (CommandMode = TorqueMode)  Electric motorization torque desired at the motor output shaft (at the input of the gearbox).";
CM_ SG_ 274 VCU_OperationReq "VCU Operation Request";
CM_ SG_ 274 VCU_OperationalModeCmd "Operation command to MCU";
CM_ SG_ 274 VCU_CommandMode "Mode request by VCU";
CM_ SG_ 274 VCU112_COUNTER "Message Counter
";
CM_ SG_ 274 VCU112_Checksum "Checksum";
CM_ SG_ 274 VCU_ACTV_Discharge_REQ "HV Active Discharging request
";
CM_ BO_ 819 "VCU Normal Signals 04";
CM_ SG_ 819 VCU_ValEvsePresU "EVSE Present Voltage Value from Station";
CM_ SG_ 819 VCU_ValEvsePresI "EVSE Present Current Value from Station";
CM_ SG_ 819 VCU_HVDisconnect_Reasons "Reasons for HV Disconnect";
CM_ SG_ 819 VCU_Gear_Actual "Drive Mode - Coming from VCAN";
CM_ SG_ 819 VCU_CmdACPWM "AC PWM(Duty)";
CM_ SG_ 819 VCU_CmdACCP "AC CP Voltage Status";
CM_ SG_ 819 VCU_VehChargeModeSta "Vehicle Charging Mode Status";
CM_ SG_ 819 VCU_PP_CurrentLimit "AC Charger capacity";
CM_ BO_ 821 "VCU Normal Signals 02";
CM_ SG_ 821 VCU_ValEvseIMinLim "EVSE Minimum Current value from EVSE Station";
CM_ SG_ 821 VCU_ValEvseIMaxLim "EVSE Maximum Current limit value from Station";
CM_ SG_ 821 VCU_HVConnect_Sta "Once HV connect is successful, VCU should communicate HV connect successful/ unsuccessful status to TGU.";
CM_ SG_ 821 VCU_ChargingPlugSta "AC/DC Charging plug status ";
CM_ SG_ 821 VCU_DISP_AMBT_TEMP_FATC "Ambient Temperature";
CM_ SG_ 821 VCU_HVACHeatingSta "HVAC Heating status";
CM_ SG_ 821 VCU_HVACCoolingSta "HVAC Cooling Status";
CM_ SG_ 821 VCU_HVACCoolingPower "HVAC Cabin Cooling Power";
CM_ SG_ 821 VCU_ActiveDampingDisableCommand "Active Damping Disable command";
CM_ BO_ 577 "CGW Critical Signals 01";
CM_ SG_ 577 VCU_ExMeDi_IdxDcChrgnErr "For diagnostic and troubleshooting purposes the ExMeDi component computes an error index.
Information given in Value description contains only bit level information,  not exact value";
CM_ SG_ 577 VCU_StMacErr "State Machine Error";
CM_ SG_ 577 VCU_RespCod "Response Code";
CM_ SG_ 577 VCU_MsgSts "Message Status";
CM_ SG_ 577 VCU_Charge_Discharge_Trans "Signal for telling transition from charge to discharge and vice versa";
CM_ SG_ 577 VCU_TransPmotorparkReq "transmission parking request";
CM_ SG_ 577 VCU_eComp_HVIL_Status "Compressor HVIL Status";
CM_ SG_ 577 VCU241_Checksum "Checksum";
CM_ SG_ 577 VCU241_COUNTER "Message Counter";
CM_ SG_ 577 VCU_SRSCrashSta "Crash Information from SRS Unit";
CM_ BO_ 822 "VCU Normal Signals 01";
CM_ SG_ 822 VCU336_CRC "CRC, CHECKSUM ERROR as per SAEJ1850";
CM_ SG_ 822 VCU336_COUNTER "Message Counter";
CM_ SG_ 822 VCU_AUX_BATTERY_VOLT "Aux Battery voltage";
CM_ SG_ 822 VCU_Vehicle_Speed "Vehicle Speed";
CM_ SG_ 822 VCU_STS_IGN "Status of Ignition Key KL15";
CM_ SG_ 822 VCU_EPTCoolantTemp "EPT Coolant Temp";
CM_ SG_ 822 VCU_EPTCoolantFlow "Actual EPT Coolant Flow";
CM_ SG_ 822 VCU_EVReady "Electric Powertrain System Ready for driving.";
CM_ SG_ 437 VCU_BMS_ASW_SleepRequest "This signal will be used for initiating sleep for BMS after VCU triggers MCU , ETL relay off";
CM_ SG_ 437 VCU_SmObc_State "State manager of OBC- Internal state for AC Charging";
CM_ SG_ 437 VCU_Wakeup_Reason_internal "VCU wake up source(Purpose)";
CM_ SG_ 437 VCU_NoSM_State "VCU Normal state- Internal PUPD State";
CM_ SG_ 437 VCU_EVCSI_State "Electric vehicle charging state identifier -- Internal state for DC Charging";
CM_ SG_ 437 VCU_CharPD_RawVal "Porximity detection Raw Value";
CM_ SG_ 437 VCU_CharCP_RawVal "Charging Control Pilot Raw Value";
CM_ SG_ 601 VCU_StsIslnEvse "EVSE Isolation Status";
CM_ SG_ 601 VCU_ValEvseUMinLim "EVSE Minimum Voltage value from EVSE Station";
CM_ SG_ 601 VCU_LV_Battery_Voltage "LV battery voltage measurement";
CM_ SG_ 601 VCU_brake2_voltage "Brake pedal2 volttge";
CM_ SG_ 601 VCU_brake1_voltage "Brake pedal1 voltage";
CM_ SG_ 601 VCU_Accep2_voltage "Accelerator pedal2 voltage";
CM_ SG_ 601 VCU_Accep1_voltage "Accelerator pedal1 voltage";
CM_ SG_ 1731 VCU_ValEvseUMaxLim "EVSE Maximum Voltage limit value from Station";
CM_ SG_ 1731 VCU_CharInletTempNeg "Charging Inlet Temperature at DC Negative";
CM_ SG_ 1731 VCU_PumpSpdFb "VCU Cooling Pump Feedback";
CM_ SG_ 1731 VCU_PumpSpdCtrl "VCU Cooling Pump Control speed";
CM_ SG_ 1731 VCU_CoolFanSpdCtrl "VCU Cooling Fan Control speed";
CM_ SG_ 1731 VCU_CharPlugLockFbSts "Charging Plug Lock Feedback Status";
CM_ SG_ 1731 VCU_CharPlugLockCtrlSts "Charing Plug Lock Control Status";
CM_ SG_ 1731 VCU_CharPlugAtLockSwIndSts "Charging Plug Auto Lock Switch indication Lamp Status";
CM_ SG_ 1731 VCU_CharInletTempPos "Charging Inlet Temperature at DC Positive";
CM_ SG_ 1481 VCU_COMFLT_MSG_CONTFAIL "Message Content Failure";
CM_ SG_ 1481 VCU_COMFLT_SGN_CONTFAIL "Signal Content failure";
CM_ SG_ 1481 VCU_AUX_BATT_VOLT "Aux Battery Voltage";
CM_ SG_ 1481 VCU_UV_STS "NM Undervoltage STS";
CM_ SG_ 1481 VCU_STS_IGN_NM "This is NM IGN status not the actual KL15. It will come with delay of approx 500ms";
CM_ SG_ 1481 VCU_OV_STS "NM Overvoltage STS";
CM_ SG_ 1481 VCU_SW_VERSION "VCU Software Version";
CM_ SG_ 1481 VCU_COMFLT_NODEABS_STS "Node Absent";
CM_ SG_ 1481 VCU_VARIANT_CODE_ERR_STS "VCU Variant Code DTC Status";
CM_ SG_ 1481 VCU_NM_ACTIVE_STS "MCU NM Status";
CM_ SG_ 1481 VCU_FEATURE_CODE_ERR_STS "MCU Feature Code DTC Status";
CM_ SG_ 1481 VCU_COMFLT_MSGTOUT_STS "Key Message Timeout";
CM_ SG_ 988 OBC_Low_Temp_Shutdown "OBC_Low_Temp_Shutdown";
CM_ SG_ 988 OBC_HVDC_HW_OV "OBC Hardware Over Voltage fault";
CM_ SG_ 988 OBC_CPVol_Out_of_Range "OBC_Control Pilot Voltage Out of Range";
CM_ SG_ 988 OBC_CPDuty_Out_of_Range "Hardware Output Over voltage fault";
CM_ SG_ 988 OBC_HVDC_HW_OC "Hardware Output Over Current fault";
CM_ SG_ 988 OBC_PFC_BUS_FAULT_CNT "PFC bus fault count";
CM_ SG_ 988 OBC_PFC_VOLT_CNTRL_IP "PFC Voltage control input";
CM_ SG_ 988 OBC_LIne_OC_SW "Line Overcurrent flag
";
CM_ SG_ 988 OBC_Inductr_current_L2_OC "Inductor2_overcurrent flag";
CM_ SG_ 988 OBC_Inductr_current_L1_OC "Inductor1_overcurrent flag";
CM_ SG_ 988 OBC_VPROG_OUT_OF_RANGE "VPROG Out of Range";
CM_ SG_ 988 OBC_TEMP_SENSOR_FAIL "OBC temperature sensor failure";
CM_ SG_ 988 OBC_OVER_TEMP "OBC Over Temperature";
CM_ SG_ 988 OBC_INTERNAL_FAIL "OBC Internal Failure";
CM_ SG_ 988 OBC_HIGH_TEMP "OBC High Temperature";
CM_ SG_ 988 OBC_IPROG_OUT_OF_RANGE "IPROG Out of Range";
CM_ SG_ 988 OBC_EMI_IP_UV "EMI input under voltage";
CM_ SG_ 988 OBC_EMI_IP_OV "IPC Communication Error";
CM_ SG_ 988 OBC_EEPROM_FAIL "EEPROM Fail";
CM_ SG_ 988 OBC_CAN_BUS_OFF "OBC CAN BUS OFF";
CM_ SG_ 988 OBC_TEMP_DERATE "Temperature Derate";
CM_ SG_ 988 OBC_PRE_CHARGE_FAULT "Precharge Fault";
CM_ SG_ 988 OBC_PFV_OV "PFC Over Voltage";
CM_ SG_ 988 OBC_PFC_UV "PFC Under Voltage";
CM_ SG_ 988 OBC_PFC_OVER_TEMP "PFC Over Temperature";
CM_ SG_ 988 OBC_OP_UV "output Undervoltage";
CM_ SG_ 988 OBC_OP_OV "output Overvoltage";
CM_ SG_ 988 OBC_OP_OC "Output Overcurrent";
CM_ SG_ 988 OBC_LV_UNDER_VOLT "LV Under Voltage";
CM_ SG_ 988 OBC_LV_OVER_VOLT "LV Over Voltage";
CM_ SG_ 988 OBC_LLC_OVER_TEMP "LLC Over Temperature";
CM_ SG_ 988 OBC_IP_UNDER_VOLT "IP Under Voltage";
CM_ SG_ 988 OBC_IP_OVER_VOLT "IP Over Voltage";
CM_ SG_ 988 OBC_IP_OVER_CURR "IP Over Current";
CM_ SG_ 988 OBC_IP_DERATE "Input Derate";
CM_ SG_ 1480 OBC_COMFLT_SGN_CONTFAIL "Signal Content Failure";
CM_ SG_ 1480 OBC_UV_STS "NM Undervoltage STS";
CM_ SG_ 1480 OBC_STS_IGN_NM "Status of IGN";
CM_ SG_ 1480 OBC_OV_STS "NM Overvoltage STS";
CM_ SG_ 1480 OBC_AUX_BATT_VOLT "Aux Battery Voltage";
CM_ SG_ 1480 OBC_SW_VERSION "OBC Software Version";
CM_ SG_ 1480 OBC_COMFLT_MSG_CONTFAIL "Message Content Failure";
CM_ SG_ 1480 OBC_COMFLT_NODEABS_STS "Node Absent";
CM_ SG_ 1480 OBC_NM_ACTIVE_STS "NM Status";
CM_ SG_ 1480 OBC_VARIANT_CODE_ERR_STS "Variant Code DTC Status";
CM_ SG_ 1480 OBC_FEATURE_CODE_ERR_STS "Feature Code DTC Status";
CM_ SG_ 1480 OBC_COMFLT_MSGTOUT_STS "Key Message Timeout";
CM_ BO_ 983 "MCU Normal Signals 04";
CM_ SG_ 983 MCU_TPI "Thermal performance indicator for MCU.
TPI=2 -> No derating
TPI>=1 & TPI <2 -> derating warning 
TPI < 1 -> derating in progress";
CM_ SG_ 983 MCU_MotorCoolingFlowReq "Flow Request from motor.";
CM_ SG_ 983 MCU_Motor_Temp_Indicator "Temperature from different points of motor 
(coil etc) will be converted that to percentage format";
CM_ SG_ 983 MCU_Inverter_Temp_Indicator "MCU Thermal Indicator Inverter.";
CM_ SG_ 983 MCU_Inverter_CoolingFlowReq "Pump Flow request from MCU based on MCU cooling requirements";
CM_ BO_ 280 "MCU Critical Signals 02";
CM_ SG_ 280 MCU118_COUNTER "Message Counter";
CM_ SG_ 280 MCU118_Checksum "Checksum";
CM_ SG_ 280 MCU_MotorSpeed "MCU Motor Speed in RPM";
CM_ SG_ 280 MCU_MotorTorqueEstimated "Motorization estimated electric torque at the motor output shaft with higher resolution
";
CM_ SG_ 1016 BMS_HTR_CLT_SoftwareVersion_Num "Software Version of the CLT Heater
";
CM_ SG_ 1016 BMS_HTR_CLT_Fault_PCBTempSen "PCB Temperature Sensor Failure
";
CM_ SG_ 1016 BMS_HTR_CLT_Fault_PCBTempOver "PCB Over Temperature Protection - Condition : PCB Temperature = 90?(TBD) ( Rlease : PCB Temperature = 85?(TBD))
";
CM_ SG_ 1016 BMS_HTR_CLT_Fault_OutletTempSen "Outlet Temperature Sensor Failure
";
CM_ SG_ 1016 BMS_HTR_CLT_Fault_OutletTempOver "Outlet Over Temperature Protection - Condition : Outlet Temperature = 70?(TBD) ( Rlease : Outlet Temperature = 45?(TBD)) - The reason why the outlet temp warning is 70 ? is that the outlet temp target is 60 ? at the maximum.
";
CM_ SG_ 1016 BMS_HTR_CLT_Fault_LVSen "LV Sensor Failure
";
CM_ SG_ 1016 BMS_HTR_CLT_Fault_LostCtrlMsg "Receiving 'ECU_CLT_Ctrl_Msg' frame (ID 0x22) delayed over 4 sec(TBD)
";
CM_ SG_ 1016 BMS_HTR_CLT_Fault_IGBTShort "IGBT Short Failure (Short Load)
";
CM_ SG_ 1016 BMS_HTR_CLT_Fault_IGBTOpen "IGBT Open Failure ( Open Load)
";
CM_ SG_ 1016 BMS_HTR_CLT_Fault_IGBTDriverIC "Detected fault signal from the IGBT Driver
";
CM_ SG_ 1016 BMS_HTR_CLT_Fault_HVSen "HV Sensor Failure
";
CM_ SG_ 1016 BMS_HTR_CLT_Fault_HVOver "HV Over Voltage Protection - Condition : HV = 460V( Release : HV = 450V)
";
CM_ SG_ 1016 BMS_HTR_CLT_Fault_HVCurSen "HV Current Sensor Failure
";
CM_ SG_ 1016 BMS_HTR_CLT_LIN_Com_Err_Flag "Checksum, PID, DATA .Framing errs on LIN(Sticky flag)
";
CM_ SG_ 1016 BMS_HTR_CLT_Fault_LVUnder "LV Under Voltage Protection - Condition : LV = 8V ( Release : LV = 9V)
";
CM_ SG_ 1016 BMS_HTR_CLT_Fault_LVOver "LV Over Voltage Protection - Condition : LV = 17V( Release : LV = 16V)
";
CM_ SG_ 1016 BMS_HTR_CLT_Fault_HVUnder "HV Under Voltage Protection - Condition : HV = 90V ( Release : HV = 100V)
";
CM_ SG_ 1016 BMS_HTR_CLT_Fault_HVOverCur "HV Over Current Protection - Condition : HV Current = 40A (heater stops heating and retries operation again after 30
";
CM_ SG_ 1016 BMS_HTR_CLT_Fault_Flag "Heater has a fault or failure code(Sum of bit#8 ~ bit#31)
";
CM_ BO_ 993 "VCU EVCAN Active Frame";
CM_ SG_ 993 VCU_ACTIVE_RESERVED_EV "VCU EVCAN Active Reserved";
CM_ BO_ 824 "VCU Critical Signals 03";
CM_ SG_ 824 VCU338_COUNTER "Message Counter";
CM_ SG_ 824 VCU_CmdACChargeTargetVolt "Charging Target Voltage (from VCU Request to OBC / Charging Stand)";
CM_ SG_ 824 VCU338_CRC "CRC, CHECKSUM ERROR as per SAEJ1850";
CM_ SG_ 824 VCU_CmdEnableOBC "VCU sends Enable signal to OBC to start power delivery";
CM_ SG_ 824 VCU_CmdACChargeTargetCurrent "Charging Target Current (from VCU Request to OBC / Charging Stand)";
CM_ SG_ 824 VCU_ACChargingReady "This message provides VCU status for charging.";
CM_ SG_ 1736 VCU_EConsDistSample4 "Energy consumption for sample distance 4";
CM_ SG_ 1736 VCU_EConsDistSample3 "Energy consumption for sample distance 3";
CM_ SG_ 1736 VCU_EConsDistSample2 "Energy consumption for sample distance 2";
CM_ SG_ 1736 VCU_EConsDistSample1 "Energy consumption for sample distance 1";
CM_ SG_ 1012 VCU_DcChargingSequence "DC Charging Sequence Status";
CM_ SG_ 1012 VCU_SBWS_BuFb_RawVal "SBWS back up feedback(PWM) raw value";
CM_ SG_ 1012 VCU_SBWS_Bu_RawVal "SBWS back up(PWM) raw value";
CM_ SG_ 1012 VCU_PumpRlyCtrlSts "Cooling Pump relay control status";
CM_ SG_ 1012 VCU_MAX_CPU_Load "Internal test signal for maximum CPU load";
CM_ SG_ 1012 VCU_AVG_CPU_Load "Test signal for average CPU Load";
CM_ SG_ 1006 VCU_QkCharPosRlyFblSts "VCU Qick Charging Positive Relay Feedback Status";
CM_ SG_ 1006 VCU_QkCharPosRlyCtrlSts "VCU Qick Charging Positive Relay Control Status";
CM_ SG_ 1006 VCU_QkCharNegRlyFblSts "VCU Qick Charging Negative Relay Feedback Status";
CM_ SG_ 1006 VCU_QkCharNegRlyCtrlSts "VCU Qick Charging Negative Relay Control Status";
CM_ SG_ 1006 VCU_CharIndRedCtrlSts "Charging Indicaiton Lamp(Red Led) Control Status(PWM)";
CM_ SG_ 1006 VCU_CharIndGrCtrlSts "Charging Indicaiton Lamp(Green Led) Control Status(PWM)";
CM_ SG_ 1006 VCU_CharIndBlCtrlSts "Charging Indicaiton Lamp(Blue Led) Control Status(PWM)";
CM_ BO_ 984 "OBC Normal Signals 02";
CM_ SG_ 984 OBC_PFC_Voltage "OBC PFC Voltage";
CM_ SG_ 984 OBC_DCVoltageCapable "OBC Voltage capability";
CM_ SG_ 984 OBC_DCCurrentCapable "OBC DC Current capability";
CM_ BO_ 1064 "OBC Normal Signals 01";
CM_ SG_ 1064 OBC_PowerDeratingSta "OBV Power Derating Status";
CM_ SG_ 1064 OBC_OperatingMode "OBC System controller status information";
CM_ SG_ 1064 OBC_ACDetectSta "OBC Main (AC) Source Detection";
CM_ SG_ 986 OBC_Transformer_Temperature "OBC Temperature value";
CM_ SG_ 986 OBC_CoolingRequest "OBC Cooling Request signal";
CM_ SG_ 986 OBC_PrimarySide_Temperature "OBC temperature";
CM_ SG_ 986 OBC_LV_PwrSupply "LV power Supply";
CM_ SG_ 1479 MCU_SW_Version_Internal "MCU software version internal";
CM_ SG_ 1479 MCU_COMFLT_SGN_CONTFAIL "Signal Content Failure";
CM_ SG_ 1479 MCU_OV_STS "NM Overvoltage STS";
CM_ SG_ 1479 MCU_UV_STS "NM Undervoltage STS";
CM_ SG_ 1479 MCU_STS_IGN "Status of IGN";
CM_ SG_ 1479 MCU_AUX_BATT_VOLT "Aux Battery Voltage";
CM_ SG_ 1479 MCU_SW_VERSION "MCU Software Version";
CM_ SG_ 1479 MCU_COMFLT_MSG_CONTFAIL "Message Content Failure";
CM_ SG_ 1479 MCU_NM_ACTIVE_STS "MCU NM Status";
CM_ SG_ 1479 MCU_COMFLT_NODEABS_STS "NODE ABSENT Status";
CM_ SG_ 1479 MCU_COMFLT_MSGTOUT_STS "Key Message Timeout";
CM_ SG_ 283 MCU11B_Checksum "Checksum";
CM_ SG_ 283 MCU11B_COUNTER "Message Counter";
CM_ SG_ 283 MCU_ErrorLevel "MCU Error Levels";
CM_ SG_ 283 MCU_ActiveDamping "Active Damping ";
CM_ SG_ 283 MCU_OperationalMode "Operation mode of MCU";
CM_ SG_ 283 MCU_CommandMode "Input command mode of MCU";
CM_ SG_ 283 MCU_State "MCU state";
CM_ SG_ 283 MCU_ACTV_Discharge_STS "HV Active Discharging Status";
CM_ SG_ 283 MCU_ACTV_Discharge_FAIL "HV Active Discharging Failure Status";
CM_ BO_ 982 "MCU Critical Signals 01";
CM_ SG_ 982 MCU_HighPowerCurrent "Motor High Power current";
CM_ SG_ 982 MCU_HighPowerVoltage "Motor High Power Voltage";
CM_ SG_ 982 MCU_TractionTorqueAvail_quasi "Available quasistatic traction torque";
CM_ SG_ 982 MCU_RegenTorqueAvail_quasi "Available quasistatic regen torque";
CM_ SG_ 1478 LDC_COMFLT_SGN_CONTFAIL "Signal Content Failure";
CM_ SG_ 1478 LDC_UV_STS "NM Undervoltage STS";
CM_ SG_ 1478 LDC_OV_STS "NM Overrvoltage STS";
CM_ SG_ 1478 LDC_STS_IGN_NM "Status of IGN";
CM_ SG_ 1478 LDC_AUX_BATT_VOLT "Aux Battery Voltage";
CM_ SG_ 1478 LDC_SW_VERSION "LDC Software Version";
CM_ SG_ 1478 LDC_COMFLT_MSG_CONTFAIL "Message Content Failure";
CM_ SG_ 1478 LDC_COMFLT_NODEABS_STS "Node Abssent";
CM_ SG_ 1478 LDC_VARIANT_CODE_ERR_STS "Variant Code DTC Status";
CM_ SG_ 1478 LDC_NM_ACTIVE_STS "NM Status";
CM_ SG_ 1478 LDC_FEATURE_CODE_ERR_STS "Feature Code DTC Status";
CM_ SG_ 1478 LDC_COMFLT_MSGTOUT_STS "Key Message Timeout";
CM_ SG_ 1477 ETL_COMFLT_SGN_CONTFAIL "Signal Content Failure";
CM_ SG_ 1477 ETL_OV_STS "NM Overrvoltage STS";
CM_ SG_ 1477 ETL_UV_STS "NM Undervoltage STS";
CM_ SG_ 1477 ETL_STS_IGN "Status of IGN";
CM_ SG_ 1477 ETL_AUX_BATT_VOLT "Aux Battery Voltage";
CM_ SG_ 1477 ETL_SW_VERSION "ETL Software Version";
CM_ SG_ 1477 ETL_COMFLT_MSG_CONTFAIL "Message Content Failure";
CM_ SG_ 1477 ETL_COMFLT_NODEABS_STS "Node Absent";
CM_ SG_ 1477 ETL_COMFLT_MSGTOUT_STS "Key Message Timeout";
CM_ BO_ 578 "ETL Critical Signals 01";
CM_ SG_ 578 ETL_Shifting_In_Progress "Shifting in Progress";
CM_ SG_ 578 ETL_Service_WRN_IND "Service warning";
CM_ SG_ 578 ETL_Pmotor_Position_Failure "Parking Motor Position Failure Status";
CM_ SG_ 578 ETL242_COUNTER "Message Counter";
CM_ SG_ 578 ETL242_CRC "CRC, CHECKSUM ERROR as per SAEJ1850";
CM_ SG_ 578 ETL_PmotorPositionStatus "Parking Motor Position Status";
CM_ SG_ 578 ETL_PmotorErrorLevel "EGP internal state error ";
CM_ SG_ 578 ETL_OperationMode "EGP operation Mode";
CM_ SG_ 1475 BMS_STS_IGN_NM "Status of IGN NM";
CM_ SG_ 1475 BMS_COMFLT_SGN_CONTFAIL "Signal  Content Failure";
CM_ SG_ 1475 BMS_UV_STS "NM Undervoltage STS";
CM_ SG_ 1475 BMS_OV_STS "NM Overvoltage STS";
CM_ SG_ 1475 BMS_AUX_BATT_VOLT "Aux Battery Voltage";
CM_ SG_ 1475 BMS_SW_VERSION "BMS Software Version";
CM_ SG_ 1475 BMS_COMFLT_MSG_CONTFAIL "Message Content Failure";
CM_ SG_ 1475 BMS_COMFLT_NODEABS_STS "Node Absent";
CM_ SG_ 1475 BMS_VARIANT_CODE_ERR_STS "BMS Variant Code DTC Status";
CM_ SG_ 1475 BMS_NM_ACTIVE_STS "NM Status";
CM_ SG_ 1475 BMS_FEATURE_CODE_ERR_STS "Feature Code DTC Status";
CM_ SG_ 1475 BMS_COMFLT_MSGTOUT_STS "Key Message Timeout";
CM_ SG_ 1002 BMS_Regen_AH "REGEN AMPERE HOUR";
CM_ SG_ 1002 BMS_KiloWattHour "BMS KILOWATTHOUR";
CM_ SG_ 1002 BMS_AmpereHour "BMS Ampere Hour";
CM_ BO_ 980 "BMS Normal Signals 05";
CM_ SG_ 980 BMS_Batt_Overcurrent_Sta "Battery Overcurrent Status";
CM_ SG_ 980 BMS_DischargePowerAvailable_2 "Battery Discharge power avaible for next 2sec";
CM_ SG_ 980 BMS_DischargePowerAvailable_10 "Battery available Discharge power  for next 10sec";
CM_ SG_ 980 BMS_BatteryPackSOE "Battery Remaning Capacity";
CM_ BO_ 978 "BMS Normal Signals 09";
CM_ SG_ 978 BMS_BHeaterFlt "Battery Heater fault information";
CM_ SG_ 978 BMS_BHeaterOpCoolantTemp "Battery Heater Output Coolant temperature";
CM_ SG_ 978 BMS_CoolingHeatingSta "setting the cooling/Heating request to On or OFF completely";
CM_ SG_ 978 BMS_ChillerSoleniodSta "Status of Chiller Soleniod";
CM_ SG_ 978 BMS_BatteryPreconditioningSta "HV Battery Preconditioning status";
CM_ SG_ 978 BMS_BatteryOutletCoolantTemp "HV Battery Outlet Coolant  temperature  information";
CM_ SG_ 978 BMS_BatteryInletCoolantTempReq "Coolant inlet temperature request";
CM_ SG_ 978 BMS_BatteryInletCoolantTemp "HV Battery Inlet Coolant temperature";
CM_ BO_ 626 "BMS Critical Signals 02";
CM_ SG_ 626 BMS_BatteryTBatt "Estimated Battery Temperature";
CM_ SG_ 626 BMS_BatteryPackVoltage "Battery Pack Voltage";
CM_ SG_ 626 BMS_DisconnectByBMS "Disconnect by BMS";
CM_ SG_ 626 BMS_BatteryHVILSta "Battery HVIL status'";
CM_ SG_ 626 BMS_ModuleActiveDischarge "Module Active Discharge Request";
CM_ SG_ 626 BMS272_COUNTER "Message Counter";
CM_ SG_ 626 BMS272_CRC "CRC, CHECKSUM ERROR as per SAEJ1850";
CM_ SG_ 626 BMS_BContactorOffRequest "Request VCU  to open contactor from BMS";
CM_ SG_ 626 BMS_HVILSta "High voltage interlock loop status (MCU, PDU, OBC & Battery pack)";
CM_ SG_ 626 BMS_PilotlineSta "PilotLine Status";
CM_ SG_ 626 BMS_IsolationFlt "Isolation faults status";
CM_ SG_ 626 BMS_CrashPyroFuseResponse "Pyro Fuse ststus over CAN";
CM_ BO_ 337 "BMS Normal Signals 06";
CM_ SG_ 337 BMS151_CRC "CRC, CHECKSUM ERROR as per SAEJ1850";
CM_ SG_ 337 BMS151_COUNTER "Message Counter";
CM_ SG_ 337 BMS_BMainMinusContactorState "Battery Main Minus Contactor State";
CM_ SG_ 337 BMS_PreChargeContactorSta "HV Battery Precharge relay ON/OFF status";
CM_ SG_ 337 BMS_BMainPlusContactorState "Battery Main Plus Contactor State";
CM_ SG_ 337 BMS_Current2sensorReading "HES Current Sensor Reading";
CM_ SG_ 337 BMS_Current1sensorReading "IVT Current sensor readings";
CM_ BO_ 999 "BMS Normal Signals 03";
CM_ SG_ 999 BMS_BatteryMaxCellVoltage "Battery Max Cell Voltage";
CM_ SG_ 999 BMS_BatteryMinCellVoltage "Battery Min Cell Voltage";
CM_ SG_ 999 BMS_BatteryDisconnectSta "HV Battery Disconnect status (after request from VCU)";
CM_ SG_ 999 BMS_BatteryConnectSta "HV Battery connect status (after request from VCU)";
CM_ SG_ 999 BMS_BatteryAvgCellVoltage "Battery Average Cell Voltage";
CM_ BO_ 1000 "BMS Normal Signals 02";
CM_ SG_ 1000 BMS_BatteryPackSOH "HV Battery SOH";
CM_ SG_ 1000 BMS_BatteryPackRSOC "Battery Pack RSOC (Relative)  -> Display on cluster (0~100%)";
CM_ SG_ 1000 BMS_BatteryPackASOC "Battery Pack ASOC (Absolute)";
CM_ SG_ 2013 DIAG_TGU_RES_DATA "Keyword 2000 Diagnostic Message Response Data";
CM_ BO_ 1652 "Telematics";
CM_ SG_ 1652 VEH_SEARCH_REQ "TGU commands to Search Vehicle";
CM_ SG_ 1652 CHARGING_ON_OFF_REQ "CHARGING ENABLE DISABLE REQUEST";
CM_ SG_ 1652 TGU_REVIVE_REQ "REVIVE REQUEST";
CM_ SG_ 1652 REMOTE_DOOR_LOCK_UNLOCK "DOOR REMOTE LOCK/UNLOCK";
CM_ SG_ 374 TGS_MODE_AMT "Mode Switch State";
CM_ SG_ 264 ALTERNATOR_CUTOFF_REQ "S201 Cluster controls Alternator cutoff, during vehicle launch EMS would request cluster for ALT cutoff.
SIgnal implementation required only for S201 DCM71.";
CM_ SG_ 264 CLUTCH_STS "'Clutch press states";
CM_ BO_ 1980 "OBCLDC Diagnostic Response";
CM_ SG_ 1980 DIAG_LDC_RES_DATA "Diagnostic Res from LDC to Tool";
CM_ SG_ 2008 DIAG_MCU_RES_DATA "MCU Diagnostic Response";
CM_ BO_ 579 "VCU EVCAN Wakeup Frame.It would be sent spontaneously after every 20ms for 60ms (3 times)";
CM_ SG_ 579 VCU_EVCAN_WAKEUPREASONRESERVED2 "VCU EV CAN Wakeup Reason";
CM_ SG_ 579 VCU_EVCAN_WAKEUPREASONRESERVED1 "VCU EV CAN Wakeup Reason";
CM_ SG_ 579 VCU_EVCAN_WAKEUPREASON "VCU EV CAN Wakeup Reason";
BA_DEF_  "BusType" STRING ;
BA_DEF_  "DBName" STRING ;
BA_DEF_ EV_  "GenEnvControlType" ENUM  "NoControl","SliderHoriz","SliderVert","PushButton","Edit","BitmapSwitch";
BA_DEF_ SG_  "SignalType" STRING ;
BA_DEF_ SG_  "SignalCategory" HEX 10 15;
BA_DEF_ SG_  "GenSigTimeoutTime_IS" INT 0 65535;
BA_DEF_ SG_  "CmxSigDefaultRaw" HEX 0 2147483647;
BA_DEF_ SG_  "GwSigLatencyTime" INT 0 65535;
BA_DEF_ SG_  "GwSigMissingSourceType" ENUM  "Undef","OldValue","DefaultValue","InitialValue";
BA_DEF_ SG_  "GenSigEnvVarType" ENUM  "int","float","undef";
BA_DEF_ SG_  "GenSigEVName" STRING ;
BA_DEF_ SG_  "GenSigStartValue" INT 0 0;
BA_DEF_ SG_  "GenSigSendType" ENUM  "Cyclic","OnWrite","OnWriteWithRepetition","OnChange","OnChangeWithRepetition","IfActive","IfActiveWithRepetition","NoSigSendType";
BA_DEF_ SG_  "GenSigInactiveValue" INT 0 0;
BA_DEF_ SG_  "SigCreator" STRING ;
BA_DEF_ BO_  "NWM-Botschaft" ENUM  "nein","ja";
BA_DEF_ BO_  "GenMsgNrOfRepetitions" INT 1 999999;
BA_DEF_ BO_  "MsgCreator" STRING ;
BA_DEF_ BO_  "GenMsgTimeOut" INT 0 0;
BA_DEF_ BO_  "DiagState" ENUM  "No","Yes";
BA_DEF_ BO_  "DiagRequest" ENUM  "No","Yes";
BA_DEF_ BO_  "DiagResponse" ENUM  "No","Yes";
BA_DEF_ BO_  "TpTxIndex" INT 0 255;
BA_DEF_ BO_  "GenMsgILSupport" ENUM  "No","Yes";
BA_DEF_ BO_  "GenMsgNrOfRepetition" INT 0 3;
BA_DEF_ BO_  "GenMsgDelayTime" INT 0 0;
BA_DEF_ BO_  "GenMsgCycleTimeFast" INT 0 500;
BA_DEF_ BO_  "GenMsgStartDelayTime" INT 0 140;
BA_DEF_ BO_  "GenMsgSendType" ENUM  "Cyclic","Spontaneous","not_used","not_used","not_used","Cyclic","not_used","IfActive","NoMsgSendType";
BA_DEF_ BO_  "GenMsgCycleTime" INT 0 0;
BA_DEF_ BU_  "NWM-Knoten" ENUM  "nein","ja";
BA_DEF_ BU_  "NodeLayerModules" STRING ;
BA_DEF_ BU_  "GenNodSleepTime" INT 1375 1650;
BA_DEF_ BU_  "NmNode" ENUM  "No","Yes";
BA_DEF_ BU_  "NmCAN" INT 1 2;
BA_DEF_ BU_  "ILUsed" ENUM  "No","Yes";
BA_DEF_REL_ BU_SG_REL_  "GenSigTimeoutTime" INT 30 3500;
BA_DEF_DEF_  "BusType" "";
BA_DEF_DEF_  "DBName" "";
BA_DEF_DEF_  "GenEnvControlType" "NoControl";
BA_DEF_DEF_  "SignalType" "";
BA_DEF_DEF_  "SignalCategory" 10;
BA_DEF_DEF_  "GenSigTimeoutTime_IS" 0;
BA_DEF_DEF_  "CmxSigDefaultRaw" 0;
BA_DEF_DEF_  "GwSigLatencyTime" 40;
BA_DEF_DEF_  "GwSigMissingSourceType" "Undef";
BA_DEF_DEF_  "GenSigEnvVarType" "undef";
BA_DEF_DEF_  "GenSigEVName" "";
BA_DEF_DEF_  "GenSigStartValue" 0;
BA_DEF_DEF_  "GenSigSendType" "Cyclic";
BA_DEF_DEF_  "GenSigInactiveValue" 0;
BA_DEF_DEF_  "SigCreator" "M&M-IVN";
BA_DEF_DEF_  "NWM-Botschaft" "nein";
BA_DEF_DEF_  "GenMsgNrOfRepetitions" 1;
BA_DEF_DEF_  "MsgCreator" "M&M-IVN";
BA_DEF_DEF_  "GenMsgTimeOut" 0;
BA_DEF_DEF_  "DiagState" "No";
BA_DEF_DEF_  "DiagRequest" "No";
BA_DEF_DEF_  "DiagResponse" "No";
BA_DEF_DEF_  "TpTxIndex" 0;
BA_DEF_DEF_  "GenMsgILSupport" "Yes";
BA_DEF_DEF_  "GenMsgNrOfRepetition" 0;
BA_DEF_DEF_  "GenMsgDelayTime" 0;
BA_DEF_DEF_  "GenMsgCycleTimeFast" 0;
BA_DEF_DEF_  "GenMsgStartDelayTime" 0;
BA_DEF_DEF_  "GenMsgSendType" "Cyclic";
BA_DEF_DEF_  "GenMsgCycleTime" 0;
BA_DEF_DEF_  "NWM-Knoten" "nein";
BA_DEF_DEF_  "NodeLayerModules" "dmoseknm.dll,CANoeILNLVector.dll";
BA_DEF_DEF_  "GenNodSleepTime" 1500;
BA_DEF_DEF_  "NmNode" "Yes";
BA_DEF_DEF_  "NmCAN" 1;
BA_DEF_DEF_  "ILUsed" "Yes";
BA_DEF_DEF_REL_ "GenSigTimeoutTime" 1400;
BA_ "BusType" "CAN";
BA_ "DBName" "SMART_CORE";
BA_ "NodeLayerModules" BU_ SMART_CORE "CANoeILNLVector.dll";
BA_ "GenMsgCycleTime" BO_ 445 10;
BA_ "GenMsgCycleTime" BO_ 1007 100;
BA_ "GenMsgCycleTime" BO_ 823 20;
BA_ "GenMsgCycleTime" BO_ 443 10;
BA_ "GenMsgCycleTime" BO_ 628 30;
BA_ "GenMsgCycleTime" BO_ 991 100;
BA_ "GenMsgCycleTime" BO_ 580 30;
BA_ "GenMsgCycleTime" BO_ 989 100;
BA_ "GenMsgCycleTime" BO_ 825 100;
BA_ "GenMsgCycleTime" BO_ 352 50;
BA_ "GenMsgCycleTime" BO_ 345 50;
BA_ "GenMsgCycleTime" BO_ 344 50;
BA_ "GenMsgCycleTime" BO_ 979 10;
BA_ "GenMsgCycleTime" BO_ 1005 100;
BA_ "GenMsgTimeOut" BO_ 301 10;
BA_ "GenMsgCycleTime" BO_ 301 10;
BA_ "GenMsgCycleTime" BO_ 1003 100;
BA_ "GenMsgCycleTime" BO_ 981 100;
BA_ "GenMsgILSupport" BO_ 1949 0;
BA_ "GenMsgDelayTime" BO_ 1949 20;
BA_ "GenMsgSendType" BO_ 1949 1;
BA_ "GenMsgILSupport" BO_ 1941 0;
BA_ "GenMsgDelayTime" BO_ 1941 20;
BA_ "GenMsgSendType" BO_ 1941 1;
BA_ "GenMsgCycleTime" BO_ 779 100;
BA_ "DiagResponse" BO_ 1852 1;
BA_ "GenMsgSendType" BO_ 1852 1;
BA_ "DiagResponse" BO_ 1866 1;
BA_ "GenMsgSendType" BO_ 1866 1;
BA_ "GenMsgCycleTime" BO_ 1585 1000;
BA_ "GenMsgTimeOut" BO_ 1170 2000;
BA_ "GenMsgCycleTime" BO_ 1170 200;
BA_ "DiagResponse" BO_ 1994 1;
BA_ "GenMsgSendType" BO_ 1994 1;
BA_ "GenMsgTimeOut" BO_ 1169 2000;
BA_ "GenMsgCycleTime" BO_ 1169 200;
BA_ "DiagRequest" BO_ 1988 1;
BA_ "GenMsgSendType" BO_ 1988 1;
BA_ "DiagRequest" BO_ 2006 1;
BA_ "GenMsgSendType" BO_ 2006 1;
BA_ "DiagRequest" BO_ 2019 1;
BA_ "GenMsgILSupport" BO_ 2019 0;
BA_ "GenMsgDelayTime" BO_ 2019 5;
BA_ "GenMsgSendType" BO_ 2019 1;
BA_ "GenMsgCycleTime" BO_ 870 100;
BA_ "GenMsgCycleTime" BO_ 1654 1000;
BA_ "DiagRequest" BO_ 1958 1;
BA_ "GenMsgSendType" BO_ 1958 1;
BA_ "DiagRequest" BO_ 1959 1;
BA_ "GenMsgSendType" BO_ 1959 1;
BA_ "DiagRequest" BO_ 1842 1;
BA_ "GenMsgSendType" BO_ 1842 1;
BA_ "DiagRequest" BO_ 1986 1;
BA_ "GenMsgILSupport" BO_ 1986 0;
BA_ "GenMsgDelayTime" BO_ 1986 5;
BA_ "GenMsgSendType" BO_ 1986 1;
BA_ "DiagRequest" BO_ 1858 1;
BA_ "GenMsgSendType" BO_ 1858 1;
BA_ "DiagRequest" BO_ 1859 1;
BA_ "GenMsgSendType" BO_ 1859 1;
BA_ "GenMsgCycleTime" BO_ 1248 200;
BA_ "DiagRequest" BO_ 2017 1;
BA_ "GenMsgSendType" BO_ 2017 1;
BA_ "GenMsgSendType" BO_ 1955 1;
BA_ "GenMsgCycleTime" BO_ 1280 500;
BA_ "GenMsgCycleTime" BO_ 154 20;
BA_ "GenMsgNrOfRepetition" BO_ 955 1;
BA_ "GenMsgSendType" BO_ 955 1;
BA_ "GenMsgCycleTime" BO_ 957 100;
BA_ "GenMsgSendType" BO_ 1587 1;
BA_ "DiagRequest" BO_ 1856 1;
BA_ "GenMsgILSupport" BO_ 1856 0;
BA_ "GenMsgDelayTime" BO_ 1856 5;
BA_ "GenMsgSendType" BO_ 1856 1;
BA_ "GenMsgCycleTime" BO_ 1144 100;
BA_ "DiagResponse" BO_ 1963 1;
BA_ "GenMsgSendType" BO_ 1963 1;
BA_ "GenMsgCycleTime" BO_ 956 100;
BA_ "GenMsgTimeOut" BO_ 786 2000;
BA_ "GenMsgCycleTime" BO_ 786 200;
BA_ "GenMsgTimeOut" BO_ 784 2000;
BA_ "GenMsgCycleTime" BO_ 784 200;
BA_ "GenMsgTimeOut" BO_ 563 1000;
BA_ "GenMsgCycleTime" BO_ 563 100;
BA_ "GenMsgTimeOut" BO_ 295 100;
BA_ "GenMsgCycleTime" BO_ 295 10;
BA_ "GenMsgCycleTime" BO_ 375 20;
BA_ "GenMsgTimeOut" BO_ 294 100;
BA_ "GenMsgCycleTime" BO_ 294 10;
BA_ "GenMsgTimeOut" BO_ 304 200;
BA_ "GenMsgCycleTime" BO_ 304 20;
BA_ "GenMsgCycleTime" BO_ 1638 1000;
BA_ "GenMsgTimeOut" BO_ 1079 1000;
BA_ "GenMsgCycleTime" BO_ 1079 500;
BA_ "GenMsgTimeOut" BO_ 1078 1000;
BA_ "GenMsgCycleTime" BO_ 1078 500;
BA_ "GenMsgCycleTime" BO_ 1406 200;
BA_ "GenMsgTimeOut" BO_ 1077 1000;
BA_ "GenMsgCycleTime" BO_ 1077 500;
BA_ "GenMsgCycleTime" BO_ 752 50;
BA_ "GenMsgCycleTime" BO_ 1584 100;
BA_ "GenMsgCycleTime" BO_ 1595 100;
BA_ "GenMsgCycleTime" BO_ 1596 100;
BA_ "GenMsgCycleTime" BO_ 1428 1000;
BA_ "GenMsgCycleTime" BO_ 661 100;
BA_ "GenMsgCycleTime" BO_ 922 10;
BA_ "DiagResponse" BO_ 1867 1;
BA_ "GenMsgSendType" BO_ 1867 1;
BA_ "GenMsgCycleTime" BO_ 1582 100;
BA_ "DiagResponse" BO_ 1965 1;
BA_ "GenMsgSendType" BO_ 1965 1;
BA_ "DiagResponse" BO_ 1967 1;
BA_ "GenMsgSendType" BO_ 1967 1;
BA_ "DiagResponse" BO_ 2014 1;
BA_ "GenMsgSendType" BO_ 2014 1;
BA_ "DiagResponse" BO_ 1996 1;
BA_ "GenMsgSendType" BO_ 1996 1;
BA_ "GenMsgCycleTime" BO_ 767 50;
BA_ "GenMsgCycleTime" BO_ 917 100;
BA_ "DiagResponse" BO_ 2027 1;
BA_ "GenMsgSendType" BO_ 2027 1;
BA_ "DiagResponse" BO_ 1966 1;
BA_ "GenMsgSendType" BO_ 1966 1;
BA_ "DiagResponse" BO_ 1850 1;
BA_ "GenMsgSendType" BO_ 1850 1;
BA_ "GenMsgCycleTime" BO_ 666 100;
BA_ "GenMsgCycleTime" BO_ 930 50;
BA_ "GenMsgCycleTime" BO_ 929 50;
BA_ "GenMsgCycleTime" BO_ 1653 1000;
BA_ "GenMsgCycleTime" BO_ 272 20;
BA_ "GenMsgCycleTime" BO_ 950 100;
BA_ "GenMsgNrOfRepetition" BO_ 962 1;
BA_ "GenMsgSendType" BO_ 962 1;
BA_ "GenMsgCycleTime" BO_ 158 20;
BA_ "GenMsgCycleTime" BO_ 949 100;
BA_ "GenMsgSendType" BO_ 2031 1;
BA_ "GenMsgCycleTime" BO_ 1594 100;
BA_ "GenMsgCycleTime" BO_ 1583 100;
BA_ "DiagResponse" BO_ 2025 1;
BA_ "GenMsgSendType" BO_ 2025 1;
BA_ "GenMsgCycleTime" BO_ 1581 100;
BA_ "GenMsgCycleTime" BO_ 1413 500;
BA_ "GenMsgSendType" BO_ 259 1;
BA_ "DiagResponse" BO_ 1864 1;
BA_ "GenMsgSendType" BO_ 1864 1;
BA_ "GenMsgCycleTime" BO_ 1786 20;
BA_ "GenMsgCycleTime" BO_ 1787 20;
BA_ "GenMsgCycleTime" BO_ 1784 20;
BA_ "GenMsgCycleTime" BO_ 1785 20;
BA_ "GenMsgSendType" BO_ 2023 1;
BA_ "DiagRequest" BO_ 1844 1;
BA_ "GenMsgSendType" BO_ 1844 1;
BA_ "DiagRequest" BO_ 1957 1;
BA_ "GenMsgSendType" BO_ 1957 1;
BA_ "GenMsgCycleTime" BO_ 581 30;
BA_ "GenMsgCycleTime" BO_ 274 10;
BA_ "GenMsgCycleTime" BO_ 819 100;
BA_ "GenMsgCycleTime" BO_ 821 100;
BA_ "GenMsgCycleTime" BO_ 577 20;
BA_ "GenMsgCycleTime" BO_ 822 100;
BA_ "GenMsgCycleTime" BO_ 437 10;
BA_ "GenMsgCycleTime" BO_ 601 20;
BA_ "GenMsgCycleTime" BO_ 1731 100;
BA_ "GenMsgCycleTime" BO_ 1481 500;
BA_ "GenMsgCycleTime" BO_ 988 100;
BA_ "GenMsgCycleTime" BO_ 1480 500;
BA_ "GenMsgCycleTime" BO_ 983 100;
BA_ "GenMsgCycleTime" BO_ 280 10;
BA_ "GenMsgCycleTime" BO_ 1016 200;
BA_ "DiagResponse" BO_ 1918 1;
BA_ "GenMsgSendType" BO_ 1918 1;
BA_ "DiagRequest" BO_ 1910 1;
BA_ "GenMsgSendType" BO_ 1910 1;
BA_ "GenMsgCycleTime" BO_ 1015 200;
BA_ "GenMsgCycleTime" BO_ 1014 200;
BA_ "GenMsgCycleTime" BO_ 993 100;
BA_ "GenMsgCycleTime" BO_ 824 100;
BA_ "GenMsgCycleTime" BO_ 1736 1000;
BA_ "GenMsgCycleTime" BO_ 1012 100;
BA_ "GenMsgCycleTime" BO_ 1006 100;
BA_ "GenMsgCycleTime" BO_ 984 100;
BA_ "GenMsgCycleTime" BO_ 1064 100;
BA_ "GenMsgCycleTime" BO_ 986 100;
BA_ "GenMsgCycleTime" BO_ 1479 500;
BA_ "GenMsgCycleTime" BO_ 283 10;
BA_ "GenMsgCycleTime" BO_ 982 100;
BA_ "GenMsgCycleTime" BO_ 1478 500;
BA_ "GenMsgCycleTime" BO_ 1477 500;
BA_ "GenMsgCycleTime" BO_ 578 20;
BA_ "GenMsgCycleTime" BO_ 1475 500;
BA_ "GenMsgCycleTime" BO_ 1002 100;
BA_ "GenMsgCycleTime" BO_ 980 100;
BA_ "GenMsgCycleTime" BO_ 978 100;
BA_ "GenMsgTimeOut" BO_ 626 10;
BA_ "GenMsgCycleTime" BO_ 626 30;
BA_ "GenMsgCycleTime" BO_ 337 50;
BA_ "GenMsgCycleTime" BO_ 1720 10;
BA_ "GenMsgCycleTime" BO_ 1655 500;
BA_ "GenMsgCycleTime" BO_ 339 100;
BA_ "GenMsgCycleTime" BO_ 338 100;
BA_ "GenMsgCycleTime" BO_ 1761 100;
BA_ "GenMsgCycleTime" BO_ 999 100;
BA_ "GenMsgCycleTime" BO_ 1000 100;
BA_ "GenMsgSendType" BO_ 2005 1;
BA_ "GenMsgSendType" BO_ 2013 1;
BA_ "GenMsgTimeOut" BO_ 1652 2500;
BA_ "GenMsgCycleTime" BO_ 1652 500;
BA_ "GenMsgCycleTime" BO_ 374 20;
BA_ "GenMsgTimeOut" BO_ 264 100;
BA_ "GenMsgCycleTime" BO_ 264 10;
BA_ "DiagResponse" BO_ 1919 1;
BA_ "GenMsgSendType" BO_ 1919 1;
BA_ "DiagRequest" BO_ 1911 1;
BA_ "GenMsgSendType" BO_ 1911 1;
BA_ "DiagState" BO_ 1980 1;
BA_ "GenMsgSendType" BO_ 1980 1;
BA_ "GenMsgSendType" BO_ 2008 1;
BA_ "GenMsgCycleTime" BO_ 579 20;
BA_ "GenSigStartValue" SG_ 1007 VCU_TorqueCoasting 48;
BA_ "GenSigStartValue" SG_ 989 LDC_Primary_Temperature 550;
BA_ "GenSigStartValue" SG_ 989 LDC_MOSFET_Temperature 550;
BA_ "GenSigStartValue" SG_ 989 LDC_Secondary_Temperature 550;
BA_ "GenSigStartValue" SG_ 825 BMS_BatteryMinTemperature 680;
BA_ "GenSigStartValue" SG_ 825 BMS_BatteryMaxTemperature 680;
BA_ "GenSigStartValue" SG_ 1005 BMS_BatteryAvgTemperature 680;
BA_ "GenSigStartValue" SG_ 301 BMS_BatteryBusVoltage 3650;
BA_ "GenSigStartValue" SG_ 301 BMS_BatteryPackCurrent 6000;
BA_ "GenSigStartValue" SG_ 1003 BMS_CellTemp9 500;
BA_ "GenSigStartValue" SG_ 1003 BMS_CellTemp8 500;
BA_ "GenSigStartValue" SG_ 1003 BMS_CellTemp7 500;
BA_ "GenSigStartValue" SG_ 1003 BMS_CellTemp6 500;
BA_ "GenSigStartValue" SG_ 1003 BMS_CellTemp5 500;
BA_ "GenSigStartValue" SG_ 1003 BMS_CellTemp4 500;
BA_ "GenSigStartValue" SG_ 1003 BMS_CellTemp32 500;
BA_ "GenSigStartValue" SG_ 1003 BMS_CellTemp31 500;
BA_ "GenSigStartValue" SG_ 1003 BMS_CellTemp30 500;
BA_ "GenSigStartValue" SG_ 1003 BMS_CellTemp29 500;
BA_ "GenSigStartValue" SG_ 1003 BMS_CellTemp28 500;
BA_ "GenSigStartValue" SG_ 1003 BMS_CellTemp27 500;
BA_ "GenSigStartValue" SG_ 1003 BMS_CellTemp26 500;
BA_ "GenSigStartValue" SG_ 1003 BMS_CellTemp25 500;
BA_ "GenSigStartValue" SG_ 1003 BMS_CellTemp24 500;
BA_ "GenSigStartValue" SG_ 1003 BMS_CellTemp23 500;
BA_ "GenSigStartValue" SG_ 1003 BMS_CellTemp22 500;
BA_ "GenSigStartValue" SG_ 1003 BMS_CellTemp21 500;
BA_ "GenSigStartValue" SG_ 1003 BMS_CellTemp20 500;
BA_ "GenSigStartValue" SG_ 1003 BMS_CellTemp19 500;
BA_ "GenSigStartValue" SG_ 1003 BMS_CellTemp18 500;
BA_ "GenSigStartValue" SG_ 1003 BMS_CellTemp17 500;
BA_ "GenSigStartValue" SG_ 1003 BMS_CellTemp16 500;
BA_ "GenSigStartValue" SG_ 1003 BMS_CellTemp15 500;
BA_ "GenSigStartValue" SG_ 1003 BMS_CellTemp14 500;
BA_ "GenSigStartValue" SG_ 1003 BMS_CellTemp13 500;
BA_ "GenSigStartValue" SG_ 1003 BMS_CellTemp12 500;
BA_ "GenSigStartValue" SG_ 1003 BMS_CellTemp11 500;
BA_ "GenSigStartValue" SG_ 1003 BMS_CellTemp10 500;
BA_ "GenSigStartValue" SG_ 1003 BMS_CellTemp3 500;
BA_ "GenSigStartValue" SG_ 1003 BMS_CellTemp2 500;
BA_ "GenSigStartValue" SG_ 1003 BMS_CellTemp1 500;
BA_ "GenSigSendType" SG_ 1949 DIAG_SBRM_RES_DATA 7;
BA_ "GenSigSendType" SG_ 1941 DIAG_SBRM_REQ_DATA 7;
BA_ "GenSigStartValue" SG_ 1170 IBS_BATT_TEMP_MBFM 80;
BA_ "GenSigStartValue" SG_ 1170 IBS_CURRENT_MBFM 1250;
BA_ "GenSigSendType" SG_ 1280 IC11_MSG_CNT 7;
BA_ "GenSigSendType" SG_ 1280 IC11_CRC 7;
BA_ "GenSigStartValue" SG_ 1280 IC_DRV_MOD_REQ 2;
BA_ "GenSigSendType" SG_ 1280 IC_STEERING_MODE_REQ 7;
BA_ "GenSigSendType" SG_ 956 RESERVED_2 7;
BA_ "GenSigStartValue" SG_ 786 IBS_CURRENT 1250;
BA_ "GenSigStartValue" SG_ 786 IBS_BATT_TEMP 80;
BA_ "GenSigEnvVarType" SG_ 295 ENG_LOSSES 0;
BA_ "GenSigSendType" SG_ 295 ENG_LOSSES 7;
BA_ "GenSigSendType" SG_ 295 EMS21_MSG_CNT 7;
BA_ "GenSigSendType" SG_ 295 EMS21_CRC 7;
BA_ "SignalType" SG_ 375 TGS_LEVER_AMT "ENM";
BA_ "GenSigTimeoutTime_IS" SG_ 375 TGS_LEVER_AMT 100;
BA_ "GenSigEnvVarType" SG_ 375 TGS_LEVER_AMT 0;
BA_ "GenSigSendType" SG_ 375 TGS_LEVER_AMT 7;
BA_ "SignalType" SG_ 375 AMT_MIL "ENM";
BA_ "GenSigStartValue" SG_ 294 MAX_ALL_TRQ 1024;
BA_ "GenSigStartValue" SG_ 294 MIN_ALL_TRQ 1024;
BA_ "GenSigSendType" SG_ 304 ENGINE_DRIVE_MODE 7;
BA_ "GenSigStartValue" SG_ 1077 IDLING_INDEX 10;
BA_ "GenSigStartValue" SG_ 1077 GEAR_MISMATCH 10;
BA_ "GenSigStartValue" SG_ 1077 OVR_SPD 10;
BA_ "GenSigStartValue" SG_ 1077 CLTH_OVRRIDE 10;
BA_ "GenSigStartValue" SG_ 1077 AGG_BRK 10;
BA_ "GenSigStartValue" SG_ 1077 AGG_ACC 10;
BA_ "GenSigStartValue" SG_ 1582 COMMANDED_EGR 300;
BA_ "GenSigStartValue" SG_ 1582 EGR_ERR 600;
BA_ "GenSigStartValue" SG_ 1582 MEUNT_SETPOINT_RAIL_PRESSURE 200;
BA_ "GenSigStartValue" SG_ 1582 MEUNT_SETPOINT_ADPT_CORECT 200;
BA_ "GenSigStartValue" SG_ 1582 MEUNT_CTCL_FLTACT_CURVAL 100;
BA_ "GenSigStartValue" SG_ 1582 FUEL_RAIL_PRESSURE 100;
BA_ "GenSigSendType" SG_ 950 RESERVED_2 7;
BA_ "GenSigSendType" SG_ 962 RESERVED_2 7;
BA_ "GenSigSendType" SG_ 949 RESERVED_2 7;
BA_ "GenSigSendType" SG_ 2025 DIAG_TCU_RES_DATA 7;
BA_ "GenSigStartValue" SG_ 1581 COMMANDED_THRTL_ACTR_CTL 500;
BA_ "GenSigStartValue" SG_ 1413 ENG_OIL_TEMP 40;
BA_ "GenSigSendType" SG_ 259 IMMOVAL3 7;
BA_ "GenSigStartValue" SG_ 274 VCU_TorqueCommand 48;
BA_ "GenSigStartValue" SG_ 821 VCU_DISP_AMBT_TEMP_FATC 40;
BA_ "GenSigStartValue" SG_ 822 VCU_EPTCoolantTemp 40;
BA_ "GenSigStartValue" SG_ 1731 VCU_CharInletTempNeg 40;
BA_ "GenSigStartValue" SG_ 1731 VCU_CharInletTempPos 40;
BA_ "GenSigStartValue" SG_ 988 OBC_PFC_VOLT_CNTRL_IP 30;
BA_ "GenSigStartValue" SG_ 983 MCU_Motor_Temp_Indicator 50;
BA_ "GenSigStartValue" SG_ 983 MCU_Inverter_Temp_Indicator 50;
BA_ "GenSigStartValue" SG_ 280 MCU_MotorSpeed 7;
BA_ "GenSigStartValue" SG_ 280 MCU_MotorTorqueEstimated 48;
BA_ "GenSigStartValue" SG_ 1015 BMS_HTR_CLT_HVInput_V 8;
BA_ "GenSigStartValue" SG_ 984 OBC_Line_Frequency 40;
BA_ "GenSigStartValue" SG_ 986 OBC_SecondarySide_Temperature 550;
BA_ "GenSigStartValue" SG_ 986 OBC_Transformer_Temperature 550;
BA_ "GenSigStartValue" SG_ 986 OBC_PrimarySide_Temperature 550;
BA_ "GenSigStartValue" SG_ 982 MCU_HighPowerCurrent 8184;
BA_ "GenSigStartValue" SG_ 978 BMS_BHeaterOpCoolantTemp 680;
BA_ "GenSigStartValue" SG_ 978 BMS_BatteryOutletCoolantTemp 680;
BA_ "GenSigStartValue" SG_ 978 BMS_BatteryInletCoolantTempReq 680;
BA_ "GenSigStartValue" SG_ 978 BMS_BatteryInletCoolantTemp 680;
BA_ "GenSigStartValue" SG_ 626 BMS_BatteryTBatt 680;
BA_ "GenSigStartValue" SG_ 337 BMS_Current2sensorReading 6000;
BA_ "GenSigStartValue" SG_ 337 BMS_Current1sensorReading 6000;
BA_ "GenSigStartValue" SG_ 1655 CLOCK_YEAR_TGU 16;
BA_ "GenSigStartValue" SG_ 339 TGU_CHARGINGSTARTTIME_YEAR 16;
BA_ "GenSigStartValue" SG_ 339 TGU_CHARGINGENDTIME_YEAR 16;
BA_ "GenSigStartValue" SG_ 338 TGU_TRIPSTARTTIME_YEAR 16;
BA_ "GenSigStartValue" SG_ 338 TGU_TRIPENDTIME_YEAR 16;
BA_ "GenSigStartValue" SG_ 999 BMS_BatteryMaxCellVoltage 3650;
BA_ "GenSigStartValue" SG_ 999 BMS_BatteryMinCellVoltage 3650;
BA_ "GenSigSendType" SG_ 2005 DIAG_TGU_REQ_DATA 7;
BA_ "GenSigSendType" SG_ 2013 DIAG_TGU_RES_DATA 7;
BA_ "SignalType" SG_ 374 TGS_MODE_AMT "ENM";
BA_ "GenSigEnvVarType" SG_ 374 TGS_MODE_AMT 0;
BA_ "GenSigSendType" SG_ 374 TGS_MODE_AMT 7;
BA_ "SignalType" SG_ 374 GEAR_ACTUAL_AMT "ENM";
BA_ "GenSigStartValue" SG_ 264 INTAKE_AIR_TEMP 40;
BA_ "GenSigSendType" SG_ 264 INTAKE_AIR_TEMP 7;
BA_ "GenSigStartValue" SG_ 264 DRIVER_DEMAND_TRQ 1024;
VAL_ 3221225472 VCU_DRIVE_MODE 7 "Signal Invalid" 6 "Reserved" 5 "Reserved" 4 "Reserved" 3 "Normal/Default value" 2 "Sports" 1 "ECO Mode" 0 "Reserved" ;
VAL_ 3221225472 FR_SEAT_HEAT_VENT_LEVEL_MBFM 3 "Level 3" 2 "Level 2" 1 "Level 1" 0 "Default / OFF" ;
VAL_ 3221225472 FL_SEAT_HEAT_VENT_LEVEL_MBFM 3 "Level 3" 2 "Level 2" 1 "Level 1" 0 "Default / OFF" ;
VAL_ 445 STS_ITA 3 "reserved" 2 "Not available" 1 "Available" 0 "Default" ;
VAL_ 445 ITA_ACTIVE 1 "Active" 0 "Inactive / DV" ;
VAL_ 445 CCO_WARNING 7 "RESERVED" 6 "RESERVED" 5 "RESERVED" 4 "RESERVED" 3 "CCO BUTTON FAILED" 2 "HDC FAILED" 1 "TEMP OFF" 0 "NO WARN/DEFAULT" ;
VAL_ 445 CCO_SET_SPD 7 "Target velocity 7" 6 "Target velocity 6" 5 "Target velocity 5" 4 "Target velocity 4" 3 "Target velocity 3" 2 "Target velocity 2" 1 "Target velocity 1" 0 "No speed requirement/default" ;
VAL_ 445 CCO_ACTIVE 3 "FAILURE" 2 "ACTIVE" 1 "STANDBY" 0 "OFF/DEFAULT" ;
VAL_ 1007 VCU_TorqueCoasting 0 "Default Value" ;
VAL_ 1007 VCU_SwitchS2 1 "Activated" 0 "Not Activated" ;
VAL_ 1007 VCU_StCreep 1 "Activated" 0 "Not Activated" ;
VAL_ 1007 VCU_StCoasting 1 "Activated" 0 "Not Activated" ;
VAL_ 1007 VCU_HVAccPowerConsumption 65535 "Invalid" 0 "Default" ;
VAL_ 1007 VCU_EConsPerKm 65535 "Invalid" 0 "Default" ;
VAL_ 823 VCU_StsCodEvse 7 "Reserved" 6 " EVSE_Malfunction" 5 "EVSE_EmergencyShutdown" 4 "EVSE_IsolationMonitoringActive" 3 " EVSE_UtilityInterruptEvent" 2 "EVSE_Shutdown" 1 "EVSE_Ready" 0 "EVSE_NotReady" ;
VAL_ 823 VCU_MaxDischargeCurrent 0 "Default Value" ;
VAL_ 823 VCU_MaxChargeCurrent 0 "Default Value" ;
VAL_ 823 VCU_CmdTargetVoltLDC 255 "Signal invalid" 0 "Default Value" ;
VAL_ 823 VCU_CmdEnableLDC 3 "Invalid" 2 "Reserved" 1 "Enable" 0 "Disable / Initial Value" ;
VAL_ 823 VCU_MainContactorControl 3 "Invalid" 2 "Open Contactor" 1 "Close Contactor" 0 "Init/Default" ;
VAL_ 628 LDC_Lid_STS 3 "SIgnal Invalid" 2 "Close" 1 "Open" 0 "Default" ;
VAL_ 628 LDC_HVIL_Interlock4 3 "Signal Invalid" 2 "Close" 1 "Open" 0 "Init" ;
VAL_ 628 LDC_ACTV_Discharge_STS 2 "ACT_DIS_unsuccessful_with_error" 1 "ACT_DIS_Initiated" 0 "Default" 4 "Signal Invalid" 3 "ACT_DIS_complete_without_error" ;
VAL_ 628 LDC_OperationMode 7 "Invalid" 6 "Reserved" 5 "Reserved" 4 "Fault" 3 "Power Delivery" 2 "Ready" 1 "Not Ready/ Wakeup" 0 "Default Value" ;
VAL_ 628 LDC_FCVoltageValue 4095 "Signal Invalid" 0 "Default Value" ;
VAL_ 628 LDC_HVIL_Interlock3 3 "Signal Invalid" 2 "Close" 1 "Open" 0 "Init" ;
VAL_ 628 LDC_HVIL_Interlock2 3 "Signal Invalid" 2 "Close" 1 "Open" 0 "Init" ;
VAL_ 628 LDC_HVIL_Interlock1 3 "Signal Invalid" 2 "Close" 1 "Open" 0 "Init" ;
VAL_ 991 LDC_OPV_Circuit_Error 1 "Fault" 0 "Default/No fault" ;
VAL_ 991 LDC_Low_Temp_Shutdown 1 "Fault" 0 "Default/No fault" ;
VAL_ 991 LDC_IPV_Circuit_Error 1 "Fault" 0 "Default/No fault" ;
VAL_ 991 LDC_INTERNAL_FAIL 1 "Fault" 0 "Default/No fault" ;
VAL_ 991 LDC_Input_Over_Current 1 "Fault" 0 "Default/No fault" ;
VAL_ 991 LDC_Heat_Sink_Over_Temp_Shutdown 1 "Fault/Warning" 0 "Default/No Fault" ;
VAL_ 991 LDC_HVDC_Side_Relay_Sts 1 "ON" 0 "OFF" ;
VAL_ 991 LDC_CC_CV_STS 1 "CV" 0 "CC" ;
VAL_ 991 LDC_Burst_Mode_Sts 1 "Burst Mode" 0 "Normal Mode" ;
VAL_ 991 LDC_HW_Enable 1 "ON" 0 "OFF" ;
VAL_ 991 LDC_Stage 7 "Signal Invalid" 0 "Default" ;
VAL_ 991 LDC_Debounce_Count 7 "Signal Invalid" 0 "Default " ;
VAL_ 991 LDC_Vprog_Out_of_Range 1 "Fault" 0 "Default/No fault" ;
VAL_ 991 LDC_Watchdog_Failure 1 "Fault/Warning" 0 "Default/No Fault" ;
VAL_ 991 LDC_VCU_Node_Absent 1 "Fault/Warning" 0 "Default/No Fault" ;
VAL_ 991 LDC_Temp_Sensing_Failure 1 "Fault/Warning" 0 "Default/No Fault" ;
VAL_ 991 LDC_IPC_COMM_ERR_OBC 1 "Fault/Warning" 0 "Default/No Fault" ;
VAL_ 991 LDC_EEPROM_Failure 1 "Fault/Warning" 0 "Default/No Fault" ;
VAL_ 991 LDC_Short_Circuit 1 "Fault/Warning" 0 "Default/No Fault" ;
VAL_ 991 LDC_Output_Under_Voltage 1 "Fault/Warning" 0 "Default/No Fault" ;
VAL_ 991 LDC_Output_Over_Voltage 1 "Fault/Warning" 0 "Default/No Fault" ;
VAL_ 991 LDC_Output_Over_Current 1 "Fault/Warning" 0 "Default/No Fault" ;
VAL_ 991 LDC_LPS_Under_Voltage 1 "Fault/Warning" 0 "Default/No Fault" ;
VAL_ 991 LDC_LPS_Over_Voltage 1 "Fault/Warning" 0 "Default/No Fault" ;
VAL_ 991 LDC_Input_Under_Voltage 1 "Fault/Warning" 0 "Default/No Fault" ;
VAL_ 991 LDC_Input_Over_Voltage 1 "Fault/Warning" 0 "Default/No Fault" ;
VAL_ 991 LDC_Heat_Sink_Over_Temp_Wng_2 1 "Fault/Warning" 0 "Default/No Fault" ;
VAL_ 991 LDC_Heat_Sink_Over_Temp_Wng_1 1 "Fault/Warning" 0 "Default/No Fault" ;
VAL_ 991 LDC_Heat_Sink_Over_Temp_Wng_0 1 "Fault/Warning" 0 "Default/No Fault" ;
VAL_ 991 LDC_Amb_Over_Temp_Wng 1 "Fault/Warning" 0 "Default/No Fault" ;
VAL_ 991 LDC_Amb_Over_Temp_Shutdown 1 "Fault/Warning" 0 "Default/No Fault" ;
VAL_ 580 LDC_OutputVoltageValue 4095 "Signal Invalid" 0 "Default Value" ;
VAL_ 580 LDC_OutputCurrent 16383 "Signal Invalid" 0 "Default Value" ;
VAL_ 580 LDC_InputVoltageValue 16383 "Signal Invalid" 0 "Default Value" ;
VAL_ 580 LDC_InputCurrentValue 0 "Default value" 255 "Signal Invalid" ;
VAL_ 989 LDC_Primary_Temperature 4095 "Signal Invalid" 820 "Default" ;
VAL_ 989 LDC_CoolingRequest 255 "Default" ;
VAL_ 989 LDC_MOSFET_Temperature 820 "Default value" 4095 "Invalid Value" ;
VAL_ 989 LDC_Secondary_Temperature 820 "Default value" 4095 "Invalid Value" ;
VAL_ 989 LDC_ProtectionMode 7 "Invalid" 6 "Reserved" 5 "Power Derating3" 4 "Power Derating2" 3 "PowerDerating1" 2 "Fault" 1 "Ok" 0 "Standby/Default" ;
VAL_ 825 BMS_BatteryMinTemperature 680 "Default Value" 4095 "Signal Invalid" ;
VAL_ 825 BMS_BatteryMaxTemperature 680 "DefaultValue" 4095 "Signal Invalid" ;
VAL_ 825 BMS_Actual_Batt_Heater_Pwr 255 "Signal invalid" 0 "Default Value" ;
VAL_ 825 BMS_Req_Batt_Heater_Pwr 255 "Signal Invalid" 0 "Default Value" ;
VAL_ 825 BMS_ChargingStop 1 "Charging Stop Request ON" 0 "Charging Stop Req OFF/Default" ;
VAL_ 825 BMS_BCoolingRequest 3 "Signal Invalid" 2 "Reserved" 1 "Cooling Request ON" 0 "Cooling Request OFF/Default" ;
VAL_ 979 BMS_Discharge_Cycle 65535 "Signal Invalid" 0 "Default Value" ;
VAL_ 979 BMS_Charge_Cycle 65535 "Signal Invalid" 0 "Default Value" ;
VAL_ 979 BMS_ChargePowerAvailable_2 0 "Default value" 4095 "Signal Invalid" ;
VAL_ 979 BMS_ChargePowerAvailable_10 0 "Default value" 4095 "Signal Invalid" ;
VAL_ 1005 BMS_BattBalancingCompSta 4 "Signal Invalid" 3 "Not Completed/Unsuccessful" 2 "In progress" 1 "Completed/Succesful" 0 "Default" ;
VAL_ 1005 BMS_BatteryBalancingSta 2 "Signal Invalid" 1 "ON" 0 "OFF/Default" ;
VAL_ 1005 BMS_BCoolPumpFBSta 6 "Reserved" 5 "Reserved" 4 "Reserved" 3 "Reserved" 7 "Signal Invalid" 2 "Error" 1 "ON" 0 "OFF/Init/Default" ;
VAL_ 1005 BMS_BatteryLowSOC 3 "Signal Invalid" 2 "Reserved" 1 "ON" 0 "OFF/Default" ;
VAL_ 1005 BMS_BatteryAvgTemperature 680 "Default Value" 4095 "Signal Invalid" ;
VAL_ 1005 BMS_STS_IGN 1 "ON (IGN Present)" 0 "OFF(IGN Not Present)/Default" ;
VAL_ 1005 BMS_CellVoltHighWarnDegdFault 3 "ON Level 3 (Fault)" 2 "ON Level 2 (Derated)" 1 "ON Level 1 (Warning)" 0 "OFF" ;
VAL_ 1005 BMS_BPlusContactorWeld 1 "BPlus Contactor Weld" 0 "BPlus Contactor Not Weld" ;
VAL_ 1005 BMS_BMinusContactorWeld 1 "Bminus Conatctor Weld" 0 "Bminus Contactor Not Weld" ;
VAL_ 301 BMS_ACTV_Discharge_STS 4 "Signal Invalid" 3 "Status Unknown" 2 "Active Discharge Failed" 1 "Active Discharge Success" 0 "Default" ;
VAL_ 301 BMS_BatteryBusVoltage 16383 "Signal Invalid" 3650 "Default Value" ;
VAL_ 301 BMS_BatteryPackStatus 7 "Signal Invalid" 6 "Reserved" 5 "Reserved" 4 "Reserved" 3 "Cutoff" 2 "Derated (Error2)" 1 "Warning (Error1)" 0 "Normal / Default  Value" ;
VAL_ 301 BMS_BatteryPackCurrent 6000 "Default Value" 16383 "Invalid Value" ;
VAL_ 301 BMS_OperationMode 15 "Signal Invalid" 14 "Reserved" 13 "Reserved" 12 "Reserved" 11 "Reserved" 10 "Reserved" 9 "Sleep" 8 "HV Disconnect wait" 7 "Discharge" 6 "Charge Stop" 5 "Charge" 4 "Ready" 3 "HV Connect Wait" 2 "Low Power" 1 "Wake Up" 0 "Reserved" ;
VAL_ 1003 BMS_CellTemp9 65535 "Signal Invalid" 750 "Default Value" ;
VAL_ 1003 BMS_CellTemp8 65535 "Signal Invalid" 750 "Default Value" ;
VAL_ 1003 BMS_CellTemp7 65535 "Signal Invalid" 750 "Default Value" ;
VAL_ 1003 BMS_CellTemp6 65535 "Signal Invalid" 750 "Default Value" ;
VAL_ 1003 BMS_CellTemp5 65535 "Signal Invalid" 750 "Default Value" ;
VAL_ 1003 BMS_CellTemp4 65535 "Signal Invalid" 750 "Default Value" ;
VAL_ 1003 BMS_CellTemp32 65535 "Signal Invalid" 750 "Default Value" ;
VAL_ 1003 BMS_CellTemp31 65535 "Signal Invalid" 750 "Default Value" ;
VAL_ 1003 BMS_CellTemp30 65535 "Signal Invalid" 750 "Default Value" ;
VAL_ 1003 BMS_CellTemp29 65535 "Signal Invalid" 750 "Default Value" ;
VAL_ 1003 BMS_CellTemp28 65535 "Signal Invalid" 750 "Default Value" ;
VAL_ 1003 BMS_CellTemp27 65535 "Signal Invalid" 750 "Default Value" ;
VAL_ 1003 BMS_CellTemp26 65535 "Signal Invalid" 750 "Default Value" ;
VAL_ 1003 BMS_CellTemp25 65535 "Signal Invalid" 750 "Default Value" ;
VAL_ 1003 BMS_CellTemp24 65535 "Signal Invalid" 750 "Default Value" ;
VAL_ 1003 BMS_CellTemp23 65535 "Signal Invalid" 750 "Default Value" ;
VAL_ 1003 BMS_CellTemp22 65535 "Signal Invalid" 750 "Default Value" ;
VAL_ 1003 BMS_CellTemp21 65535 "Signal Invalid" 750 "Default Value" ;
VAL_ 1003 BMS_CellTemp20 65535 "Signal Invalid" 750 "Default Value" ;
VAL_ 1003 BMS_CellTemp19 65535 "Signal Invalid" 750 "Default Value" ;
VAL_ 1003 BMS_CellTemp18 65535 "Signal Invalid" 750 "Default Value" ;
VAL_ 1003 BMS_CellTemp17 65535 "Signal Invalid" 750 "Default Value" ;
VAL_ 1003 BMS_CellTemp16 65535 "Signal Invalid" 750 "Default Value" ;
VAL_ 1003 BMS_CellTemp15 65535 "Signal Invalid" 750 "Default Value" ;
VAL_ 1003 BMS_CellTemp14 65535 "Signal Invalid" 750 "Default Value" ;
VAL_ 1003 BMS_CellTemp13 65535 "Signal Invalid" 750 "Default Value" ;
VAL_ 1003 BMS_CellTemp12 65535 "Signal Invalid" 750 "Default Value" ;
VAL_ 1003 BMS_CellTemp11 65535 "Signal Invalid" 750 "Default Value" ;
VAL_ 1003 BMS_CellTemp10 65535 "Signal Invalid" 750 "Default Value" ;
VAL_ 1003 BMS_CellTemp3 65535 "Signal Invalid" 750 "Default Value" ;
VAL_ 1003 BMS_CellTemp2 65535 "Signal Invalid" 750 "Default Value" ;
VAL_ 1003 BMS_CellTemp1 65535 "Signal Invalid" 750 "Default Value" ;
VAL_ 981 BMS_BatteryInstantEnergyCons 4095 "Signal Invalid" 0 "Default value" ;
VAL_ 981 BMS_AveEnergyCons 4095 "Signal Invalid" 0 "Default Value" ;
VAL_ 981 BMS_ALERT_MSGS 45 "Reserved" 44 "Reserved" 43 "Park and Leave Vehicle" 42 "Low Temperature" 41 "Reserved" 40 "Reserved" 39 "Reserved" 38 "Reserved" 37 "Reserved" 36 "Reserved" 35 "Reserved" 34 "Reserved" 33 "Reserved" 32 "Charging" 31 "Reserved" 30 "High Temperature" 29 "Reserved" 28 "Reserved" 27 "Reserved" 26 "Isolation fault" 25 "Reserved" 24 "Reserved" 23 "Reserved" 22 "Reserved" 21 "Reserved" 20 "Reserved" 19 "Reserved" 18 "Reserved" 17 "Reserved" 16 "Reserved" 15 "Reserved" 14 "Reserved" 13 "Reserved" 12 "Reserved" 11 "Service Due" 10 "Reserved" 9 "Reserved" 8 "Drive Fault(EV Sys Malfunction)" 7 "Safe Mode" 6 "Reserved" 5 "Reserved" 4 "GO SLOW(Limp Home)" 3 "Reserved" 2 "Reserved" 1 "Charge Fault" 0 "No Message/Default value" ;
VAL_ 981 BMS_STS_CHARGE_LIGHT_TT 3 "Reserved" 2 "Charge Light Blink" 1 "Charge Light On" 0 "Charge Light Off/Default" ;
VAL_ 981 BMS_SERVICE_LIGHT_TT 3 "Reserved" 2 "Service Light Blink" 1 "Service Light On" 0 "Service Light Off/Default value" ;
VAL_ 981 BMS_HV_BATT_TT 3 "Reserved" 2 "Flash" 1 "ON" 0 "No Failure/Default" ;
VAL_ 981 BMS_HIGH_TEMP_LIGHT_OP_TT 3 "Reserved" 2 "Temp Light Blink" 1 "Temp Light On" 0 "Temp Light Off/Default value" ;
VAL_ 981 BMS_EVWARNING_TT 3 "Reserved" 2 "EV Warning Blink" 1 "EV Warning   On" 0 "EV Warning Off/Default value" ;
VAL_ 779 TIME_GAP_FRM 255 "NO Object Detected / Default" ;
VAL_ 1585 TRANSFER_MODE_ICC 3 "Signal Invalid" 2 "4WD Low" 1 "4WD High" 0 "2WD / Default Value" ;
VAL_ 1585 ICC_ALERT_MSG 7 "Reserved" 6 "Reserved" 5 "Reserved" 4 "Reserved" 3 "Transfer Mode Entered" 2 "Transfer mod Shifting InProgress" 1 "Terrain Mode Inhibited" 0 "No Alert/ Default" ;
VAL_ 1170 IBS_BATT_TEMP_MBFM 65535 "Signal Invalid" 0 "Default" ;
VAL_ 1170 IBS_BATT_VOLT_MBFM 65535 "Signal Invalid" 4 "Default" ;
VAL_ 1170 IBS_CURRENT_MBFM 65535 "Signal Invalid" 0 "Default" ;
VAL_ 1169 BATT_RESET_FLG_MBFM 1 "True" 0 "False / Default" ;
VAL_ 1169 STS_ESS_DEACTIVATION_MBFM 7 "Reserved" 6 "Reserved" 5 "Reserved" 4 "Preemptive Start" 3 "ESS Deactivation" 2 "ESS Start Inhibit" 1 "ESS Stop Inhibit" 0 "Default" ;
VAL_ 1169 BATT_CHARGE_LAMP_INDC_MBFM 3 "Signal Invalid" 2 "Reserved" 1 "ON/Default" 0 "OFF" ;
VAL_ 1169 ALTERNATOR_MODE_MBFM 7 "Signal Invalid" 6 "Reserved" 5 "Reserved" 4 "Reserved" 3 "Redun" 2 "Cutoff" 1 "Regen" 0 "Normal/default" ;
VAL_ 1169 IBS_SOF_MBFM 255 "Signal Invalid" 0 "Default" ;
VAL_ 1169 IBS_SOH_MBFM 255 "Signal Invalid" 0 "Default" ;
VAL_ 1169 IBS_SOC_MBFM 255 "Signal Invalid" 0 "Default" ;
VAL_ 870 PKE_PACK_MCM 1 "Received" 0 "Other" ;
VAL_ 870 PKE_NACK_MCM 1 "Received" 0 "Other" ;
VAL_ 870 CURRENT_CYL_AUTH_STS_MCM 1 "Authentication Fail" 0 "Authentication Pass" ;
VAL_ 870 REMOTE_ENG_START_STATE_MCM 3 "Remote Engine Extension" 2 "Remote Engine Stop" 1 "Remote Engine Start request" 0 "Default" ;
VAL_ 870 TOTAL_AUTH_TIMER_STS_MCM 3 "Timer Elapsed" 2 "Reserve" 1 "Reserve" 0 "Timer not elapsed" ;
VAL_ 870 PREVIOUS_CYL_AUTH_STS 1 "Authentication Fail" 0 "Authentication Pass" ;
VAL_ 870 MCMTRG_RECEIVE_STS_MCM 1 "MCMTRG not sent" 0 "MCMTRG senrt" ;
VAL_ 870 MCM_NACK_TX 1 "Transmitted" 0 "Other" ;
VAL_ 870 MCM_PACK_TX 1 "Transmitted" 0 "Other" ;
VAL_ 870 RESPONSE_STS_MCM 1 "Response not sent" 0 "Response Sent" ;
VAL_ 870 PKE_CHALLENGE_STS_MCM 1 "PKE Challenge Not Received" 0 "PKE Challenge Received" ;
VAL_ 870 REMOTE_VEH_IMMO_STS_MCM 1 "Remote Vehicle Immobilization" 0 "Remote Vehicle Release" ;
VAL_ 870 SIG1_MATCH_STS 1 "SIG1 Match failed" 0 "SIG1 Match passed" ;
VAL_ 1654 UPDATE_REPROG_USER_AUTH 3 "Reserved" 2 "Default Value" 1 "Req UsrAuth to ReProg aft downld" 0 "Usr acptd/UsrAuth not req reprg" ;
VAL_ 1654 UPDATE_DOWNLOAD_USER_AUTH 3 "Reserved" 2 "Default Value" 1 "Req UsrAuth to downld update" 0 "Usr acptd/UsrAuth not req update" ;
VAL_ 1248 GEAR_UTILIZATION_ECO_GEAR_R 0 "Default Value" ;
VAL_ 1248 GEAR_UTILIZATION_ECO_GEAR_N 0 "Default Value" ;
VAL_ 1248 GEAR_UTILIZATION_ECO_GEAR_6 0 "Default Value" ;
VAL_ 1248 GEAR_UTILIZATION_ECO_GEAR_5 0 "Default Value" ;
VAL_ 1248 GEAR_UTILIZATION_ECO_GEAR_4 0 "Default Value" ;
VAL_ 1248 GEAR_UTILIZATION_ECO_GEAR_3 0 "Default Value" ;
VAL_ 1248 GEAR_UTILIZATION_ECO_GEAR_2 0 "Default Value" ;
VAL_ 1248 GEAR_UTILIZATION_ECO_GEAR_1 0 "Default Value" ;
VAL_ 1280 IC_DRV_MOD_REQ 7 "Signal Invalid" 6 "Reserved / Mode 6" 5 "Reserved / Mode 5" 4 "Reserved / Mode 4" 3 "Default" 2 "Sport Mode / Mode 3" 1 "Eco / City / Mode 2" 0 "Power / Dynamic / Mode 1 " ;
VAL_ 1280 MODE_SELECTION_SWT 13 "Reserved" 12 "Reserved" 11 "Reserved" 10 "Reserved" 9 "Reserved" 8 "Reserved" 7 "Reserved" 14 "Reserved" 15 "Signal Invalid" 6 "Reserved" 5 "Reserved" 4 "Reserved" 3 "SAND " 2 "MUD & RUT " 1 "Grass / Snow " 0 "Normal / Default" ;
VAL_ 1280 IC_STEERING_MODE_REQ 7 "SIGNAL INVALID" 6 "RESERVED" 5 "RESERVED" 4 "RESERVED" 3 "SPORT" 2 "NORMAL" 1 "COMFORT" 0 "DEFAULT" ;
VAL_ 154 MCM_WAKEUP_REASON 14 "Reserved" 13 "Reserved" 12 "Reserved" 11 "window open/close request" 10 "Vehicle Battery Status request" 9 "Remote Charging Request" 8 "Passive Ventilation request" 7 "Park Lamp OFF Request" 6 "Remote Engine Start Request" 5 "Headlamp ON/OFF Request" 4 "Hazard Request" 3 "Search Car Request" 2 "Door Unock Request" 1 "Door Lock Request" 0 "Default" ;
VAL_ 1587 VEH_BATT_STS_REQ 1 "Vehicle Battery Status Request" 0 "Default / No Request" ;
VAL_ 1587 REMOTE_START_TIMER_REQUEST 0 "Default" ;
VAL_ 1587 REQ_PASSIVE_VENT_MCM 3 "Reserved" 2 "Deactive Passive Ventilation" 1 "Activate Passive ventilation" 0 "Default/No request" ;
VAL_ 1587 SET_VACATION_MODE_MCM 1 "Enable" 0 "Disable/Default Value" ;
VAL_ 1587 TURN_OFF_AC_VALET_MCM 3 "SIGNAL INVALID" 2 "Default Value" 1 "Reserved" 0 "AC OFF" ;
VAL_ 1587 SUNROOF_UP_DOWN_MCM 3 "Reserved" 2 "Sunroof Close" 1 "Sunroof Open" 0 "Default" ;
VAL_ 1587 POWER_WIND_UP_DOWN_MCM 3 "Reserved" 2 "Power Window Open" 1 "Power Window Close" 0 "Default" ;
VAL_ 1587 REMOTE_START_EXT_REQ_MCM 4 "4th Extension" 3 "3rd Extension" 2 "2nd Extension" 1 "1st Extension" 0 "Default/No Extension" ;
VAL_ 1587 REMOTE_ENG_START_STOP_MCM 3 "Signal Invalid" 2 "Remote Engine Stop" 1 "Remote Engine Start" 0 "Default" ;
VAL_ 1587 INHIBIT_ENG_START_MCM 1 "Inhibit Engine Start" 0 "DEFAULT/NORMAL" ;
VAL_ 1587 TURN_ON_OFF_PARK_LAMP_MCM 1 "off request" 0 "No Request/Default" ;
VAL_ 1587 REQ_HEADLAMP_MCM 3 "Signal Invalid" 2 "Headlamp ON" 1 "Headlamp Off" 0 "Default / No req" ;
VAL_ 1587 REQ_HAZARD_MCM 3 "Signal Invalid" 2 "Hazard On" 1 "hazard Off" 0 "Default/No Req" ;
VAL_ 1587 SEARCH_CAR_MCM 1 "Search CAR Request" 0 "No Request" ;
VAL_ 1587 DOOR_LOCK_MCM 3 "Signal Invalid" 2 "Unlock" 1 "Lock" 0 "Default" ;
VAL_ 786 IBS_CURRENT 65535 "Signal Invalid" 0 "Default" ;
VAL_ 786 IBS_BATT_TEMP 65535 "Signal Invalid" 0 "Default" ;
VAL_ 786 IBS_BATT_VOLT 65535 "Signal Invalid" 4 "Default" ;
VAL_ 784 BATT_RESET_FLG 1 "True" 0 "False / Default" ;
VAL_ 784 STS_ESS_DEACTIVATION 7 "Reserved" 6 "Reserved" 5 "Reserved" 4 "Preemptive Start" 3 "ESS Deactivation" 2 "ESS Start Inhibit" 1 "ESS Stop Inhibit" 0 "Default" ;
VAL_ 784 IBS_SOC 255 "Signal Invalid" 0 "Default" ;
VAL_ 784 ALTERNATOR_MODE 7 "Signal Invalid" 6 "Reserved" 5 "Reserved" 4 "Reserved" 3 "Redun" 2 "Cutoff" 1 "Regen" 0 "Normal/default" ;
VAL_ 784 IBS_SOF 255 "Signal Invalid" 0 "Default" ;
VAL_ 784 IBS_SOH 255 "Signal Invalid" 0 "Default" ;
VAL_ 784 BATT_CHARGE_LAMP_INDC 3 "Signal Invalid" 2 "Reserved" 1 "ON/Default" 0 "OFF" ;
VAL_ 563 UREA_LEVEL_PERCENTAGE 255 "Signal Invalid" 0 "Default" ;
VAL_ 563 INCORRECT_DEF 7 "Reserved" 6 "Reserved" 5 "Reserved" 4 "Level4" 3 "Level3" 2 "Level2" 1 "Level1" 0 "Normal / Default value" ;
VAL_ 563 DIST_DEF_EMPTY 65533 "DEF Level Normal" 65535 "Signal invalid" 65534 "Default value" ;
VAL_ 563 DEF_LEVEL 7 "Reserved" 6 "Reserved" 5 "Reserved" 4 "Level4" 3 "Level3" 2 "Level2" 1 "Level1" 0 "Normal / Default value" ;
VAL_ 563 DEF_DOSING_MALFUNC 7 "Reserved" 6 "Reserved" 5 "Reserved" 4 "Level4" 3 "Level3" 2 "Level2" 1 "Level1" 0 "Normal / Default value" ;
VAL_ 563 INDC_REGEN 3 "Reserved" 2 "Regen TT Blink/regen in progress" 1 "Regen TT Lamp ON/regen needed" 0 "Regen TT Lamp OFF/No regen/DV" ;
VAL_ 295 ACC_PED_ACTUAL 255 "Signal Invalid" 0 "Default" ;
VAL_ 295 ENG_LOSSES 2047 "Signal invalid" 2046 "Default value" ;
VAL_ 295 BRK_PEDAL1 3 "Signal Invalid" 2 "Reserved" 1 "Depressed" 0 "Not Pressed / Default" ;
VAL_ 375 TGS_LEVER_AMT 15 "Signal Invalid" 14 "Middle Position" 13 "Default Value" 12 "M - Forward Drive Position" 11 "Tip -" 10 "Tip +" 9 "Park " 8 "Reverse" 7 "Neutral" 6 "Drive" 5 "Reserved" 4 "Reserved" 3 "Reserved" 2 "Reserved" 1 "Reserved" 0 "Reserved" ;
VAL_ 375 AMT_BUZZER 1 "BUZZER ON" 0 "BUZZER OFF / Default Value" ;
VAL_ 375 AMT_MIL 3 "Lamp ON" 2 "Reserved" 1 "Lamp Blinking" 0 "Lamp OFF / Default " ;
VAL_ 375 ALERT_AMT 7 "Reserved" 6 "Reserved" 5 "1st Gear not Enguage" 4 "Gear lock out" 3 "Operation Not Allowed" 2 "Press Brake" 1 "Put Vehicle in Neutral" 0 "Default Value" ;
VAL_ 294 HYBRID_LAMP_INDC 3 "Reserved" 2 "Lamp Blinking" 1 "Lamp ON" 0 "Lamp OFF/Default" ;
VAL_ 294 MAX_ALL_TRQ 2047 "Signal Invalid" 0 "Default" ;
VAL_ 294 GEAR_UP_FLG 1 "Flag Enable" 0 "Flag Disable / Default value" ;
VAL_ 294 GEAR_DOWN_FLG 1 "Gear_Down_Flag_Enable" 0 "Gear_Down_Flag_Disable" ;
VAL_ 294 MIN_ALL_TRQ 2047 "Signal Invalid" 0 "Default" ;
VAL_ 294 TARGET_GEAR_GSI 15 "Signal Invalid" 14 "Reserved" 13 "Reserved" 12 "Reserved" 11 "Reserved" 10 "Reserved" 9 "Reserved" 8 "Reserved" 7 "Reverse Gear" 6 "6th Gear" 5 "5th Gear" 4 "4th Gear" 3 "3rd Gear" 2 "2nd Gear" 1 "1st Gear" 0 "Neutral / Default" ;
VAL_ 304 ERROR_FLAG_VCU 3 "Reserved" 2 "Reserved" 1 "Error Present in EMS Memory" 0 "No Error Present in EMS memory" ;
VAL_ 304 CRUISE_ALERT 3 "Reserved" 2 "Cruise  Active " 1 "Cruise Standby" 0 "OFF / Default" ;
VAL_ 304 CRUISE_SET_SPD 65535 "Signal Invalid" 0 "Default" ;
VAL_ 304 INDC_SYS_LAMP 3 "Signal Invalid" 2 "Lamp ON" 1 "Lamp Blinking" 0 "Lamp OFF/Default" ;
VAL_ 304 ACC_READY 1 "Ready" 0 "Default / Not ready" ;
VAL_ 304 EMS_DRIVE_ALERT 3 "Reserved" 2 "Reserved" 1 "Drive Mode not possible" 0 "No Alert/Default" ;
VAL_ 304 STS_EMS_DRV_ADV_MODE 3 "Ready to enter" 2 "In Progress" 1 "Mode active / Default" 0 "Not active" ;
VAL_ 304 INDC_DPF_REGEN 3 "Reserved" 2 "Blink" 1 "DPF Lamp ON" 0 "DPF Lamp OFF / DV" ;
VAL_ 304 ENGINE_DRIVE_MODE 7 "Signal Invalid" 6 "Sand / Mode 7" 5 "Mud & Rut / Mode 6" 4 "Grass / Snow / Mode 5" 3 "Normal / Mode 4" 2 "Sport / Mode 3" 1 "Eco / City / Mode 2" 0 "Power / Dynamic / Mode 1" ;
VAL_ 304 FUEL_CONSMP_RATE 65535 "Signal Invalid" 0 "Default" ;
VAL_ 304 ENG_OIL_PRESSURE 1 "Oil Pressure Low" 0 "Normal / Default" ;
VAL_ 304 INDC_MIL 3 "Signal Invalid" 2 "MIL Lamp ON" 1 "MIL Lamp Blinking" 0 "MIL OFF/Default" ;
VAL_ 1638 ASD_TORQUE 127 "Signal Invalid" 0 " Default" ;
VAL_ 1638 ASD_POWER 127 "Signal Invalid" 0 " Default" ;
VAL_ 1638 INDC_ROLL_IS 127 "Signal Invalid" 0 "Default" ;
VAL_ 1638 INDC_PITCH_IS 127 "Signal Invalid" 0 "Default" ;
VAL_ 1638 ALTIMETER 0 "Default" ;
VAL_ 1638 COMPASS_DIRECTION 15 "RESERVED" 14 "RESERVED" 13 "RESERVED" 12 "RESERVED" 11 "RESERVED" 10 "RESERVED" 9 "RESERVED" 8 "SOUTH WEST" 7 "SOUTH EAST" 6 "NORTH WEST" 5 "NORTH EAST" 4 "SOUTH" 3 "NORTH" 2 "WEST" 1 "EAST" 0 "Default" ;
VAL_ 1079 ESS_DURATION 4095 "Signal Invalid" 0 "Default Value" ;
VAL_ 1079 IDLING_DURATION 255 "Signal Invalid" 0 "Default Value" ;
VAL_ 1078 INST_ECO_INDEX_EMS 127 "Signal Invalid" 100 "Default Value" ;
VAL_ 1078 REMOTE_START_INHIBIT_REQ_IS 1 "Inhibit Request" 0 "No Request" ;
VAL_ 1078 TRIP_START_END 3 "Reserved" 2 "Trip End" 1 "Trip Start" 0 "Default" ;
VAL_ 1078 TRIP_ID 0 "Default" ;
VAL_ 1078 GEAR_UP_FLG 1 "Flag Enable" 0 "Flag Disable / Default value" ;
VAL_ 1078 GEAR_DOWN_FLG 1 "Gear_Down_Flag_Enable" 0 "Gear_Down_Flag_Disable" ;
VAL_ 1078 TRIP_DURATION_MIN 15 "Signal Invalid" 0 "Default Value" ;
VAL_ 1078 AVG_SPD 511 "Signal Invalid" 0 "Default Value" ;
VAL_ 1078 TOP_SPD 511 "Signal Invalid" 0 "Default Value" ;
VAL_ 1078 TRIP_DIST 65535 "Signal Invalid" 0 "Default Value" ;
VAL_ 1078 TRIP_DURATION_HOUR 127 "Signal Invalid" 0 "Default Value" ;
VAL_ 1406 FUEL_ECONOMY_ECO 0 "Description for the value '0x0'" ;
VAL_ 1406 TRIP_TAGGING_ECO 7 "Reserved" 6 "Reserved" 5 "Reserved" 4 "Reserved" 3 "Reserved" 2 "Personal Trip" 1 "Business Trip" 0 "Default Value" ;
VAL_ 1406 AGG_BRK_COUNT_ECO 0 "Description for the value '0x0'" ;
VAL_ 1406 AGG_ACC_COUNT_ECO 0 "Description for the value '0x0'" ;
VAL_ 1406 GEAR_UTILIZATION_ECO 0 "Default Value" ;
VAL_ 1406 AUDIO_SOURCE 15 "Reserved" 14 "Reserved" 13 "Reserved" 12 "Reserved" 11 "My Drive" 10 "Android Auto" 9 "Apple CARplay" 8 "Ipod" 7 "Bluetooth" 6 "AUX" 5 "USB" 4 "AM2" 3 "AM1" 2 "FM2" 1 "FM1" 0 "Default" ;
VAL_ 1077 CLUTCH_PRESS_CNT 255 "Signal Invalid" 0 "Default Value" ;
VAL_ 1077 BRK_PRESS_CNT 255 "Signal Invalid" 0 "Default Value" ;
VAL_ 1077 IDLING_INDEX 15 "Signal Invalid" 10 "Default value" ;
VAL_ 1077 GEAR_MISMATCH 15 "Signal Invalid" 10 "Default Value" ;
VAL_ 1077 OVR_SPD 15 "Signal Invalid" 10 "Default Value" ;
VAL_ 1077 CLTH_OVRRIDE 15 "Signal Invalid" 10 "Default Value" ;
VAL_ 1077 AGG_BRK 15 "Signal Invalid" 10 "Default Value" ;
VAL_ 1077 AGG_ACC 15 "Signal Invalid" 10 "Default Value" ;
VAL_ 1077 ECO_INDEX_IS11 127 "Signal Invalid" 100 "Default Value" ;
VAL_ 1077 STS_TRIP 1 "Trip Reset completed" 0 "Default Value" ;
VAL_ 1077 COMM_ERR_FLG 1 "Flag Enable" 0 "Flag Disable / Default Value" ;
VAL_ 1077 TPMS_FLG 1 "Flag Enable" 0 "Flag Disable / Default Value" ;
VAL_ 1077 AC_USAGE_REG_FLG 1 "Flag Enable" 0 "Flag Disable / Default Value" ;
VAL_ 1077 IDLING_FLG 1 "Flag Enable" 0 "Flag Disable / Default Value" ;
VAL_ 1077 OVRSPD_FLG 1 "Flag Enable" 0 "Flag Diable / Default Value" ;
VAL_ 1077 CLUTCH_OVRRIDE_FLG 1 "Flag Enable" 0 "Flag Disable / Default Value" ;
VAL_ 752 SVS_SWT 1 "Pressed" 0 "Not Pressed / Default" ;
VAL_ 752 STS_AUTO_ZOOM_IN_VIEW 1 "Enable" 0 "Disable/DV" ;
VAL_ 752 STS_AUTO_CORNER_VIEW 1 "Enable" 0 "Disable/DV" ;
VAL_ 752 DEFAULT_VIEW_FRONT 1 "Full View" 0 "Normal View" ;
VAL_ 752 SVS_SCREEN_ACTIVE_IS 1 "IS Screen Active" 0 "Not Active" ;
VAL_ 752 SVS_ENABLE_IS 1 "SVS Screen Enable" 0 "Default/SVS Screen Disable" ;
VAL_ 752 FIRST_TOUCH_COORDINATE_Y_IS 0 "Default Value" ;
VAL_ 752 FIRST_TOUCH_COORDINATE_X_IS 0 "Default Value" ;
VAL_ 752 FIRST_TOUCH_EVENT_IS 3 "Pen Move" 2 "Pen Up" 1 "Pen down" 0 "No touch/ Default value" ;
VAL_ 752 CMD_USER_INPUT 15 "Reserved" 14 "Reserved" 13 "Reserved" 12 "Reserved" 11 "Back" 10 "Right Corner View" 9 "Left Corner View" 8 "Merged Corner View" 7 "Full View" 6 "Zoom Out" 5 "Zoom In" 4 "Reset to parallel parking" 3 "Normal View" 2 "Vertical Parking" 1 "Parallel Parking" 0 "No Input/ Default" ;
VAL_ 752 ONTOUCH_INPUT_IS 3 "Three touch" 2 "Two touch" 1 "One touch" 0 "No touch/Default Value" ;
VAL_ 752 IS_REQUEST_VIEW 28 "Right full view without icons" 27 "Left full view without icons" 26 "Rear full view without icons" 24 "Right Fish View+2D/Man Cal" 23 "Left Fish View+2D/Man Cal" 22 "Rear Fish View+2D/Man Cal" 21 "Front Fish View+2D/Man Cal" 20 "2D Full View / Auto Cal" 19 "3D Full View / Bowl view" 18 " Intelligent View Rear" 17 " Intelligent View Front " 16 "2D+3D Rear Right view " 25 "Front full view without icons" 15 "2D+3D Rear Left view " 14 "2D+3D Front Right view " 13 "2D+3D Front Left view " 12 "2D+3D Right view " 11 "2D+3D Left view " 10 "2D+3D Rear view " 9 "2D+3D Front view " 8 "Right Full View" 7 "Left Full View" 6 "Rear Full View" 5 "Front Full View" 4 "2D+Right view " 3 "2D+Left view " 2 "2D+Rear view " 1 "2D+Front view " 0 "No View" ;
VAL_ 752 DEFAULT_VIEW_REAR 1 "Full View" 0 "Normal View" ;
VAL_ 752 IS_VIDEO_ENBL 7 "Reserved" 6 "Reserved" 5 "RVC & FVC Video Enabled" 4 "FVC Video Disabled" 3 "FVC Video Enabled" 2 "RVC Video Disabled" 1 "RVC Video Enabled" 0 "No Video Enabled / Default" ;
VAL_ 1428 BRAKE_PREDICTION_STS 3 "Invaild" 2 "Red" 1 "Green" 0 "Default / Not Available" ;
VAL_ 922 SVS_VIEW_REQUEST_IC 1 "Cluster view request" 0 "No request" ;
VAL_ 922 SVS_VIEW_REQUEST_IS 1 "Infotainment View Request" 0 "No request" ;
VAL_ 922 SVS_INFO 1 "pop-up" 0 "No pop-up" ;
VAL_ 922 SVS_GUIDED_VOICE_REQ 15 "Reserved" 14 "Reserved" 13 "Reserved" 12 "Reserved" 11 "Reserved" 10 "Reserved" 9 "Reserved" 8 "Reserved" 7 "Angle_Parking_VMS_2" 6 "Angle_Parking_VMS_1" 5 "Parallel Parking_VMS_4" 4 "Parallel Parking_VMS_3" 3 "Parallel Parking_VMS_2" 2 "Parallel Parking_VMS_1" 1 "Parking Slection" 0 "No Message" ;
VAL_ 1582 FUEL_PUMP_PREDICTION 0 "No Drift / Default" 3 "Reserved" 2 "High Drift" 1 "Moderate Drift" ;
VAL_ 767 ROTARY_ENCODER 63 "Reserved" 62 "Reserved" 61 "Reserved" 60 "Reserved" 59 "Reserved" 58 "Reserved" 57 "Reserved" 56 "Step 24" 55 "Step 23" 54 "Step 22" 53 "Step 21" 52 "Step 20" 51 "Step 19" 50 "Step 18" 49 "Step 17" 48 "Step 16" 47 "Step 15" 46 "Step 14" 45 "Step 13" 44 "Step 12" 43 "Step 11" 42 "Step 10" 41 "Step 9" 40 "Step 8" 39 "Step 7" 38 "Step 6" 37 "Step 5" 36 "Step 4" 35 "Step 3" 34 "Step 2" 33 "Step 1" 32 "Default" 31 "Step -1" 30 "Step -2" 29 "Step -3" 28 "Step -4" 27 "Step -5" 26 "Step -6" 25 "Step -7" 24 "Step -8" 23 "Step -9" 22 "Step -10" 21 "Step -11" 20 "Step -12" 19 "Step -13" 18 "Step -14" 17 "Step -15" 16 "Step -16" 15 "Step -17" 14 "Step -18" 13 "Step -19" 12 "Step -20" 11 "Step -21" 10 "Step -22" 9 "Step -23" 8 "Step -24" 7 "Reserved" 6 "Reserved" 5 "Reserved" 4 "Reserved" 3 "Reserved" 2 "Reserved" 1 "Reserved" 0 "Reserved" ;
VAL_ 767 CENTER_BUTTON_STS 3 "Switch Fault/ Signal Invalid" 2 "Reserved" 1 "Pressed" 0 "Not Pressed/ Default" ;
VAL_ 767 JOYSTICK_DB_STS 3 "Switch Fault/ Signal Invalid" 2 "Reserved" 1 "Pressed" 0 "Not Pressed/ Default" ;
VAL_ 767 JOYSTICK_UB_STS 3 "Switch Fault/ Signal Invalid" 2 "Reserved" 1 "Pressed" 0 "Not Pressed/ Default" ;
VAL_ 767 JOYSTICK_RB_STS 3 "Switch Fault/ Signal Invalid" 2 "Reserved" 1 "Pressed" 0 "Not Pressed/ Default" ;
VAL_ 767 JOYSTICK_LB_STS 3 "Switch Fault/ Signal Invalid" 2 "Reserved" 1 "Pressed" 0 "Not Pressed/ Default" ;
VAL_ 767 BUTTON4_STS 3 "Switch Fault/ Signal Invalid" 2 "Reserved" 1 "Pressed" 0 "Not Pressed/ Default" ;
VAL_ 767 BUTTON3_STS 3 "Switch Fault/ Signal Invalid" 2 "Reserved" 1 "Pressed" 0 "Not Pressed/ Default" ;
VAL_ 767 BUTTON2_STS 3 "Switch Fault/ Signal Invalid" 2 "Reserved" 1 "Pressed" 0 "Not Pressed/ Default" ;
VAL_ 767 BUTTON1_STS 3 "Switch Fault/ Signal Invalid" 2 "Reserved" 1 "Pressed" 0 "Not Pressed/ Default" ;
VAL_ 917 FVC_OPERATION_STATE 7 "Reserved" 6 "Reserved" 5 "Test Mode(Internal)-video ON" 4 "FVC Faulty(FVC OFF)" 3 "Calibration EOL/Dealer Video ON" 2 "Fault(Video ON)" 1 "Operation(Video ON)" 0 "Standby(Video OFF)" ;
VAL_ 917 FVC_BUTTON_GROUP 15 "Reserved" 14 "Reserved" 13 "Reserved" 12 "Reserved" 11 "Button_Group_11" 10 "Button_Group_10" 9 "Reserved" 8 "Reserved" 7 "Reserved" 6 "Button_Group_6" 5 "Button_Group_5" 4 "Button_Group_4" 3 "Button_Group_3" 2 "Reserved" 1 "Reserved" 0 "No Button / Default" ;
VAL_ 930 APA_MAMS_ACTIVE 1 "MAMS Active" 0 "MAMS Not Active / Default" ;
VAL_ 930 SLOT_LENGTH_WIDTH 161 "Reserved (0xA1 to 0xFE)" 1 "Valid lnght/Width(0x1 to 0xA0)" 255 "Invalid slot length/slot width" 0 "Default value" ;
VAL_ 930 SLOT_DEPTH 251 "Reserved (0xFB to 0xFE)" 1 "Valid slot depth(0x1 to 0xFA)" 255 "Invalid Slot Depth" 0 "Default Value" ;
VAL_ 930 DIST_TO_SLOT 201 "Reserved(0xC9 to 0xFE)" 1 "Valid dist to slot(0x1 to 0xC8)" 255 "Signal invalid" 0 "Default" ;
VAL_ 930 DIST_TO_SAFE_PT 201 "Reserved(0xC9 to 0xFE)" 1 "Valid dist to slot (0x1 to C8)" 255 "Signal invalid" 0 "Default" ;
VAL_ 930 APA_PROGRESS_PERCNTG 1 "Prcntg of  prgrss bar(0x1to0x63)" 100 "Progress bar is full" 101 "Reserved(0x65 to 0xFE)" 255 "Signal Invalid" 0 "Default" ;
VAL_ 930 APA_PARK_MODE 15 "Signal Invalid" 14 "Reserved" 13 "Reserved" 12 "Reserved" 11 "Reserved" 10 "Reserved" 9 "Reserved" 8 "Reserved" 7 "Reserved" 6 "Reserved" 5 "Reserved" 4 "Perpendicular drive out" 3 "Parallel drive out" 2 "Perpendicular parking" 1 "Parallel Parking" 0 "Default" ;
VAL_ 930 APA_PARK_DIRCTION 3 "Invalid" 2 "Left" 1 "Right" 0 "Default" ;
VAL_ 930 APA_INHIBIT_ST 1 "APA Inhibited" 0 "APA not Inhibited / Default" ;
VAL_ 930 APA_DISP_SUB_PIC 1 "Disp to guide drvr(0x1 to 0xE)" 15 "Signal Invalid" 0 "Default value(No pic to disp)" ;
VAL_ 930 APA_DISP_MAIN_PIC 1 "Disp to guide drvr(0x1 to 0x3E)" 63 "Signal Invalid" 0 "Default Value(No pic disp)" ;
VAL_ 930 APA_DISP 1 "APA Display on HMI Active" 0 "APA Display on HMI not active" ;
VAL_ 930 APA_ACTIVE 1 "APA System Active." 0 "APA System not active" ;
VAL_ 930 FPAS_SW_STS 1 "FPAS  Active." 0 "FPAS not active" ;
VAL_ 930 MAMS_SWT_STS 1 "MAMS switch pressed" 0 "MAMS switch not pressed / DV" ;
VAL_ 929 FLS_SEGMENT 15 "Sensor error" 14 "Reserved" 13 "Reserved" 12 "Reserved" 11 "Reserved" 10 "Reserved" 9 "Reserved" 8 "Reserved" 7 "Reserved" 6 "Display 6 Segment" 5 "Display 5 Segment" 4 "Display 4 Segment" 3 "Display 3 Segment" 2 "Display 2 Segment" 1 "Display 1 Segment" 0 "Default / No Display Segment" ;
VAL_ 929 LEFT_MIN_DIST 251 "Reserved (0xFB to 0xFE)" 255 "Default Value" 0 "Valid dist(0x0 to 0xFA)" ;
VAL_ 929 RRMS_SEGMENT 15 "Sensor error" 14 "Reserved" 13 "Reserved" 12 "Reserved" 11 "Reserved" 10 "Reserved" 9 "Reserved" 8 "Reserved" 7 "Reserved" 6 "Display 6 Segment" 5 "Display 5 Segment" 4 "Display 4 Segment" 3 "Display 3 Segment" 2 "Display 2 Segment" 1 "Display 1 Segment" 0 "Default / No Display Segment" ;
VAL_ 929 FRMS_SEGMENT 15 "Sensor error" 14 "Reserved" 13 "Reserved" 12 "Reserved" 11 "Reserved" 10 "Reserved" 9 "Reserved" 8 "Reserved" 7 "Reserved" 6 "Display 6 Segment" 5 "Display 5 Segment" 4 "Display 4 Segment" 3 "Display 3 Segment" 2 "Display 2 Segment" 1 "Display 1 Segment" 0 "Default / No Display Segment" ;
VAL_ 929 RIGHT_MIN_DIST 251 "Reserved (0xFB to 0x FE)" 255 "Default Value" 0 "Valid dist (0x0 t 0xFA)" ;
VAL_ 929 RRS_SEG_WARN 1 "Warning" 0 "No Warning/Default" ;
VAL_ 929 RRMS_SEG_WARN 1 "Warning" 0 "No Warning/Default" ;
VAL_ 929 RLMS_SEG_WARN 1 "Warning" 0 "No Warning/Default" ;
VAL_ 929 RLS_SEG_WARN 1 "Warning" 0 "No Warning/Default" ;
VAL_ 929 FRS_SEG_WARN 1 "Warning" 0 "No Warning/Default" ;
VAL_ 929 FLMS_SEG_WARN 1 "Warning" 0 "No Warning/Default" ;
VAL_ 929 RRS_SEGMENT 15 "Sensor error" 14 "Reserved" 13 "Reserved" 12 "Reserved" 11 "Reserved" 10 "Reserved" 9 "Reserved" 8 "Reserved" 7 "Reserved" 6 "Display 6 Segment" 5 "Display 5 Segment" 4 "Display 4 Segment" 3 "Display 3 Segment" 2 "Display 2 Segment" 1 "Display 1 Segment" 0 "Default / No Display Segment" ;
VAL_ 929 RLMS_SEGMENT 15 "Sensor error" 14 "Reserved" 13 "Reserved" 12 "Reserved" 11 "Reserved" 10 "Reserved" 9 "Reserved" 8 "Reserved" 7 "Reserved" 6 "Display 6 Segment" 5 "Display 5 Segment" 4 "Display 4 Segment" 3 "Display 3 Segment" 2 "Display 2 Segment" 1 "Display 1 Segment" 0 "Default / No Display Segment" ;
VAL_ 929 FLS_SEG_WARN 1 "Warning" 0 "No Warning/Default" ;
VAL_ 929 FRS_SEGMENT 15 "Sensor error" 14 "Reserved" 13 "Reserved" 12 "Reserved" 11 "Reserved" 10 "Reserved" 9 "Reserved" 8 "Reserved" 7 "Reserved" 6 "Display 6 Segment" 5 "Display 5 Segment" 4 "Display 4 Segment" 3 "Display 3 Segment" 2 "Display 2 Segment" 1 "Display 1 Segment" 0 "Default / No Display Segment" ;
VAL_ 929 FRMS_SEG_WARN 1 "Warning" 0 "No Warning/Default" ;
VAL_ 929 RLS_SEGMENT 15 "Sensor error" 14 "Reserved" 13 "Reserved" 12 "Reserved" 11 "Reserved" 10 "Reserved" 9 "Reserved" 8 "Reserved" 7 "Reserved" 6 "Display 6 Segment" 5 "Display 5 Segment" 4 "Display 4 Segment" 3 "Display 3 Segment" 2 "Display 2 Segment" 1 "Display 1 Segment" 0 "Default / No Display Segment" ;
VAL_ 929 FLMS_SEGMENT 15 "Sensor error" 14 "Reserved" 13 "Reserved" 12 "Reserved" 11 "Reserved" 10 "Reserved" 9 "Reserved" 8 "Reserved" 7 "Reserved" 6 "Display 6 Segment" 5 "Display 5 Segment" 4 "Display 4 Segment" 3 "Display 3 Segment" 2 "Display 2 Segment" 1 "Display 1 Segment" 0 "Default / No Display Segment" ;
VAL_ 1653 STS_CODE_FOTA 19 "Write Data Failed" 11 "ECU Re-Programming Completed" 10 "Metadata Download failed" 9 "SecAccess to target ECU fail" 8 "BattVolt Pre-Condition Not Met" 7 "EngSpd Pre-Condition Not Met" 6 "VehSpd Pre-Condition Not Met" 5 "ReProgram of targt ECU in Prog" 4 "Update Download frm Tele in Prog" 3 "Gateway Memory Full" 2 "Update Download to Gateway Fail" 1 "ECU Re-Programming Failed" 0 "No Error / Idle/ DV" ;
VAL_ 1653 REQ_REPROG_FOTA 1 "Gateway Ready For reprog" 0 "GW Not Rdy for Reprog Update/DV" ;
VAL_ 1653 READY_UPDATE_DOWNLOAD_FOTA 1 "Gateway Ready for Update" 0 "GW not Ready for Rx Update/DV" ;
VAL_ 272 CUR_CARD_SHAFT_TRQ 2047 "Signal Invalid" 0 "Default Value" ;
VAL_ 272 TRANSFER_MODE_TC 3 "Signal Invalid" 2 "4WDL" 1 "4WDH" 0 "2WD/Default Value" ;
VAL_ 272 INDC_TC_MALF 1 "ON" 0 "OFF/Default" ;
VAL_ 272 INDC_TC_ALERT 7 "Reserved" 6 "Reserved" 5 "Reserved" 4 "Reserved" 3 "Stop-shift into park/neutral(AT)" 2 "Stop-shift to neutral gear(MT)" 1 "Reduce Vehicle Spd below 80km/h" 0 "Default/No Alert" ;
VAL_ 158 ICC_WAKEUP_REASON 2 "Rotary Encoder" 1 "Any Joystick Button Press" 0 "Any Button Press" ;
VAL_ 1583 ENG_OPERATION_MODE 15 "Unused" 14 "Unused" 13 "Unused" 12 "Unused" 11 "Unused" 10 "Unused" 9 "Unused" 8 "Unused" 7 "WrmUp" 6 "CldStrt" 5 "DeSOx" 4 "DeNOx" 3 "DeSOxHeat" 2 "PFlt_Rgn2" 1 "PFlt_Rgn1" 0 "Normal" ;
VAL_ 1581 DPF_HIGH_FUEL_OIL_DILUTION 3 "Reserved" 2 "Red" 1 "Yellow" 0 "Green / Default" ;
VAL_ 1581 CAL_LOAD 255 "Signal invalid" 0 "Default vaue" ;
VAL_ 1413 FUEL_INJECTOR_DRIFT_PRED_INJ4 3 "Reserved" 2 "High Drift" 1 "Moderate Drift" 0 "No Drift / Default" ;
VAL_ 1413 FUEL_INJECTOR_DRIFT_PRED_INJ3 3 "Reserved" 2 "High Drift" 1 "Moderate Drift" 0 "No Drift / Default" ;
VAL_ 1413 FUEL_INJECTOR_DRIFT_PRED_INJ2 3 "Reserved" 2 "High Drift" 1 "Moderate Drift" 0 "No Drift / Default" ;
VAL_ 1413 FUEL_INJECTOR_DRIFT_PRED_INJ1 3 "Reserved" 2 "High Drift" 1 "Moderate Drift" 0 "No Drift / Default" ;
VAL_ 1413 STS_ADAPTV_SPEED_CNTRL_MODE 1 "Adaptive Speed Control " 0 "Normal Mode /Default value" ;
VAL_ 1413 ADAPTIVE_SPD_EMS_FB 7 "Speed 7" 6 "Speed 6" 5 "Speed 5" 4 "Speed 4" 3 "Speed 3" 2 "Speed 2" 1 "Speed 1" 0 "Default/Normal" ;
VAL_ 1413 DRV_MODE_CUSTOM1 1 "Custom Mode ON" 0 "Custom Mode OFF/DV" ;
VAL_ 1413 ENG_OIL_TEMP 0 "Default Value" 255 "Invalid value" ;
VAL_ 1413 ENG_OIL_PRESSURE_VAL 31 "Signal Invalid" 0 "Default" ;
VAL_ 581 OBC_DCOutputVoltage 16383 "Signal Invalid" 0 "Default Value" ;
VAL_ 581 OBC_DCOutputCurrent 4095 "Signal invalid" 0 "Default Value" ;
VAL_ 581 OBC_ACInputVoltageRMS 4095 "Signal Invalid" 0 "Default value" ;
VAL_ 581 OBC_ACInputCurrentRMS 16383 "Signal Invalid" 0 "Default Value" ;
VAL_ 274 VCU_MsgSt 6 "Timeout" 5 "ResponseReceived" 4 "TransmissionConfirmed" 3 "RequestSent" 2 "StreamingRequest" 1 "WaitForNextRequest" 0 "None" ;
VAL_ 274 VCU_ErrStack 14 "SLAC" 13 "Reserved" 12 "Reserved" 11 "NvM Error" 10 "NegativeResponseCode" 9 "InvalidRxParameter" 8 "InvalidRxMessage" 7 "Crypto Error" 6 "XmlSecurity" 5 "Exi Error" 4 "IpBase Error" 3 "Timeout" 2 "InvalidTxParameter" 1 "Transport Layer Error" 0 "NoError" ;
VAL_ 274 VCU_Isolt_mtr_stp_req 1 "Stop monitoring" 0 "Monitoring" ;
VAL_ 274 VCU_VehicleState 7 "Signal Invalid" 6 "Reserved" 5 "Reserved" 4 "Invalid" 3 "Charging" 2 "Running" 1 "SoftStart" 0 "Stopped/Default" ;
VAL_ 274 VCU_TorqueCommand 0 "Default Value" ;
VAL_ 274 VCU_OperationReq 7 "Invalid Req" 6 "Reserved" 5 "Reserved" 4 "Reserved" 3 "Reserved" 2 "ShutdownReq" 1 "OperationReq" 0 "StandybyReq/Default" ;
VAL_ 274 VCU_OperationalModeCmd 7 "Signal Invalid" 6 "Reserved" 5 "Reserved" 2 "Reserved" 4 "Reserved" 3 "Ev" 1 "Reserved" 0 "Neutral/Default" ;
VAL_ 274 VCU_CommandMode 3 "Signal Invalid" 2 "Reserved" 1 "Speed Mode" 0 "Default/Torque Mode" ;
VAL_ 274 VCU112_COUNTER 0 "Default Value" ;
VAL_ 274 VCU112_Checksum 0 "Default Value" ;
VAL_ 274 VCU_ACTV_Discharge_REQ 1 "Request" 0 "No Request" ;
VAL_ 819 VCU_HVDisconnect_Reasons 4 "Cabin Heater HV DC Input Not Ok" 3 "ACComp/HVBat Htr HVDC InputNotOk" 2 "LDC/OBC HV DC Input Not Ok" 1 "MCU HV Not Ok" 0 "Default" ;
VAL_ 819 VCU_Gear_Actual 7 "Signal Invalid" 6 "Reserved" 5 "Park Mode" 4 "Reserved" 3 "Low Mode" 2 "Reverse Mode" 1 "Forward Mode" 0 "Neutral Mode/ Default" ;
VAL_ 819 VCU_CmdACPWM 0 "Default Value" 255 "Signal Invalid" ;
VAL_ 819 VCU_CmdACCP 7 "Signal Invalid" 6 "Reserved" 5 "Reserved" 4 "Stage F(-12)" 3 "Stage D(3V)" 2 "Stage C(6V)" 1 "Stage B(9V)" 0 "Stage A(0V)/Default" ;
VAL_ 819 VCU_VehChargeModeSta 7 "Signal Invalid" 6 "Reserved" 5 "Reserved" 4 "12V Battery Auto Charging Mode" 3 "Quick(DC) Charging Mode" 2 "Reserved" 1 "Normal(AC) Charging Mode" 0 "Standby/Default" ;
VAL_ 819 VCU_PP_CurrentLimit 255 "Signal Invalid" ;
VAL_ 821 VCU_HVConnect_Sta 3 "Signal Invalid" 2 "HV Disconnected" 1 "HV Connected" 0 "Default" ;
VAL_ 821 VCU_ChargingPlugSta 3 "Signal Invalid" 2 "DC Plug Connected" 1 "AC Plug Connected" 0 "DisConnected/Default" ;
VAL_ 821 VCU_DISP_AMBT_TEMP_FATC 65 "Default Value" 255 "Invalid Value" ;
VAL_ 821 VCU_HVACHeatingSta 3 "Signal Invalid" 2 "Reserved" 1 "ON" 0 "OFF/Default" ;
VAL_ 821 VCU_HVACCoolingSta 3 "Signal Invalid" 2 "Reserved" 1 "ON" 0 "OFF/Default" ;
VAL_ 821 VCU_HVACCoolingPower 1023 "Signal Invalid" 0 "Default" ;
VAL_ 821 VCU_ActiveDampingDisableCommand 3 "Invalid Request" 2 "Reserved" 1 "Request" 0 "No Request" ;
VAL_ 577 VCU_ExMeDi_IdxDcChrgnErr 10 "SCC_StackError" 9 "Active battery charging stop request" 8 "Inlet temperature exceeded indicator" 7 "Current set-point error after delay" 6 "Voltage set-point error after delay" 5 "EVCE_DataInconsistencyError" 4 "Timeout indicator for the charging session" 3 "Battery statusTriggered emergencyPowerdown" 2 "reportedstatusofEVSE triggered critical error." 1 "Ext Mean Diagn ErrorStateMachineCritical" 0 "Ext Mean Diagn ErrorStateMachineStatus" ;
VAL_ 577 VCU_RespCod 23 "FAILED_MeteringSignatureNotValid" 22 "FAILED_PowerDeliveryNotApplied" 21 "FAILED_EVSEPresentVoltageToLow" 20 "FAILED_TariffSelectionInvalid" 19 "FAILED_ChargingProfileInvalid" 18 "FAILED_WrongChargeParameter" 17 "FAILED_WrongEnergyTransferType" 16 "FAILED_ChallengeInvalid" 15 "FAILED_ContractCanceled" 14 "FAILED_CertChainError" 13 "FAILED_NoCertificateAvailable" 12 "FAILED_CertificateExpired" 11 "FAILED_ServiceSelectionInvalid" 10 "FAILED_PaymentSelectionInvalid" 9 "FAILED_ServiceIDInvalid" 8 "FAILED_UnknownSession" 7 "FAILED_SignatureError" 6 " FAILED_SequenceError" 5 "FAILED" 4 "OK_OldSessionJoined" 3 "OK_NewSessionEstablished" 2 "OK_CertificateExpiresSoon" 1 "OK" 0 "None" ;
VAL_ 577 VCU_MsgSts 32 "SLAC Failed" 31 "SLAC OK" 30 "Close communication Failed

" 29 "Close communication OK" 28 "SessionStop Failed

" 27 "SessionStop OK" 26 "WeldingDetection Failed

" 25 "WeldingDetection OK" 24 "CurrentDemand Failed" 23 "CurrentDemand OK" 22 "PowerDelivery Failed

" 21 "PowerDelivery OK" 20 "Precharge Failed" 19 " Precharge OK

" 18 "CableCheckFailed

" 17 "CableCheck OK" 16 "ChargeParameterDiscovery Failed" 15 "ChargeParameterDiscovery OK

" 14 "ContractAuthentication Failed" 13 "ContractAuthentication OK" 12 "ServicePaymentSelection Failed" 11 "ServicePaymentSelection OK" 10 " ServiceDiscovery Failed" 9 "ServiceDiscovery OK

" 8 "SessionSetup Failed" 7 "SessionSetup OK

" 6 "SupportedAppProtocol Failed" 5 "SupportedAppProtocol OK" 4 "TCP Failed" 3 "TCP OK" 2 "SDP Failed" 1 "SDP OK" 0 "None" ;
VAL_ 577 VCU_Charge_Discharge_Trans 3 "Signal Invalid" 2 "Charge to Discharge" 1 "Discharge to charge" 0 "Default" ;
VAL_ 577 VCU_TransPmotorparkReq 3 "InValid" 2 "Park Request" 1 "Unpark Request" 0 "NoRequest/Default" ;
VAL_ 577 VCU_eComp_HVIL_Status 3 "Signal Invalid" 2 "Reserved" 1 "Open/Fault" 0 "Closed/No Fault" ;
VAL_ 577 VCU241_Checksum 0 "Default Value" ;
VAL_ 577 VCU241_COUNTER 0 "Default Value" ;
VAL_ 577 VCU_SRSCrashSta 0 "No Request Default Value" 1 "Crash / Request to STOP" ;
VAL_ 822 VCU_AUX_BATTERY_VOLT 255 "Signal Invalid" 0 "Default value" ;
VAL_ 822 VCU_Vehicle_Speed 65535 "Signal Invalid" 0 "Default" ;
VAL_ 822 VCU_STS_IGN 7 "Signal Invalid" 6 "Reserved" 5 "Reserved" 4 "Reserved" 3 "Ignition KL 15/Default value" 2 "Reserved" 1 "Reserved" 0 "Reserved" ;
VAL_ 822 VCU_EPTCoolantTemp 70 "Default Value" 255 "Signal Invalid" ;
VAL_ 822 VCU_EPTCoolantFlow 0 "Default Value" ;
VAL_ 822 VCU_EVReady 3 "Signal Invalid" 2 "Emergency (Blinking)" 1 "Ready" 0 "Not Ready/Default" ;
VAL_ 437 VCU_BMS_ASW_SleepRequest 7 "Reserved" 6 "Reserved" 5 "Reserved" 4 "Reserved" 3 "Reserved" 2 "Reserved" 1 "Initiate Sleep" 0 "Deafult" ;
VAL_ 437 VCU_SmObc_State 0 "Default Value" ;
VAL_ 437 VCU_Wakeup_Reason_internal 15 "Invalid" 14 "Reserved" 13 "Reserved" 12 "Reserved" 11 "Reserved" 10 "Reserved" 9 "Reserved" 8 "Reserved" 7 "Reserved" 6 "DCAN" 5 "CAN Wakeup - VCAN" 4 "CAN Wakeup - EVCAN" 3 "Scheduled wakeup (AUX_UV_VOLT)" 2 "PP" 1 "IGN" 0 "No Wakeup" ;
VAL_ 437 VCU_NoSM_State 0 "Default Value" ;
VAL_ 437 VCU_EVCSI_State 0 "Default Value" ;
VAL_ 437 VCU_CharPD_RawVal 255 "Signl Invalid" ;
VAL_ 437 VCU_CharCP_RawVal 255 "Signl Invalid" ;
VAL_ 601 VCU_StsIslnEvse 3 " Fault" 2 "Warning" 1 "Valid" 0 "Invalid" ;
VAL_ 601 VCU_LV_Battery_Voltage 135 "Default Value" ;
VAL_ 601 VCU_brake2_voltage 0 "Default Value" ;
VAL_ 601 VCU_brake1_voltage 0 "Default Value" ;
VAL_ 601 VCU_Accep2_voltage 0 "Default Value" ;
VAL_ 601 VCU_Accep1_voltage 0 "Default Value" ;
VAL_ 1731 VCU_CharInletTempNeg 65 "Default Value" ;
VAL_ 1731 VCU_PumpSpdFb 127 "Signal Invalid" ;
VAL_ 1731 VCU_PumpSpdCtrl 127 "Signal Invalid" ;
VAL_ 1731 VCU_CoolFanSpdCtrl 127 "Signal Invalid" ;
VAL_ 1731 VCU_CharPlugLockFbSts 1 "Lock" 0 "Unlock" ;
VAL_ 1731 VCU_CharPlugLockCtrlSts 2 "Unlock" 1 "Lock" 0 "Hold" ;
VAL_ 1731 VCU_CharPlugAtLockSwIndSts 1 "ON" 0 "OFF" ;
VAL_ 1731 VCU_CharInletTempPos 65 "Default Value" ;
VAL_ 1481 VCU_COMFLT_MSG_CONTFAIL 3 "Reserved" 2 "MCF DTC Healed State" 1 "MCF DTC Current State" 0 "Default/No DTC" ;
VAL_ 1481 VCU_COMFLT_SGN_CONTFAIL 3 "Reserved" 2 "SCF DTC Healed State" 1 "SCF DTC Current State" 0 "Deault/No DTC" ;
VAL_ 1481 VCU_AUX_BATT_VOLT 0 "Default" ;
VAL_ 1481 VCU_UV_STS 1 "Active" 0 "Inactive/Default" ;
VAL_ 1481 VCU_STS_IGN_NM 1 "IGN on" 0 "IGN Off/Default" ;
VAL_ 1481 VCU_OV_STS 1 "Active" 0 "Inactive/Default" ;
VAL_ 1481 VCU_COMFLT_NODEABS_STS 3 "Reserved" 2 "NA DTC Healed State" 1 "NA DTC Current State" 0 "Default/no DTC" ;
VAL_ 1481 VCU_VARIANT_CODE_ERR_STS 3 "Reserved" 2 "VC DTC in Healed State" 1 "VC DTC in current state" 0 "Default" ;
VAL_ 1481 VCU_NM_ACTIVE_STS 7 "NM Active" 6 "Disabled due to IGN off" 5 "Disabled due to bus off" 4 "Disabled due to over voltage" 3 "Disabled due to under voltage" 2 "Disabled due to Cranking T50/ESS" 1 "Disabled due to VC" 0 "Diabled due to IGN On/Default" ;
VAL_ 1481 VCU_FEATURE_CODE_ERR_STS 3 "Reserved" 2 "FC DTC in Healed State" 1 "FC DTC in current state" 0 "Default" ;
VAL_ 1481 VCU_COMFLT_MSGTOUT_STS 3 "Reserved" 2 "MTO DTC in Healed State" 1 "MTO DTC in current state" 0 "Default/No DTC" ;
VAL_ 988 OBC_VIN_MISMATCH_FAULT 1 "Fault" 0 "No Fault/Default" ;
VAL_ 988 OBC_ECU_RESET_FAULT 1 "Fault" 0 "No Fault/Default" ;
VAL_ 988 OBC_Low_Temp_Shutdown 1 "Fault" 0 "Default/No fault" ;
VAL_ 988 OBC_HVDC_HW_OV 1 "Fault" 0 "Default/No fault" ;
VAL_ 988 OBC_CPVol_Out_of_Range 1 "Fault" 0 "Default/No fault" ;
VAL_ 988 OBC_CPDuty_Out_of_Range 1 "Fault" 0 "Default/No fault" ;
VAL_ 988 OBC_HVDC_HW_OC 1 "Fault" 0 "Default/No fault" ;
VAL_ 988 OBC_PRECHARGE_FAULT_CNT 7 "Signal Invalid" 0 "Default" ;
VAL_ 988 OBC_PFC_BUS_FAULT_CNT 7 "Signal Invalid" 0 "Default" ;
VAL_ 988 OBC_PFC_VOLT_CNTRL_IP 255 "Signal Invalid" 0 "Default" ;
VAL_ 988 OBC_LIne_OC_SW 1 "Fault" 0 "Default/ No fault" ;
VAL_ 988 OBC_VPROG_OUT_OF_RANGE 1 "Fault/Warning" 0 "Default/No Fault" ;
VAL_ 988 OBC_TEMP_SENSOR_FAIL 1 "Fault/Warning" 0 "Default/No Fault" ;
VAL_ 988 OBC_OVER_TEMP 1 "Fault/Warning" 0 "Default/No Fault" ;
VAL_ 988 OBC_INTERNAL_FAIL 1 "Fault/Warning" 0 "Default/No Fault" ;
VAL_ 988 OBC_HIGH_TEMP 1 "Fault/Warning" 0 "Default/No Fault" ;
VAL_ 988 OBC_IPROG_OUT_OF_RANGE 1 "Fault/Warning" 0 "Default/No Fault" ;
VAL_ 988 OBC_EMI_IP_UV 1 "Fault/Warning" 0 "Default/No Fault" ;
VAL_ 988 OBC_EMI_IP_OV 1 "Fault/Warning" 0 "Default/No Fault" ;
VAL_ 988 OBC_EEPROM_FAIL 1 "Fault/Warning" 0 "Default/No Fault" ;
VAL_ 988 OBC_CAN_BUS_OFF 1 "Fault/Warning" 0 "Default/No Fault" ;
VAL_ 988 OBC_TEMP_DERATE 1 "Fault/Warning" 0 "Default/No Fault" ;
VAL_ 988 OBC_PRE_CHARGE_FAULT 1 "Fault/Warning" 0 "Default/No Fault" ;
VAL_ 988 OBC_PFV_OV 1 "Fault/Warning" 0 "Default/No Fault" ;
VAL_ 988 OBC_PFC_UV 1 "Fault/Warning" 0 "Default/No Fault" ;
VAL_ 988 OBC_PFC_OVER_TEMP 1 "Fault/Warning" 0 "Default/No Fault" ;
VAL_ 988 OBC_OP_UV 1 "Fault/Warning" 0 "Default/No Fault" ;
VAL_ 988 OBC_OP_OV 1 "Fault/Warning" 0 "Default/No Fault" ;
VAL_ 988 OBC_OP_OC 1 "Fault/Warning" 0 "Default/No Fault" ;
VAL_ 988 OBC_LV_UNDER_VOLT 1 "Fault/Warning" 0 "Default/No Fault" ;
VAL_ 988 OBC_LV_OVER_VOLT 1 "Fault/Warning" 0 "Default/No Fault" ;
VAL_ 988 OBC_LLC_OVER_TEMP 1 "Fault/Warning" 0 "Default/No Fault" ;
VAL_ 988 OBC_IP_UNDER_VOLT 1 "Fault/Warning" 0 "Default/No Fault" ;
VAL_ 988 OBC_IP_OVER_VOLT 1 "Fault/Warning" 0 "Default/No Fault" ;
VAL_ 988 OBC_IP_OVER_CURR 1 "Fault/Warning" 0 "Default/No Fault" ;
VAL_ 988 OBC_IP_DERATE 1 "Fault/Warning" 0 "Default/No Fault" ;
VAL_ 1480 OBC_COMFLT_SGN_CONTFAIL 3 "Reserved" 2 "SCF DTC Healed State" 1 "SCF DTC Current State" 0 "Deault/No DTC" ;
VAL_ 1480 OBC_UV_STS 1 "Active" 0 "Inactive/Default" ;
VAL_ 1480 OBC_STS_IGN_NM 1 "IGN on" 0 "IGN Off/Default" ;
VAL_ 1480 OBC_OV_STS 1 "Active" 0 "Inactive/Default" ;
VAL_ 1480 OBC_AUX_BATT_VOLT 0 "Default" ;
VAL_ 1480 OBC_COMFLT_MSG_CONTFAIL 3 "Reserved" 2 "MCF DTC Healed State" 1 "MCF DTC Current State" 0 "Default/No DTC" ;
VAL_ 1480 OBC_COMFLT_NODEABS_STS 3 "Reserved" 2 "NA DTC Healed State" 1 "NA DTC Current State" 0 "Default/no DTC" ;
VAL_ 1480 OBC_NM_ACTIVE_STS 7 "NM ACTIVE" 6 "Disabled due to IGN off" 5 "Disabled due to bus off" 4 "Disabled due to over voltage" 3 "Disabled due to under voltage" 2 "Disabled due to Cranking T50/ESS" 1 "Disabled due to VC" 0 "Diabled due to IGN On/Default" ;
VAL_ 1480 OBC_VARIANT_CODE_ERR_STS 3 "Reserved" 2 "VC DTC in Healed State" 1 "VC DTC in current state" 0 "Default" ;
VAL_ 1480 OBC_FEATURE_CODE_ERR_STS 3 "Reserved" 2 "FC DTC in Healed State" 1 "FC DTC in current state" 0 "Default" ;
VAL_ 1480 OBC_COMFLT_MSGTOUT_STS 3 "Reserved" 2 "MTO DTC in Healed State" 1 "MTO DTC in current state" 0 "Default/No DTC" ;
VAL_ 983 MCU_MotorCoolingFlowReq 255 "Default value" ;
VAL_ 983 MCU_Motor_Temp_Indicator 255 "Default Value" ;
VAL_ 983 MCU_Inverter_Temp_Indicator 255 "Default Value" ;
VAL_ 983 MCU_Inverter_CoolingFlowReq 0 "Default Value" 255 "Signal Invalid" ;
VAL_ 280 MCU118_COUNTER 0 "Default Value" ;
VAL_ 280 MCU118_Checksum 0 "Default Value" ;
VAL_ 280 MCU_MotorSpeed 65535 "Default Value" ;
VAL_ 280 MCU_MotorTorqueEstimated 65535 "Default Value" ;
VAL_ 824 VCU_CmdACChargeTargetVolt 16383 "Signal Invalid" 0 "Default Value" ;
VAL_ 824 VCU_CmdEnableOBC 3 "Invalid" 2 "Reserved" 1 "Enable" 0 "Disable / Initial Value/Default" ;
VAL_ 824 VCU_CmdACChargeTargetCurrent 4095 "Signal Invalid" 0 "Default Value" ;
VAL_ 824 VCU_ACChargingReady 3 "Signal Invalid" 2 "Charging Finish" 1 "Ready" 0 "NotReady/Default" ;
VAL_ 1736 VCU_EConsDistSample4 65535 "Invalid" 0 "Default" ;
VAL_ 1736 VCU_EConsDistSample3 65535 "Invalid" 0 "Default" ;
VAL_ 1736 VCU_EConsDistSample2 65535 "Invalid" 0 "Default" ;
VAL_ 1736 VCU_EConsDistSample1 65535 "Invalid" 0 "Default" ;
VAL_ 1012 VCU_DcChargingSequence 8 "TCP Disconnected" 7 "Session Stop" 6 "Welding Detection" 5 "Charging" 4 "Precharge" 3 "Cable Check" 2 "Initialization" 1 "Connecte" 0 "Disconnected" ;
VAL_ 1012 VCU_SBWS_BuFb_RawVal 127 "Signal Invalid" ;
VAL_ 1012 VCU_SBWS_Bu_RawVal 127 "Signal Invalid" ;
VAL_ 1012 VCU_PumpRlyCtrlSts 1 "ON" 0 "OFF" ;
VAL_ 1006 VCU_QkCharPosRlyFblSts 1 "ON" 0 "OFF" ;
VAL_ 1006 VCU_QkCharPosRlyCtrlSts 1 "ON" 0 "OFF" ;
VAL_ 1006 VCU_QkCharNegRlyFblSts 1 "ON" 0 "OFF" ;
VAL_ 1006 VCU_QkCharNegRlyCtrlSts 1 "ON" 0 "OFF" ;
VAL_ 1006 VCU_CharIndRedCtrlSts 127 "Signal Invalid" ;
VAL_ 1006 VCU_CharIndGrCtrlSts 127 "Signal Invalid" ;
VAL_ 1006 VCU_CharIndBlCtrlSts 127 "Signal Invalid" ;
VAL_ 984 OBC_PFC_Voltage 65535 "Signal invalid" 0 "Default Value" ;
VAL_ 984 OBC_DCVoltageCapable 65535 "Default Value" ;
VAL_ 984 OBC_DCCurrentCapable 65535 "Default Value" ;
VAL_ 1064 OBC_PowerDeratingSta 7 "Signal Invalid" 6 "Reserved" 5 "Reserved" 4 "Reserved" 3 "Reserved" 2 "Power Derating-Input Voltage" 1 "Power Derating-Temperature" 0 "No Power Derating/Default" ;
VAL_ 1064 OBC_OperatingMode 7 "Reserved" 6 "Reserved" 5 "Fault" 4 "Power Derated" 3 "Charging" 2 "Ready / No Charge" 1 "Wake up" 0 "Init Mode/Default" ;
VAL_ 1064 OBC_ACDetectSta 1 "Yes" 0 "No/Default" ;
VAL_ 986 OBC_SecondarySide_Temperature 4095 "Signal Invalid" 820 "Default Value" ;
VAL_ 986 OBC_Transformer_Temperature 4095 "Signal Invalid" 820 "Default Value" ;
VAL_ 986 OBC_CoolingRequest 0 "Default" 255 "Signal Invalid" ;
VAL_ 986 OBC_PrimarySide_Temperature 4095 "Signal Invalid" 820 "Default" ;
VAL_ 986 OBC_LV_PwrSupply 32767 "Signal Invalid" 0 "Default Value" ;
VAL_ 1479 MCU_SW_Version_Internal 0 "Default" ;
VAL_ 1479 MCU_COMFLT_SGN_CONTFAIL 3 "Reserved" 2 "SCF DTC Healed State" 1 "SCF DTC Current State" 0 "Deault/No DTC" ;
VAL_ 1479 MCU_OV_STS 1 "Active" 0 "Inactive/Default" ;
VAL_ 1479 MCU_UV_STS 1 "Active" 0 "Inactive/Default" ;
VAL_ 1479 MCU_STS_IGN 1 "IGN on" 0 "IGN Off/Default" ;
VAL_ 1479 MCU_AUX_BATT_VOLT 0 "Default" ;
VAL_ 1479 MCU_COMFLT_MSG_CONTFAIL 3 "Reserved" 2 "MCF DTC Healed State" 1 "MCF DTC Current State" 0 "Default/No DTC" ;
VAL_ 1479 MCU_NM_ACTIVE_STS 7 "NM Active" 6 "Disabled due to IGN off" 5 "Disabled due to bus off" 4 "Disabled due to over voltage" 3 "Disabled due to under voltage" 2 "Disabled due to Cranking T50/ESS" 1 "Disabled due to VC" 0 "Diabled due to IGN On/Default" ;
VAL_ 1479 MCU_COMFLT_NODEABS_STS 3 "Reserved" 2 "NA DTC Healed State" 1 "NA DTC Current State" 0 "Default/no DTC" ;
VAL_ 1479 MCU_COMFLT_MSGTOUT_STS 3 "Reserved" 2 "MTO DTC in Healed State" 1 "MTO DTC in current state" 0 "Default/No DTC" ;
VAL_ 283 MCU11B_Checksum 0 "Default Value" ;
VAL_ 283 MCU11B_COUNTER 0 "Default Value" ;
VAL_ 283 MCU_ErrorLevel 7 "Invalid" 6 "Reserved" 5 "Lv5" 4 "Lv4" 3 "Lv3" 2 "Lv2" 1 "Lv1" 0 "Lv0 " ;
VAL_ 283 MCU_ActiveDamping 3 "Signal Invalid" 2 "Reserved" 1 "Off" 0 "On/Default" ;
VAL_ 283 MCU_OperationalMode 7 "Signal Invalid" 6 "Reserved" 5 "Reserved" 4 "Reserved" 3 "EV" 2 "Reserved" 1 "Reserved" 0 "Neutral/Default" ;
VAL_ 283 MCU_CommandMode 7 "Invalid Value" 6 "Reserved" 5 "Reserved" 4 "Reserved" 3 "Reserved" 2 "Reserved" 1 "Speed Mode" 0 "Torque Mode/Default" ;
VAL_ 283 MCU_State 15 "Invalid Value" 14 "Reserved" 13 "Reserved" 12 "Reserved" 11 "Reserved" 10 "Reserved" 9 "Reserved" 8 "Reserved" 7 "ReadyToShutdown" 6 "Reserved" 5 "Failure" 4 "Operational" 3 "Reserved" 2 "Reserved" 1 "Standby" 0 "Initialization" ;
VAL_ 283 MCU_ACTV_Discharge_STS 4 "Signal Invalid" 3 "ACT_DIS_complete_without_error" 2 "ACT_DIS_Unsuccessful_with_error" 1 "ACT_DIS_Initiated" 0 "Default" ;
VAL_ 283 MCU_ACTV_Discharge_FAIL 1 "Fail" 0 "No Fail" ;
VAL_ 982 MCU_HighPowerCurrent 2047 "Signal Invallid" 0 "Default Value" ;
VAL_ 982 MCU_HighPowerVoltage 2047 "Default Value" ;
VAL_ 982 MCU_TractionTorqueAvail_quasi 32767 "Default Value" ;
VAL_ 982 MCU_RegenTorqueAvail_quasi 32767 "Default Value" ;
VAL_ 1478 LDC_COMFLT_SGN_CONTFAIL 3 "Reserved" 2 "SCF DTC Healed State" 1 "SCF DTC Current State" 0 "Deault/No DTC" ;
VAL_ 1478 LDC_UV_STS 1 "Active" 0 "Inactive/Default" ;
VAL_ 1478 LDC_OV_STS 1 "Active" 0 "Inactive/Default" ;
VAL_ 1478 LDC_STS_IGN_NM 1 "IGN on" 0 "IGN Off/Default" ;
VAL_ 1478 LDC_AUX_BATT_VOLT 0 "Default" ;
VAL_ 1478 LDC_COMFLT_MSG_CONTFAIL 3 "Reserved" 2 "MCF DTC Healed State" 1 "MCF DTC Current State" 0 "Default/No DTC" ;
VAL_ 1478 LDC_COMFLT_NODEABS_STS 3 "Reserved" 2 "NA DTC Healed State" 1 "NA DTC Current State" 0 "Default/no DTC" ;
VAL_ 1478 LDC_VARIANT_CODE_ERR_STS 3 "Reserved" 2 "VC DTC in Healed State" 1 "VC DTC in current state" 0 "Default" ;
VAL_ 1478 LDC_NM_ACTIVE_STS 7 "NM Active" 6 "Disabled due to IGN off" 5 "Disabled due to bus off" 4 "Disabled due to over voltage" 3 "Disabled due to under voltage" 2 "Disabled due to Cranking T50/ESS" 1 "Disabled due to VC" 0 "Diabled due to IGN On/Default" ;
VAL_ 1478 LDC_FEATURE_CODE_ERR_STS 3 "Reserved" 2 "FC DTC in Healed State" 1 "FC DTC in current state" 0 "Default" ;
VAL_ 1478 LDC_COMFLT_MSGTOUT_STS 3 "Reserved" 2 "MTO DTC in Healed State" 1 "MTO DTC in current state" 0 "Default/No DTC" ;
VAL_ 1477 ETL_COMFLT_SGN_CONTFAIL 3 "Reserved" 2 "SCF DTC Healed State" 1 "SCF DTC Current State" 0 "Deault/No DTC" ;
VAL_ 1477 ETL_OV_STS 1 "Active" 0 "Inactive/Default" ;
VAL_ 1477 ETL_UV_STS 1 "Active" 0 "Inactive/Default" ;
VAL_ 1477 ETL_STS_IGN 1 "IGN on" 0 "IGN Off/Default" ;
VAL_ 1477 ETL_AUX_BATT_VOLT 0 "Default" ;
VAL_ 1477 ETL_COMFLT_MSG_CONTFAIL 3 "Reserved" 2 "MCF DTC Healed State" 1 "MCF DTC Current State" 0 "Default/No DTC" ;
VAL_ 1477 ETL_COMFLT_NODEABS_STS 3 "Reserved" 2 "NA DTC Healed State" 1 "NA DTC Current State" 0 "Default/no DTC" ;
VAL_ 1477 ETL_COMFLT_MSGTOUT_STS 3 "Reserved" 2 "MTO DTC in Healed State" 1 "MTO DTC in current state" 0 "Default/No DTC" ;
VAL_ 578 ETL_Shifting_In_Progress 1 "Shifting" 0 "Not Shifting" ;
VAL_ 578 ETL_Service_WRN_IND 1 "ON" 0 "OFF" ;
VAL_ 578 ETL_Pmotor_Position_Failure 1 "Fault" 0 "No Fault" ;
VAL_ 578 ETL_PmotorPositionStatus 3 "Invalid" 2 "In Between" 1 "N" 0 "P" ;
VAL_ 578 ETL_PmotorErrorLevel 15 "Invalid" 14 "Reserved" 13 "Reserved" 12 "Reserved" 11 "Reserved" 10 "Reserved" 9 "Reserved" 8 "Reserved" 7 "Reserved" 6 "Reserved" 5 "Error Level 5" 4 "Error Level 4" 3 "Error Level 3" 2 "Error Level 2" 1 "Error Level 1" 0 "Error Level 0" ;
VAL_ 578 ETL_OperationMode 4 "Error" 3 "Ready" 2 "Reserved" 1 "Standby (Low Power Mode)" 0 "Sleep/Default" ;
VAL_ 1475 BMS_STS_IGN_NM 1 "IGN on" 0 "IGN Off/Default" ;
VAL_ 1475 BMS_COMFLT_SGN_CONTFAIL 3 "Reserved" 2 "SCF DTC Healed State" 1 "SCF DTC Current State" 0 "Deault/No DTC" ;
VAL_ 1475 BMS_UV_STS 1 "Active" 0 "Inactive/Default" ;
VAL_ 1475 BMS_OV_STS 1 "Active" 0 "Inactive/Default" ;
VAL_ 1475 BMS_AUX_BATT_VOLT 0 "Default" ;
VAL_ 1475 BMS_COMFLT_MSG_CONTFAIL 3 "Reserved" 2 "MCF DTC Healed State" 1 "MCF DTC Current State" 0 "Default/No DTC" ;
VAL_ 1475 BMS_COMFLT_NODEABS_STS 3 "Reserved" 2 "NA DTC Healed State" 1 "NA DTC Current State" 0 "Default/no DTC" ;
VAL_ 1475 BMS_VARIANT_CODE_ERR_STS 3 "Reserved" 2 "VC DTC in Healed State" 1 "VC DTC in current state" 0 "Default" ;
VAL_ 1475 BMS_NM_ACTIVE_STS 7 "NM Active" 6 "Disabled due to IGN off" 5 "Disabled due to bus off" 4 "Disabled due to over voltage" 3 "Disabled due to under voltage" 2 "Disabled due to Cranking T50/ESS" 1 "Disabled due to VC" 0 "Diabled due to IGN On/Default" ;
VAL_ 1475 BMS_FEATURE_CODE_ERR_STS 3 "Reserved" 2 "FC DTC in Healed State" 1 "FC DTC in current state" 0 "Default" ;
VAL_ 1475 BMS_COMFLT_MSGTOUT_STS 3 "Reserved" 2 "MTO DTC in Healed State" 1 "MTO DTC in current state" 0 "Default/No DTC" ;
VAL_ 1002 BMS_Regen_AH 65535 "SIGNAL INVALID" 0 "NO FAULT/DEFAULT VALUE" ;
VAL_ 1002 BMS_KiloWattHour 1 "SIGNAL INVALID" 0 "NO FAULT/DEFAULT" ;
VAL_ 1002 BMS_AmpereHour 65535 "SIGNAL INVALID" 0 "NO FAULT/ DEFAULT VALUE" ;
VAL_ 980 BMS_Batt_Overcurrent_Sta 3 "Signal Invalid" 2 "Reserved" 1 "Overcurrent" 0 "No Overcurrent/Default" ;
VAL_ 980 BMS_DischargePowerAvailable_2 0 "Default Value" 4095 "Signal Invalid" ;
VAL_ 980 BMS_DischargePowerAvailable_10 0 "Default value" 4095 "Signal Invalid" ;
VAL_ 980 BMS_BatteryPackSOE 0 "Default Value" 1023 "Signal Invalid" ;
VAL_ 978 BMS_BHeaterFlt 32 "Reserved" 31 "Reserved" 30 "Reserved" 29 "Reserved" 28 "Reserved" 27 "Reserved" 26 "Reserved" 25 "Reserved" 24 "Reserved" 23 "Reserved" 22 "Reserved" 21 "Reserved" 20 "Reserved" 19 "CLT_SoftwareVersion_Num" 18 "CLT_Fail_IGBTDriverIC" 17 "CLT_Fail_IGBTShort" 16 "CLT_Fail_IGBTOpen" 15 "CLT_Fail_PCBTempSen" 14 "CLT_Fail_OutletTempSen" 13 "CLT_FailHVCurSen" 12 "CLT_FailHVSen" 11 "CLT_Fail_LVSen" 10 "CLT_Fault_LotCtrlMsg" 9 "CLT_Fault_PCBTempOver" 8 "CLT_Fault_OutletTempOver" 7 "CLT_Fault_HVOverCurr" 6 "CLT_Fault_HVOver" 5 "CLT_Fault_HVUnder" 4 "CLT_Fault_LVOver" 3 "CLT_Fault_LVUnder" 2 "CLT_LIN_Com_Err_Flag" 1 "CLT_Fault_Flag" 0 "No Fault/Default" ;
VAL_ 978 BMS_BHeaterOpCoolantTemp 680 "Default Value" 4095 "Signal Invalid" ;
VAL_ 978 BMS_CoolingHeatingSta 7 "Signal Invalid" 6 "Reserved" 5 "Reserved" 4 "Rinsing" 3 "Error" 2 "ON Heating" 1 "ON Cooling" 0 "OFF/Default" ;
VAL_ 978 BMS_ChillerSoleniodSta 3 "Signal Invalid" 2 "Reserved" 1 "ON" 0 "OFF/Default" ;
VAL_ 978 BMS_BatteryPreconditioningSta 3 "Signal Invalid" 2 "HighTempPreCondition ON" 1 "LowTempPreCondition ON" 0 "PreCondition OFF/Default" ;
VAL_ 978 BMS_BatteryOutletCoolantTemp 680 "Default Value" 4095 "Signal Invalid" ;
VAL_ 978 BMS_BatteryInletCoolantTempReq 680 "Default Value" 4095 "Signal Invalid" ;
VAL_ 978 BMS_BatteryInletCoolantTemp 680 "Default value" 4095 "Signal Invalid" ;
VAL_ 626 BMS_BatteryTBatt 680 "Default Value" 4095 "Signal Invalid" ;
VAL_ 626 BMS_BatteryPackVoltage 16383 "Signal Invalid" 0 "Default Value" ;
VAL_ 626 BMS_DisconnectByBMS 1 "Disconnect by BMS overriding VCU" 0 "Default/No Disconect by BMS" ;
VAL_ 626 BMS_BatteryHVILSta 3 "Error State" 2 "Close" 1 "Open" 0 "Default" ;
VAL_ 626 BMS_ModuleActiveDischarge 3 "Signal Invalid" 2 "Active Discharge" 1 "Discharge Not Active" 0 "Init/Default" ;
VAL_ 626 BMS_BContactorOffRequest 1 "Request ON" 0 "Request OFF/Default val" ;
VAL_ 626 BMS_HVILSta 1 "Open" 0 "Close" ;
VAL_ 626 BMS_PilotlineSta 3 "Signal Invalid" 2 "Reserved" 1 "DisConnected" 0 "Connected/Default" ;
VAL_ 626 BMS_IsolationFlt 3 "Signal Invalid" 2 "ON (Red)" 1 "Warning (Yellow)" 0 "OFF (Green)/Default" ;
VAL_ 626 BMS_CrashPyroFuseResponse 3 "Crash+Pyro/fuse Open" 2 "Crash+Pyro/fuse not open" 1 "No Crash+Pyro/fuse Open" 0 "No Crash+Pyro/fuse not Open" ;
VAL_ 337 BMS_BMainMinusContactorState 3 "Signal Invalid" 2 "CONTACTOR FAIL" 1 "Contactor ON(Closed)" 0 "Contactor OFF(Open)/Default" ;
VAL_ 337 BMS_PreChargeContactorSta 3 "Signal Invalid" 2 "Contactor Fail" 1 "Contactor ON (Closed)" 0 "Contactor OFF(Open) / Default" ;
VAL_ 337 BMS_BMainPlusContactorState 3 "Signal Invalid" 2 "CONTACTOR FAILED" 1 "Contactor ON(Closed)" 0 "Contactor OFF(Open)/Default" ;
VAL_ 337 BMS_Current2sensorReading 6000 "Default value" 16383 "Signal Invalid" ;
VAL_ 337 BMS_Current1sensorReading 6000 "Default value" 16383 "Signal Invalid" ;
VAL_ 1720 NM_VIN_CHECK_STS 1 "Check done" 0 "Check not done/Default" ;
VAL_ 1720 NM_MCF_DTC_STS 3 "Reserved" 2 "MCF DTC Healed State" 1 "MCF DTC Current State" 0 "Default/No DTC" ;
VAL_ 1720 NM_VIN_DTC_STS 3 "Reserved" 2 "VIN DTC Healed State" 1 "VIN DTC Current State" 0 "No DTC / Default" ;
VAL_ 1720 NM_VC_DTC_STS 3 "Reserved" 2 "VC DTC in Healed State" 1 "VC DTC in Current State" 0 "Default" ;
VAL_ 1720 NM_VBATT 0 "Default" ;
VAL_ 1720 NM_UV_STS 1 "Active" 0 "Inactive / Default" ;
VAL_ 1720 NM_STS_IGN 1 "IGN ON" 0 "IGN OFF / Default" ;
VAL_ 1720 NM_SCF_DTC_STS 3 "Reserved" 2 "SCF DTC Healed State" 1 "SCF DTC Current State" 0 "Default /No DTC" ;
VAL_ 1720 NM_OV_STS 1 "Active" 0 "Inactive / Default" ;
VAL_ 1720 NM_NA_DTC_STS 3 "Reserved" 2 "NA DTC Healed State" 1 "NA DTC Current State" 0 "Default / no DTC " ;
VAL_ 1720 NM_MTO_DTC_STS 3 "Reserved" 2 "MTO DTC in Healed State" 1 "MTO DTC in Current State" 0 "Default / No DTC" ;
VAL_ 1720 NM_FC_DTC_STS 3 "Reserved" 2 "FC DTC in Healed State" 1 "FC DTC in Current State" 0 "Default" ;
VAL_ 1720 NM_ACTIVE_STS 7 "NM ACTIVE" 6 "NM OFF at Ignition OFF" 5 "NM OFF due to Busoff" 4 "NM OFF due to OV" 3 "NM OFF due to UV" 2 "NM OFF due to Cranking T50/ESS" 1 "NM OFF due to VC" 0 "NM OFF at Ignition ON / Default" ;
VAL_ 1655 CLOCK_AM_PM 1 "AM" 0 "PM" ;
VAL_ 1655 CLOCK_FORMAT_TGU 1 "24 Hour mode" 0 "12 Hour mode / Default" ;
VAL_ 339 TGU_CHARGINGENDTIME_FORMAT 1 "PM" 0 "AM" ;
VAL_ 339 TGU_CHARGINGSTARTTIME_FORMAT 1 "PM" 0 "AM" ;
VAL_ 339 TGU_CHRG_STRT_TIME_HOURS 0 "Default" ;
VAL_ 339 TGU_ENERGYCONS 0 "Default" ;
VAL_ 339 TGU_EV_CHRG_PARAM_INDEX 1 "Index 1" 0 "Index 0" ;
VAL_ 339 TGU_CHARGINGSTARTTIME_DATE 0 "Default" ;
VAL_ 339 TGU_CHRG_START_TIME_MIN 0 "Default" ;
VAL_ 339 TGU_CHARGINGSTARTTIME_MONTH 0 "Default" ;
VAL_ 339 TGU_CHARGINGSTARTTIME_YEAR 0 "Default" ;
VAL_ 339 TGU_CHARGINGENDTIME_MIN 0 "Default" ;
VAL_ 339 TGU_CHRGING_DURATION_MIN 0 "Default" ;
VAL_ 339 TGU_CHARGINGENDTIME_YEAR 0 "Default" ;
VAL_ 339 TGU_CHRGING_DURATION_HOURS 0 "Default" ;
VAL_ 338 TGU_TRIPSTARTTIME_FORMAT 1 "PM" 0 "AM" ;
VAL_ 338 TGU_TRIPENDTIME_FORMAT 1 "PM" 0 "AM" ;
VAL_ 338 TGU_TRIPSTARTTIME_YEAR 0 "Default" ;
VAL_ 338 TGU_TRIPSTARTTIME_MIN 0 "Default" ;
VAL_ 338 TGU_TRIP_START_TIME_HOURS 0 "Default" ;
VAL_ 338 TGU_TRIPENDTIME_YEAR 0 "Default" ;
VAL_ 338 TGU_TRIPENDTIME_MONTH 0 "Default" ;
VAL_ 338 TGU_TRIPENDTIME_MIN 0 "Default" ;
VAL_ 338 TGU_TRIPENDTIME_DATE 0 "Default" ;
VAL_ 338 TGU_TRIPEFFICIENCY 3 "High" 2 "Medium" 1 "Low" 0 "Default" ;
VAL_ 338 TGU_TRIPAVGVEHICLESPEED 0 "Default" ;
VAL_ 338 TGU_TRIP_TOP_SPEED 0 "Default" ;
VAL_ 338 TGU_TRIP_START_TIME_MONTH 0 "Default" ;
VAL_ 338 TGU_TRIP_START_TIME_DATE 0 "Default" ;
VAL_ 338 TGU_TRIP_END_TIME_HOURS 0 "Default" ;
VAL_ 338 TGU_TRIP_DURATION_MIN 0 "Default" ;
VAL_ 338 TGU_TRIP_DURATION_HOURS 0 "Default" ;
VAL_ 338 TGU_TRIP_DISTANCE 0 "Default" ;
VAL_ 338 TGU_TREES_SAVED 0 "Default" ;
VAL_ 338 TGU_CO2 0 "Default" ;
VAL_ 338 TGU_EV_KILOMETERS 0 "Default" ;
VAL_ 338 TGU_FRESHDATAFLAG 1 "FreshData" 0 "Default" ;
VAL_ 338 TGU_EV_PARAM_INDEX 4 "Index 4" 3 "Index 3" 2 "Index 2" 1 "Index 1" 0 "Index 0" ;
VAL_ 1761 NM_VIN_CHECK_STS_TGU 1 "Check done" 0 "Check not done/Default" ;
VAL_ 1761 NM_VIN_DTC_STS_TGU 3 "Reserved" 2 "VIN DTC Healed State" 1 "VIN DTC Current State" 0 "No DTC / Default" ;
VAL_ 1761 NM_VC_DTC_STS_TGU 3 "Reserved" 2 "VC DTC in Healed State" 1 "VC DTC in Current State" 0 "Default" ;
VAL_ 1761 NM_MCF_DTC_STS_TGU 3 "Reserved" 2 "MCF DTC Healed State" 1 "MCF DTC Current State" 0 "Default/No DTC" ;
VAL_ 1761 NM_VBATT_TGU 0 "Default" ;
VAL_ 1761 NM_UV_STS_TGU 1 "Active" 0 "Inactive / Default" ;
VAL_ 1761 NM_STS_IGN_TGU 1 "IGN ON" 0 "IGN OFF / Default" ;
VAL_ 1761 NM_SCF_DTC_STS_TGU 3 "Reserved" 2 "SCF DTC Healed State" 1 "SCF DTC Current State" 0 "Default /No DTC" ;
VAL_ 1761 NM_OV_STS_TGU 1 "Active" 0 "Inactive / Default" ;
VAL_ 1761 NM_NA_DTC_STS_TGU 3 "Reserved" 2 "NA DTC Healed State" 1 "NA DTC Current State" 0 "Default / no DTC " ;
VAL_ 1761 NM_MTO_DTC_STS_TGU 3 "Reserved" 2 "MTO DTC in Healed State" 1 "MTO DTC in Current State" 0 "Default / No DTC" ;
VAL_ 1761 NM_FC_DTC_STS_TGU 3 "Reserved" 2 "FC DTC in Healed State" 1 "FC DTC in Current State" 0 "Default" ;
VAL_ 1761 NM_ACTIVE_STS_TGU 7 "NM ACTIVE" 6 "NM OFF at Ignition OFF" 5 "NM OFF due to Busoff" 4 "NM OFF due to OV" 3 "NM OFF due to UV" 2 "NM OFF due to Cranking T50/ESS" 1 "NM OFF due to VC" 0 "NM OFF at Ignition ON / Default" ;
VAL_ 999 BMS_BatteryMaxCellVoltage 16383 "Invalid Value" 3650 "Default Value" ;
VAL_ 999 BMS_BatteryMinCellVoltage 16383 "Invalid Value" 3650 "Default Value" ;
VAL_ 999 BMS_BatteryDisconnectSta 15 "Reserved" 14 "Reserved" 13 "Reserved" 12 "Reserved" 11 "Reserved" 10 "Reserved" 9 "Reserved" 8 "Fail - Over Battery pack current" 7 "Fail - HV diag failed" 6 "Fail - Precharge diag failed" 5 "Pass - Emergency out" 4 "Fail - Both weld" 3 "Pass - -ve weld only" 2 "Pass - +ve weld only" 1 "Pass - No Weld" 0 "Init/Default" ;
VAL_ 999 BMS_BatteryConnectSta 15 "Reserved" 14 "Reserved" 13 "Reserved" 12 "Pass - Positive & Negative OK" 11 "Fail  - Precharge closure fail" 10 "Fail - Negative contactor weld" 9 "Fail - Positive contactor weld" 8 "Fail - Both contactor weld" 7 "Fail - Fuse Open" 6 "Fail - System Related fault" 5 "Fail - HVIl " 4 "Fail - pilot line" 3 "Fail - Battery Temp Out of Range" 2 "Fail - HV coil diag fail  " 1 "Fail - Precharge coil diag fail" 0 "Init/Default" ;
VAL_ 999 BMS_BatteryAvgCellVoltage 16383 "Signal Invalid" 3650 "Default Value" ;
VAL_ 1000 BMS_BatteryPackSOH 0 "Default Value" 1023 "Signal Invalid" ;
VAL_ 1000 BMS_BatteryPackRSOC 0 "Default Value" 1023 "Signal Invalid" ;
VAL_ 1000 BMS_BatteryPackASOC 0 "Default Value" 1023 "Signal Invalid" ;
VAL_ 1652 REMOTE_HV_CONNECT_REQ_TGU 3 "Reserved" 2 "HV Connected" 1 "HV Disconnected" 0 "Default" ;
VAL_ 1652 REQ_AC_TGU 1 "ON" 0 "OFF/Default" ;
VAL_ 1652 REQ_TEMP_TGU 7 "Reserved" 6 "Reserved" 5 "Reserved" 4 "Max Heating Request" 3 "Low Heating Request" 2 "Max Cooling Request" 1 "Low Cooling Request" 0 "No Request/Default" ;
VAL_ 1652 VEH_SEARCH_REQ 3 "Search OFF" 2 "Search with Siren OFF" 1 "Search with Siren ON" 0 "No Request" ;
VAL_ 1652 CHARGING_ON_OFF_REQ 0 "DEFAULT" 1 "CHARGING ENABLE" 2 "CHARGING DISABLE" 3 "INVALID" ;
VAL_ 1652 TGU_REVIVE_REQ 0 "NO REQUEST/DEFAULT" 1 "REVIVE REQUEST" ;
VAL_ 1652 REMOTE_DOOR_LOCK_UNLOCK 3 "RESERVED" 2 "DOOR UNLOCK REQUEST" 1 "DOOR LOCK REQUEST" 0 "DEFAULT MODE" ;
VAL_ 374 ENGINE_STOP_AMT 1 "Request to stop Engine" 0 "No Request / Default" ;
VAL_ 374 TGS_MODE_AMT 3 "Signal Invalid" 2 "Warm Up" 1 "Manual" 0 "Normal / Default Value" ;
VAL_ 374 TCU_SHIFT_MODE 3 "Signal Invalid" 2 "Reserved" 1 "Automatic Mode" 0 "MAnual Mode / Default" ;
VAL_ 374 GEAR_ACTUAL_AMT 15 "Signal Invalid" 14 "Drive Lock Out (Neutral)" 13 "Drive Limp Home (4th)" 12 "Reverse Lock Out (Neutral)" 11 "Reverse Limp Home" 10 "Reverse (Electronic Engagement)" 9 "Manual 1st (+ve/-ve Torque)" 8 "Reserved" 7 "Reserved" 6 "6th" 5 "5th" 4 "4th" 3 "3rd" 2 "2nd" 1 "1st (Positive torque only)" 0 "Neutral / Default Value" ;
VAL_ 264 ALTERNATOR_CUTOFF_REQ 1 "Active" 0 "Not Active / Default" ;
VAL_ 264 ODO_ERROR_FLAG_EMS 1 "Error" 0 "No Error/Default" ;
VAL_ 264 STS_ESS_INDC 7 "Signal Invalid" 6 "Reserved" 5 "Reserved" 4 "LAmp Blink before Engine Start" 3 "Lamp blink due to Voltage Mon" 2 "Lamp blink before Engine stop" 1 "Lamp ON after Engine Stop" 0 "Lamp OFF/Default" ;
VAL_ 264 ENG_TRQ_AFTR_RED 2047 "Signal Invalid" 0 "Default" ;
VAL_ 264 INTAKE_AIR_TEMP 255 "Signal Invalid" 0 "Default" ;
VAL_ 264 STS_DPF_REGENERATION 1 "Regeneration active" 0 "Regeneration inactive/default" ;
VAL_ 264 STS_ENG_LIMP_HOME 1 "Active" 0 "Inactive/Default" ;
VAL_ 264 DRIVER_DEMAND_TRQ 2047 "Signal Invalid" 0 "Default" ;
VAL_ 264 BARO_PRS 255 "Signal Invalid" 104 "Default" ;
VAL_ 264 CLUTCH_STS 7 "Signal Invalid" 6 "Reserved" 5 "Reserved" 4 "Reserved" 3 "Reserved" 2 "90% Pressed" 1 "10% Pressed" 0 "Not Pressed / Default" ;
VAL_ 579 VCU_EVCAN_WAKEUPREASON 5 "Reserved" 4 "LV Battery Charge" 3 "Wakeup for Fast Charging" 2 "RTC Based Wake Up Trigger" 1 "Wakeup for Normal Charging" 0 "Key On /Ignition " ;
